VERSION ""

NS_ :

BS_:
BU_: Receiver ChassisBus VehicleBus PartyBus apb ui app aps bms gtwu odin cc cmp cp das dif dir di epas3p epas3s epbl epbr esp fc gtw hvp ibst ocs1p park pcs pmf pmr pm ptc radc rcm2 rcm sccm scm scs tas tpms umc vcfront vcleft vcright vcsec GTW

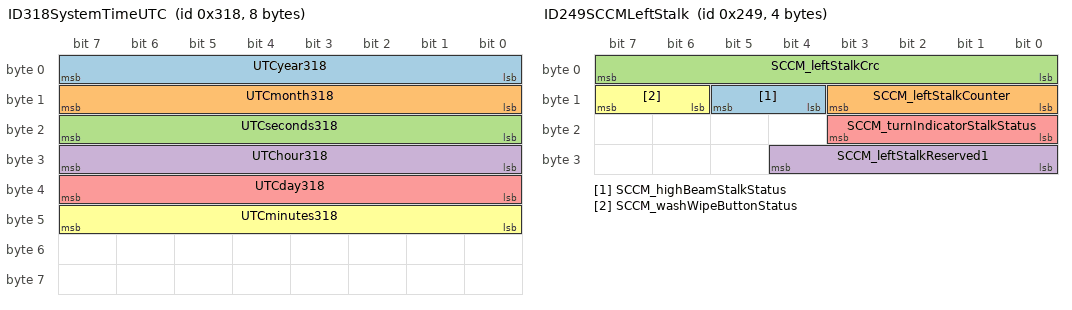
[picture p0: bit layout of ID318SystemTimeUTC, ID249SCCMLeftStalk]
BO_ 792 ID318SystemTimeUTC: 8 VehicleBus
   SG_ UTCyear318 : 0|8@1+ (1,0) [0|0] "yr" Receiver
   SG_ UTCmonth318 : 8|8@1+ (1,0) [0|0] "mo" Receiver
   SG_ UTCseconds318 : 16|8@1+ (1,0) [0|0] "sec" Receiver
   SG_ UTChour318 : 24|8@1+ (1,0) [0|0] "hr" Receiver
   SG_ UTCday318 : 32|8@1+ (1,0) [0|0] "dy" Receiver
   SG_ UTCminutes318 : 40|8@1+ (1,0) [0|0] "min" Receiver

BO_ 1320 ID528UnixTime: 4 VehicleBus
   SG_ UnixTimeSeconds528 : 7|32@0+ (1,0) [0|4.29497e+09] "sec" Receiver

BO_ 553 ID229GearLever: 3 VehicleBus
   SG_ GearLeverPosition229 : 12|3@1+ (1,0) [0|7] "" Receiver
   SG_ GearLeverButton229 : 16|2@1+ (1,0) [0|3] "" Receiver

BO_ 585 ID249SCCMLeftStalk: 4 VehicleBus
   SG_ SCCM_highBeamStalkStatus : 12|2@1+ (1,0) [0|3] "" Receiver
   SG_ SCCM_leftStalkCounter : 8|4@1+ (1,0) [0|15] "" Receiver
   SG_ SCCM_leftStalkCrc : 0|8@1+ (1,0) [0|255] "" Receiver
   SG_ SCCM_leftStalkReserved1 : 24|5@1+ (1,0) [0|31] "" Receiver
   SG_ SCCM_turnIndicatorStalkStatus : 16|4@1+ (1,0) [0|9] "" Receiver
   SG_ SCCM_washWipeButtonStatus : 14|2@1+ (1,0) [0|3] "" Receiver

BO_ 1577 ID629UDSPCStoMCU: 8 VehicleBus

BO_ 1576 ID628UDSMCUtoPCS: 8 VehicleBus

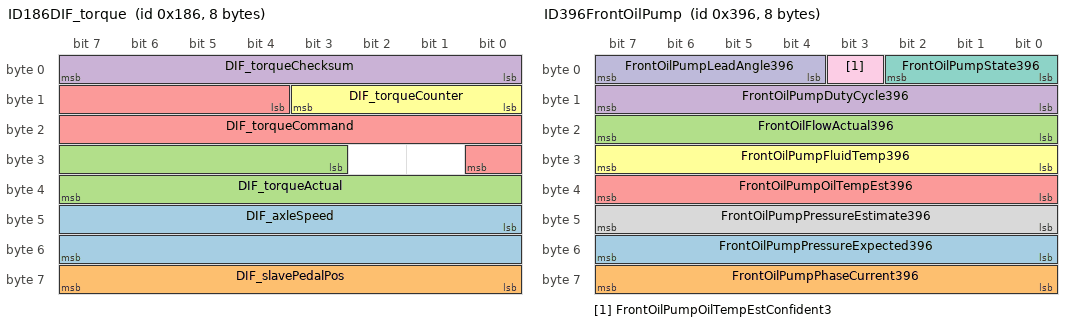
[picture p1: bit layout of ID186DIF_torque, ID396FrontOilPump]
BO_ 390 ID186DIF_torque: 8 VehicleBus
   SG_ DIF_axleSpeed : 40|16@1- (0.1,0) [-2750|2750] "RPM" Receiver
   SG_ DIF_slavePedalPos : 56|8@1+ (0.4,0) [0|100] "%" Receiver
   SG_ DIF_torqueActual : 27|13@1- (2,0) [-7500|7500] "Nm" Receiver
   SG_ DIF_torqueChecksum : 0|8@1+ (1,0) [0|255] "" Receiver
   SG_ DIF_torqueCommand : 12|13@1- (2,0) [-7500|7500] "Nm" Receiver
   SG_ DIF_torqueCounter : 8|4@1+ (1,0) [0|15] "" Receiver

BO_ 918 ID396FrontOilPump: 8 VehicleBus
   SG_ FrontOilPumpPressureExpected396 : 48|8@1+ (2,0) [0|500] "kPa" Receiver
   SG_ FrontOilPumpPhaseCurrent396 : 56|8@1+ (0.1,0) [0|25.4] "A" Receiver
   SG_ FrontOilFlowActual396 : 16|8@1+ (0.06,0) [0|15] "LPM" Receiver
   SG_ FrontOilPumpDutyCycle396 : 8|8@1+ (0.4,0) [0|100] "%" Receiver
   SG_ FrontOilPumpOilTempEst396 : 32|8@1+ (1,-40) [0|214] "C" Receiver
   SG_ FrontOilPumpFluidTemp396 : 24|8@1+ (1,-40) [0|214] "C" Receiver
   SG_ FrontOilPumpState396 : 0|3@1+ (1,0) [0|7] "" Receiver
   SG_ FrontOilPumpPressureEstimate396 : 40|8@1+ (2,0) [0|500] "kPa" Receiver
   SG_ FrontOilPumpOilTempEstConfident3 : 3|1@1+ (1,0) [0|0] "" Receiver
   SG_ FrontOilPumpLeadAngle396 : 4|4@1+ (1.875,0) [0|28.125] "deg" Receiver

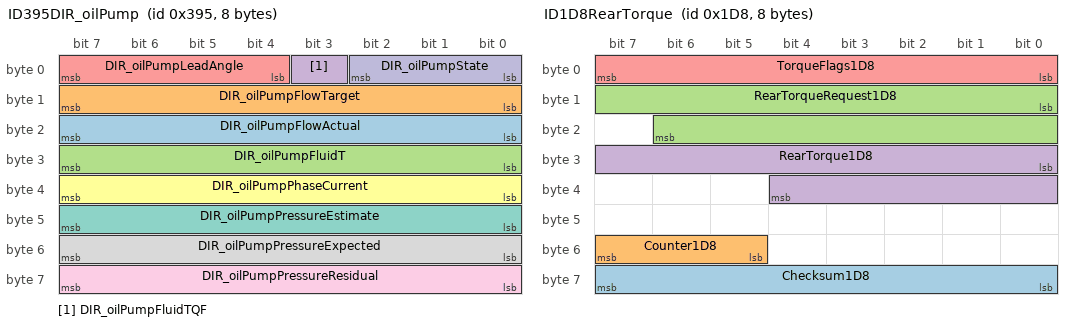
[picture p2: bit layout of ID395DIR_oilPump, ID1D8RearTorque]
BO_ 917 ID395DIR_oilPump: 8 VehicleBus
   SG_ DIR_oilPumpFlowActual : 16|8@1+ (0.06,0) [0|15] "LPM" Receiver
   SG_ DIR_oilPumpFlowTarget : 8|8@1+ (0.06,0) [0|15] "LPM" Receiver
   SG_ DIR_oilPumpFluidT : 24|8@1+ (1,-40) [-40|214] "C" Receiver
   SG_ DIR_oilPumpFluidTQF : 3|1@1+ (1,0) [0|1] "" Receiver
   SG_ DIR_oilPumpLeadAngle : 4|4@1+ (1.875,0) [0|28.125] "deg" Receiver
   SG_ DIR_oilPumpPhaseCurrent : 32|8@1+ (0.1,0) [0|25.4] "A" Receiver
   SG_ DIR_oilPumpPressureEstimate : 40|8@1+ (2,0) [0|500] "kPa" Receiver
   SG_ DIR_oilPumpPressureExpected : 48|8@1+ (2,0) [0|500] "kPa" Receiver
   SG_ DIR_oilPumpPressureResidual : 56|8@1+ (4,-500) [-500|500] "kPa" Receiver
   SG_ DIR_oilPumpState : 0|3@1+ (1,0) [0|7] "" Receiver

BO_ 472 ID1D8RearTorque: 8 VehicleBus
   SG_ Checksum1D8 : 56|8@1+ (1,0) [0|0] "" Receiver
   SG_ Counter1D8 : 53|3@1+ (1,0) [0|0] "" Receiver
   SG_ RearTorqueRequest1D8 : 8|15@1- (0.1,0) [-1638.4|1638.3] "NM" Receiver
   SG_ RearTorque1D8 : 24|13@1- (0.25,0) [-1024|1023.75] "NM" Receiver
   SG_ TorqueFlags1D8 : 0|8@1+ (1,0) [0|0] "" Receiver

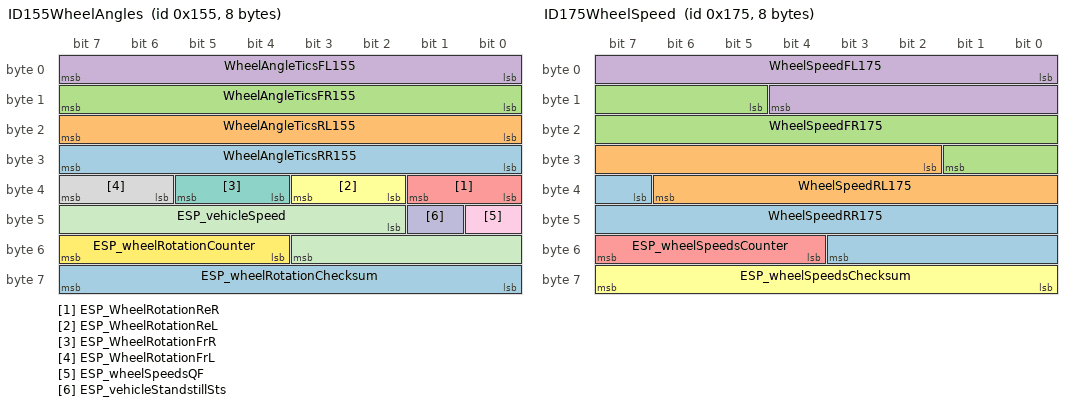
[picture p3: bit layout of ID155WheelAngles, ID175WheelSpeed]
BO_ 341 ID155WheelAngles: 8 ChassisBus
   SG_ WheelAngleTicsRR155 : 24|8@1+ (1.40625,0) [0|358.594] "deg" Receiver
   SG_ WheelAngleTicsRL155 : 16|8@1+ (1.40625,0) [0|358.594] "deg" Receiver
   SG_ WheelAngleTicsFR155 : 8|8@1+ (1.40625,0) [0|358.594] "deg" Receiver
   SG_ WheelAngleTicsFL155 : 0|8@1+ (1.40625,0) [0|358.594] "deg" Receiver
   SG_ ESP_WheelRotationReR : 32|2@1+ (1,0) [0|3] "" Receiver
   SG_ ESP_WheelRotationReL : 34|2@1+ (1,0) [0|3] "" Receiver
   SG_ ESP_WheelRotationFrR : 36|2@1+ (1,0) [0|3] "" Receiver
   SG_ ESP_WheelRotationFrL : 38|2@1+ (1,0) [0|3] "" Receiver
   SG_ ESP_wheelSpeedsQF : 40|1@1+ (1,0) [0|1] "" Receiver
   SG_ ESP_vehicleStandstillSts : 41|1@1+ (1,0) [0|1] "" Receiver
   SG_ ESP_vehicleSpeed : 42|10@1+ (0.5,0) [0|511] "kph" Receiver
   SG_ ESP_wheelRotationCounter : 52|4@1+ (1,0) [0|15] "" Receiver
   SG_ ESP_wheelRotationChecksum : 56|8@1+ (1,0) [0|255] "" Receiver

BO_ 373 ID175WheelSpeed: 8 ChassisBus
   SG_ WheelSpeedRR175 : 39|13@1+ (0.04,0) [0|327.64] "KPH" Receiver
   SG_ WheelSpeedRL175 : 26|13@1+ (0.04,0) [0|327.64] "KPH" Receiver
   SG_ WheelSpeedFR175 : 13|13@1+ (0.04,0) [0|327.64] "KPH" Receiver
   SG_ WheelSpeedFL175 : 0|13@1+ (0.04,0) [0|327.64] "KPH" Receiver
   SG_ ESP_wheelSpeedsCounter : 52|4@1+ (1,0) [0|15] "" Receiver
   SG_ ESP_wheelSpeedsChecksum : 56|8@1+ (1,0) [0|255] "" Receiver

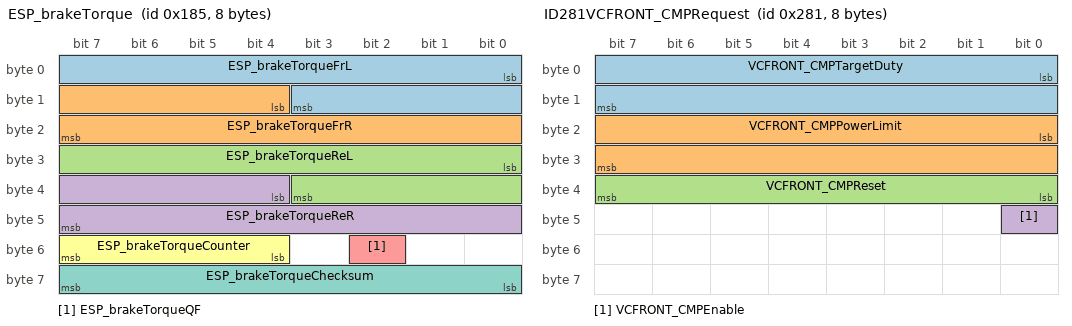
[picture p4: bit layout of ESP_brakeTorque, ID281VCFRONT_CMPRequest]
BO_ 389 ESP_brakeTorque: 8 ChassisBus
   SG_ ESP_brakeTorqueFrL : 0|12@1+ (2,0) [0|8190] "Nm" Receiver
   SG_ ESP_brakeTorqueFrR : 12|12@1+ (2,0) [0|8190] "Nm" Receiver
   SG_ ESP_brakeTorqueReL : 24|12@1+ (2,0) [0|8190] "Nm" Receiver
   SG_ ESP_brakeTorqueReR : 36|12@1+ (2,0) [0|8190] "Nm" Receiver
   SG_ ESP_brakeTorqueQF : 50|1@1+ (1,0) [0|1] "" Receiver
   SG_ ESP_brakeTorqueCounter : 52|4@1+ (1,0) [0|15] "" Receiver
   SG_ ESP_brakeTorqueChecksum : 56|8@1+ (1,0) [0|255] "" Receiver

BO_ 468 ID1D4FrontTorqueOld: 8 VehicleBus
   SG_ RAWTorqueFront1D4 : 40|12@1- (0.25,0) [-512|511.75] "NM" Receiver

BO_ 469 ID1D5FrontTorque: 8 VehicleBus
   SG_ FrontTorqueRequest1D5 : 8|15@1- (0.1,0) [-1638.4|1638.3] "NM" Receiver
   SG_ FrontTorque1D5 : 24|13@1- (0.25,0) [-1024|1023.75] "NM" Receiver

BO_ 641 ID281VCFRONT_CMPRequest: 8 VehicleBus
   SG_ VCFRONT_CMPTargetDuty : 0|16@1+ (0.1,0) [0|100] "%" Receiver
   SG_ VCFRONT_CMPPowerLimit : 16|16@1+ (1,0) [0|65534] "W" Receiver
   SG_ VCFRONT_CMPReset : 32|8@1+ (1,0) [0|255] "" Receiver
   SG_ VCFRONT_CMPEnable : 40|1@1+ (1,0) [0|1] "" Receiver

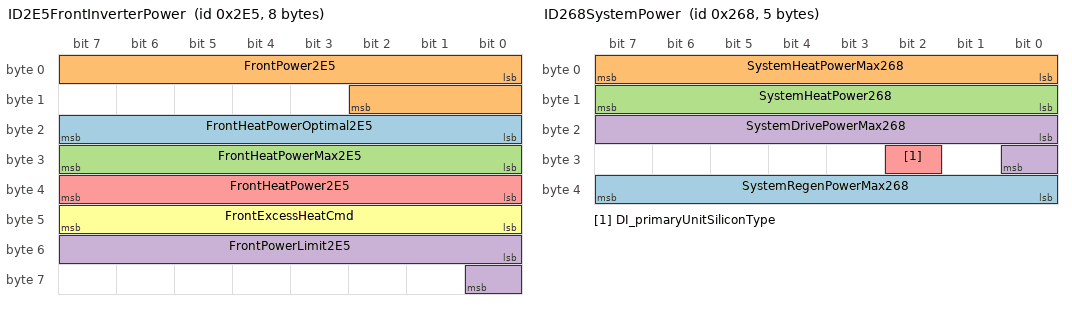
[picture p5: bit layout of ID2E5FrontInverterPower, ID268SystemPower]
BO_ 741 ID2E5FrontInverterPower: 8 VehicleBus
   SG_ FrontHeatPowerOptimal2E5 : 16|8@1+ (0.08,0) [0|20.4] "kW" Receiver
   SG_ FrontPower2E5 : 0|11@1- (0.5,0) [-512|511.5] "kW" Receiver
   SG_ FrontHeatPowerMax2E5 : 24|8@1+ (0.08,0) [0|20.4] "kW" Receiver
   SG_ FrontPowerLimit2E5 : 48|9@1+ (1,0) [0|400] "kW" Receiver
   SG_ FrontHeatPower2E5 : 32|8@1+ (0.08,0) [0|20.4] "kW" Receiver
   SG_ FrontExcessHeatCmd : 40|8@1+ (0.08,0) [0|20] "kW" Receiver

BO_ 962 ID3C2VCLEFT_switchStatus: 8 VehicleBus
   SG_ VCLEFT_switchStatusIndex M : 0|2@1+ (1,0) [0|2] "" Receiver
   SG_ VCLEFT_2RowSeatBothFoldFlatSwitc m1 : 40|1@1+ (1,0) [0|1] "" Receiver
   SG_ VCLEFT_2RowSeatCenterSwitch m1 : 37|1@1+ (1,0) [0|1] "" Receiver
   SG_ VCLEFT_2RowSeatLeftFoldFlatSwitc m1 : 38|1@1+ (1,0) [0|1] "" Receiver
   SG_ VCLEFT_2RowSeatReclineSwitch m1 : 36|1@1+ (1,0) [0|1] "" Receiver
   SG_ VCLEFT_2RowSeatRightFoldFlatSwit m1 : 39|1@1+ (1,0) [0|1] "" Receiver
   SG_ VCLEFT_brakePressed m0 : 60|1@1+ (1,0) [0|1] "" Receiver
   SG_ VCLEFT_brakeSwitchPressed m0 : 4|1@1+ (1,0) [0|1] "" Receiver
   SG_ VCLEFT_btnWindowAutoDownLR m1 : 35|1@1+ (1,0) [0|1] "" Receiver
   SG_ VCLEFT_btnWindowAutoUpLR m1 : 33|1@1+ (1,0) [0|1] "" Receiver
   SG_ VCLEFT_btnWindowDownLR m1 : 34|1@1+ (1,0) [0|1] "" Receiver
   SG_ VCLEFT_btnWindowSwPackAutoDownLF m0 : 35|1@1+ (1,0) [0|1] "" Receiver
   SG_ VCLEFT_btnWindowSwPackAutoDownLR m0 : 39|1@1+ (1,0) [0|1] "" Receiver
   SG_ VCLEFT_btnWindowSwPackAutoDownRF m0 : 43|1@1+ (1,0) [0|1] "" Receiver
   SG_ VCLEFT_btnWindowSwPackAutoDownRR m0 : 47|1@1+ (1,0) [0|1] "" Receiver
   SG_ VCLEFT_btnWindowSwPackAutoUpLF m0 : 33|1@1+ (1,0) [0|1] "" Receiver
   SG_ VCLEFT_btnWindowSwPackAutoUpLR m0 : 37|1@1+ (1,0) [0|1] "" Receiver
   SG_ VCLEFT_btnWindowSwPackAutoUpRF m0 : 41|1@1+ (1,0) [0|1] "" Receiver
   SG_ VCLEFT_btnWindowSwPackAutoUpRR m0 : 45|1@1+ (1,0) [0|1] "" Receiver
   SG_ VCLEFT_btnWindowSwPackDownLF m0 : 34|1@1+ (1,0) [0|1] "" Receiver
   SG_ VCLEFT_btnWindowSwPackDownLR m0 : 38|1@1+ (1,0) [0|1] "" Receiver
   SG_ VCLEFT_btnWindowSwPackDownRF m0 : 42|1@1+ (1,0) [0|1] "" Receiver
   SG_ VCLEFT_btnWindowSwPackDownRR m0 : 46|1@1+ (1,0) [0|1] "" Receiver
   SG_ VCLEFT_btnWindowSwPackUpLF m0 : 32|1@1+ (1,0) [0|1] "" Receiver
   SG_ VCLEFT_btnWindowSwPackUpLR m0 : 36|1@1+ (1,0) [0|1] "" Receiver
   SG_ VCLEFT_btnWindowSwPackUpRF m0 : 40|1@1+ (1,0) [0|1] "" Receiver
   SG_ VCLEFT_btnWindowSwPackUpRR m0 : 44|1@1+ (1,0) [0|1] "" Receiver
   SG_ VCLEFT_btnWindowUpLR m1 : 32|1@1+ (1,0) [0|1] "" Receiver
   SG_ VCLEFT_frontBuckleSwitch m0 : 48|2@1+ (1,0) [0|3] "" Receiver
   SG_ VCLEFT_frontOccupancySwitch m0 : 50|2@1+ (1,0) [0|3] "" Receiver
   SG_ VCLEFT_frontSeatBackrestBack m0 : 20|2@1+ (1,0) [0|3] "" Receiver
   SG_ VCLEFT_frontSeatBackrestForward m0 : 22|2@1+ (1,0) [0|3] "" Receiver
   SG_ VCLEFT_frontSeatLiftDown m0 : 16|2@1+ (1,0) [0|3] "" Receiver
   SG_ VCLEFT_frontSeatLiftUp m0 : 18|2@1+ (1,0) [0|3] "" Receiver
   SG_ VCLEFT_frontSeatLumbarDown m0 : 24|2@1+ (1,0) [0|3] "" Receiver
   SG_ VCLEFT_frontSeatLumbarIn m0 : 28|2@1+ (1,0) [0|3] "" Receiver
   SG_ VCLEFT_frontSeatLumbarOut m0 : 30|2@1+ (1,0) [0|3] "" Receiver
   SG_ VCLEFT_frontSeatLumbarUp m0 : 26|2@1+ (1,0) [0|3] "" Receiver
   SG_ VCLEFT_frontSeatTiltDown m0 : 12|2@1+ (1,0) [0|3] "" Receiver
   SG_ VCLEFT_frontSeatTiltUp m0 : 14|2@1+ (1,0) [0|3] "" Receiver
   SG_ VCLEFT_frontSeatTrackBack m0 : 8|2@1+ (1,0) [0|3] "" Receiver
   SG_ VCLEFT_frontSeatTrackForward m0 : 10|2@1+ (1,0) [0|3] "" Receiver
   SG_ VCLEFT_hazardButtonPressed m0 : 3|1@1+ (1,0) [0|1] "" Receiver
   SG_ VCLEFT_hornSwitchPressed m0 : 2|1@1+ (1,0) [0|1] "" Receiver
   SG_ VCLEFT_rearCenterBuckleSwitch m0 : 62|2@1+ (1,0) [0|3] "" Receiver
   SG_ VCLEFT_rearCenterOccupancySwitch m0 : 54|2@1+ (1,0) [0|3] "" Receiver
   SG_ VCLEFT_rearHVACButtonPressed m0 : 61|1@1+ (1,0) [0|1] "" Receiver
   SG_ VCLEFT_rearLeftBuckleSwitch m0 : 52|2@1+ (1,0) [0|3] "" Receiver
   SG_ VCLEFT_rearLeftOccupancySwitch m0 : 56|2@1+ (1,0) [0|3] "" Receiver
   SG_ VCLEFT_rearRightOccupancySwitch m0 : 58|2@1+ (1,0) [0|3] "" Receiver
   SG_ VCLEFT_rightMirrorTilt m0 : 5|3@1+ (1,0) [0|4] "" Receiver
   SG_ VCLEFT_swcLeftDoublePress m1 : 41|1@1+ (1,0) [0|1] "" Receiver
   SG_ VCLEFT_swcLeftPressed m1 : 5|2@1+ (1,0) [0|3] "" Receiver
   SG_ VCLEFT_swcLeftScrollTicks m1 : 16|6@1- (1,0) [-32|31] "" Receiver
   SG_ VCLEFT_swcLeftTiltLeft m1 : 14|2@1+ (1,0) [0|3] "" Receiver
   SG_ VCLEFT_swcLeftTiltRight m1 : 3|2@1+ (1,0) [0|3] "" Receiver
   SG_ VCLEFT_swcRightDoublePress m1 : 42|1@1+ (1,0) [0|1] "" Receiver
   SG_ VCLEFT_swcRightPressed m1 : 12|2@1+ (1,0) [0|3] "" Receiver
   SG_ VCLEFT_swcRightScrollTicks m1 : 24|6@1- (1,0) [-32|31] "" Receiver
   SG_ VCLEFT_swcRightTiltLeft m1 : 8|2@1+ (1,0) [0|3] "" Receiver
   SG_ VCLEFT_swcRightTiltRight m1 : 10|2@1+ (1,0) [0|3] "" Receiver

BO_ 822 ID336MaxPowerRating: 3 VehicleBus
   SG_ DriveRegenRating336 : 16|8@1+ (1,-100) [-100|155] "kW" Receiver
   SG_ DrivePowerRating336 : 0|10@1+ (1,0) [0|600] "kW" Receiver

BO_ 659 ID293UI_chassisControl: 8 VehicleBus
   SG_ UI_accOvertakeEnable : 16|2@1+ (1,0) [0|3] "" Receiver
   SG_ UI_aebEnable : 18|2@1+ (1,0) [0|3] "" Receiver
   SG_ UI_aesEnable : 20|2@1+ (1,0) [0|3] "" Receiver
   SG_ UI_ahlbEnable : 22|2@1+ (1,0) [0|3] "" Receiver
   SG_ UI_autoLaneChangeEnable : 24|2@1+ (1,0) [0|3] "" Receiver
   SG_ UI_autoParkRequest : 28|4@1+ (1,0) [0|15] "" Receiver
   SG_ UI_bsdEnable : 32|2@1+ (1,0) [0|3] "" Receiver
   SG_ UI_chassisControlChecksum : 56|8@1+ (1,0) [0|255] "" Receiver
   SG_ UI_chassisControlCounter : 52|4@1+ (1,0) [0|15] "" Receiver
   SG_ UI_dasDebugEnable : 14|1@1+ (1,0) [0|1] "" Receiver
   SG_ UI_distanceUnits : 13|1@1+ (1,0) [0|1] "" Receiver
   SG_ UI_fcwEnable : 34|2@1+ (1,0) [0|3] "" Receiver
   SG_ UI_fcwSensitivity : 36|2@1+ (1,0) [0|3] "" Receiver
   SG_ UI_latControlEnable : 38|2@1+ (1,0) [0|3] "" Receiver
   SG_ UI_ldwEnable : 40|2@1+ (1,0) [0|3] "" Receiver
   SG_ UI_narrowGarages : 7|1@1+ (1,0) [0|1] "" Receiver
   SG_ UI_parkBrakeRequest : 5|2@1+ (1,0) [0|3] "" Receiver
   SG_ UI_pedalSafetyEnable : 42|2@1+ (1,0) [0|3] "" Receiver
   SG_ UI_rebootAutopilot : 27|1@1+ (1,0) [0|1] "" Receiver
   SG_ UI_redLightStopSignEnable : 46|2@1+ (1,0) [0|3] "" Receiver
   SG_ UI_selfParkTune : 48|4@1+ (1,0) [0|15] "" Receiver
   SG_ UI_steeringTuneRequest : 0|2@1+ (1,0) [0|2] "" Receiver
   SG_ UI_tractionControlMode : 2|3@1+ (1,0) [0|6] "" Receiver
   SG_ UI_trailerMode : 12|1@1+ (1,0) [0|1] "" Receiver
   SG_ UI_winchModeRequest : 8|2@1+ (1,0) [0|2] "" Receiver
   SG_ UI_zeroSpeedConfirmed : 10|2@1+ (1,0) [0|3] "" Receiver

BO_ 616 ID268SystemPower: 5 VehicleBus
   SG_ SystemRegenPowerMax268 : 32|8@1+ (1,-100) [-100|155] "kW" Receiver
   SG_ SystemHeatPowerMax268 : 0|8@1+ (0.08,0) [0|31875] "kW" Receiver
   SG_ SystemHeatPower268 : 8|8@1+ (0.08,0) [0|31875] "kW" Receiver
   SG_ SystemDrivePowerMax268 : 16|9@1+ (1,0) [0|511] "kW" Receiver
   SG_ DI_primaryUnitSiliconType : 26|1@1+ (1,0) [0|1] "" Receiver

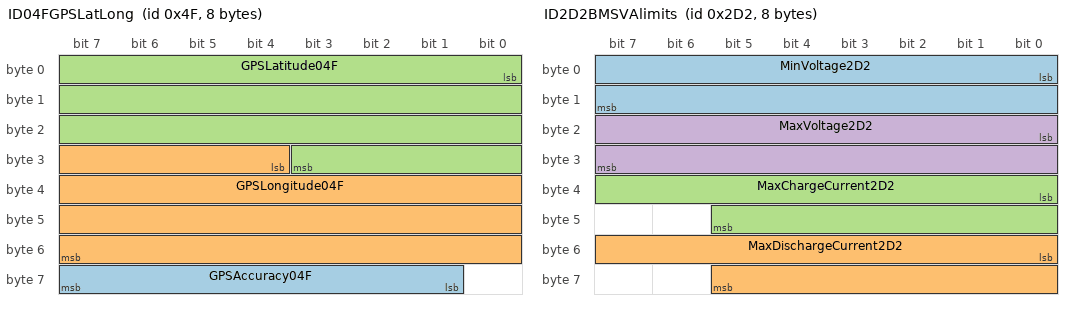
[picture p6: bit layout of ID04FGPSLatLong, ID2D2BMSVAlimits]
BO_ 79 ID04FGPSLatLong: 8 ChassisBus
   SG_ GPSAccuracy04F : 57|7@1+ (0.2,0) [0|25.2] "m" Receiver
   SG_ GPSLongitude04F : 28|28@1- (1e-06,0) [-134.218|134.218] "Deg" Receiver
   SG_ GPSLatitude04F : 0|28@1- (1e-06,0) [-134.218|134.218] "Deg" Receiver

BO_ 978 ID3D2TotalChargeDischarge: 8 VehicleBus
   SG_ TotalDischargeKWh3D2 : 0|32@1+ (0.001,0) [0|4.29497e+06] "kWh" Receiver
   SG_ TotalChargeKWh3D2 : 32|32@1+ (0.001,0) [0|4.29497e+06] "kWh" Receiver

BO_ 1010 ID3F2BMSCounters: 8 VehicleBus
   SG_ BMSCountersIndex3F2 M : 0|3@1+ (1,0) [0|0] "" Receiver
   SG_ BMStotalACcharge3F2 m0 : 8|32@1+ (0.001,0) [0|4.29497e+06] "KWh" Receiver
   SG_ BMStotalDCcharge3F2 m1 : 8|32@1+ (0.001,0) [0|4.29497e+06] "KWh" Receiver
   SG_ BMStotalRegenCharge3F2 m2 : 8|32@1+ (0.001,0) [0|4.29497e+06] "KWh" Receiver
   SG_ BMStotalDriveDischarge3F2 m3 : 8|32@1+ (0.001,0) [0|4.29497e+06] "KWh" Receiver

BO_ 722 ID2D2BMSVAlimits: 8 VehicleBus
   SG_ MinVoltage2D2 : 0|16@1+ (0.01,0) [0|430] "V" Receiver
   SG_ MaxDischargeCurrent2D2 : 48|14@1+ (0.128,0) [0|2096.9] "A" Receiver
   SG_ MaxChargeCurrent2D2 : 32|14@1+ (0.1,0) [0|1638.2] "A" Receiver
   SG_ MaxVoltage2D2 : 16|16@1+ (0.01,0) [0|430] "V" Receiver

BO_ 1345 ID541FastChargeMaxLimits: 8 VehicleBus
   SG_ FCMaxPowerLimit541 : 0|13@1+ (0.062256,0) [0|509.939] "kW" Receiver
   SG_ FCMaxCurrentLimit541 : 16|13@1+ (0.073242,0) [0|599.925] "A" Receiver

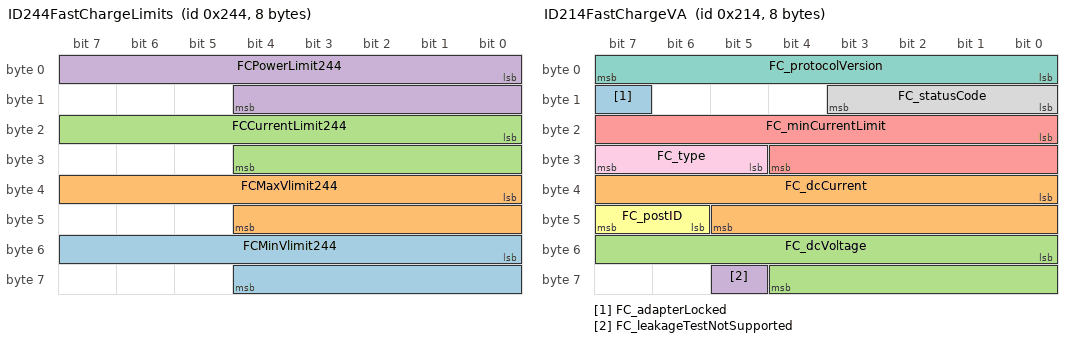
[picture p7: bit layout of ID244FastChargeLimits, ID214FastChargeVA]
BO_ 580 ID244FastChargeLimits: 8 VehicleBus
   SG_ FCMinVlimit244 : 48|13@1+ (0.073242,0) [0|599.925] "V" Receiver
   SG_ FCMaxVlimit244 : 32|13@1+ (0.073242,0) [0|599.925] "V" Receiver
   SG_ FCCurrentLimit244 : 16|13@1+ (0.073242,0) [0|599.925] "A" Receiver
   SG_ FCPowerLimit244 : 0|13@1+ (0.062256,0) [0|509.939] "kW" Receiver

BO_ 532 ID214FastChargeVA: 8 VehicleBus
   SG_ FC_adapterLocked : 15|1@1+ (1,0) [0|1] "" Receiver
   SG_ FC_dcCurrent : 32|14@1- (0.0732422,0) [-600|599.927] "A" Receiver
   SG_ FC_dcVoltage : 48|13@1+ (0.0732422,0) [0|599.927] "V" Receiver
   SG_ FC_leakageTestNotSupported : 61|1@1+ (1,0) [0|1] "" Receiver
   SG_ FC_minCurrentLimit : 16|13@1+ (0.1,0) [0|600] "A" Receiver
   SG_ FC_postID : 46|2@1+ (1,0) [0|3] "" Receiver
   SG_ FC_protocolVersion : 0|8@1+ (1,0) [0|255] "" Receiver
   SG_ FC_statusCode : 8|4@1+ (1,0) [0|15] "" Receiver
   SG_ FC_type : 29|3@1+ (1,0) [0|7] "" Receiver

BO_ 533 ID215FCisolation: 1 VehicleBus
   SG_ FCIsolation215 : 0|8@1+ (40,0) [0|10200] "kOhm" Receiver

BO_ 535 ID217FCinfo: 8 VehicleBus
   SG_ FCinfoMux217 M : 0|7@1+ (1,0) [0|127] "" Receiver
   SG_ FCclass217 m0 : 8|8@1+ (1,0) [0|255] "" Receiver
   SG_ FCbrand217 m0 : 16|4@1+ (1,0) [0|15] "" Receiver
   SG_ FCcoolingType217 m0 : 20|4@1+ (1,0) [0|15] "" Receiver
   SG_ FCuiStopType217 m0 : 24|4@1+ (1,0) [0|15] "" Receiver

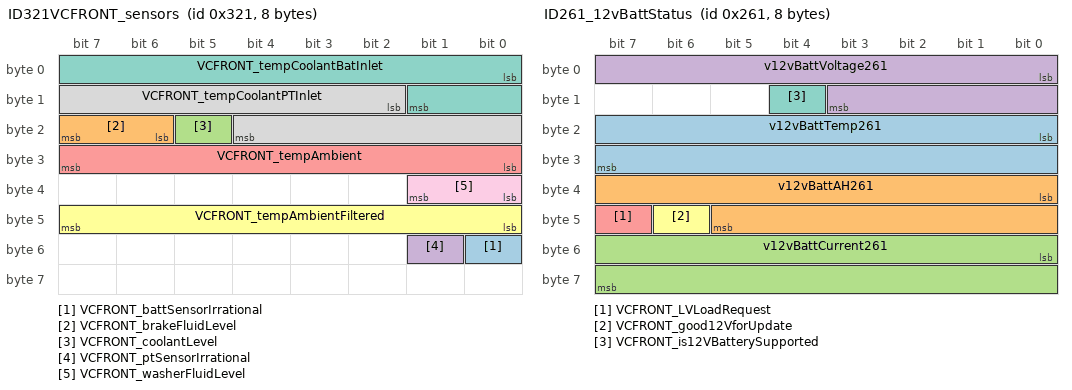
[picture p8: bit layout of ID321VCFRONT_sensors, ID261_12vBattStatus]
BO_ 801 ID321VCFRONT_sensors: 8 VehicleBus
   SG_ VCFRONT_battSensorIrrational : 48|1@1+ (1,0) [0|1] "" Receiver
   SG_ VCFRONT_brakeFluidLevel : 22|2@1+ (1,0) [0|2] "" Receiver
   SG_ VCFRONT_coolantLevel : 21|1@1+ (1,0) [0|1] "" Receiver
   SG_ VCFRONT_ptSensorIrrational : 49|1@1+ (1,0) [0|1] "" Receiver
   SG_ VCFRONT_tempAmbient : 24|8@1+ (0.5,-40) [-40|80] "C" Receiver
   SG_ VCFRONT_tempAmbientFiltered : 40|8@1+ (0.5,-40) [-40|80] "C" Receiver
   SG_ VCFRONT_tempCoolantBatInlet : 0|10@1+ (0.125,-40) [-40|85] "C" Receiver
   SG_ VCFRONT_tempCoolantPTInlet : 10|11@1+ (0.125,-40) [-40|200] "C" Receiver
   SG_ VCFRONT_washerFluidLevel : 32|2@1+ (1,0) [0|2] "" Receiver

BO_ 769 ID301VCFRONT_info: 8 VehicleBus
   SG_ VCFRONT_infoIndex M : 0|8@1+ (1,0) [0|255] "" Receiver
   SG_ VCFRONT_hcmlAppCRC m16 : 32|32@1+ (1,0) [0|4.29497e+09] "" Receiver
   SG_ VCFRONT_hcmrAppCRC m23 : 32|32@1+ (1,0) [0|4.29497e+09] "" Receiver
   SG_ VCFRONT_infoAppCrc m13 : 8|32@1+ (1,0) [0|4.29497e+09] "" Receiver
   SG_ VCFRONT_infoAppGitHash m17 : 8|56@1+ (1,0) [0|7.20576e+16] "" Receiver
   SG_ VCFRONT_infoAssemblyId m11 : 16|8@1+ (1,0) [0|255] "" Receiver
   SG_ VCFRONT_infoBootCrc m20 : 24|32@1+ (1,0) [0|4.29497e+09] "" Receiver
   SG_ VCFRONT_infoBootGitHash m18 : 8|56@1+ (1,0) [0|7.20576e+16] "" Receiver
   SG_ VCFRONT_infoBootUdsProtoVersion m20 : 8|16@1+ (1,0) [0|65535] "" Receiver
   SG_ VCFRONT_infoBuildConfigId m10 : 16|16@1+ (1,0) [0|65535] "" Receiver
   SG_ VCFRONT_infoBuildType m10 : 8|3@1+ (1,0) [0|4] "" Receiver
   SG_ VCFRONT_infoComponentId m10 : 48|16@1+ (1,0) [0|65535] "" Receiver
   SG_ VCFRONT_infoHardwareId m10 : 32|16@1+ (1,0) [0|65535] "" Receiver
   SG_ VCFRONT_infoPcbaId m11 : 8|8@1+ (1,0) [0|255] "" Receiver
   SG_ VCFRONT_infoPlatformType m19 : 8|8@1+ (1,0) [0|255] "" Receiver
   SG_ VCFRONT_infoSubUsageId m11 : 40|16@1+ (1,0) [0|65535] "" Receiver
   SG_ VCFRONT_infoSubcomponent3 m24 : 32|32@1+ (1,0) [0|4.29497e+09] "" Receiver
   SG_ VCFRONT_infoSubcomponent4 m31 : 32|32@1+ (1,0) [0|4.29497e+09] "" Receiver
   SG_ VCFRONT_infoSubcomponent5 m32 : 32|32@1+ (1,0) [0|4.29497e+09] "" Receiver
   SG_ VCFRONT_infoSubcomponent6 m33 : 32|32@1+ (1,0) [0|4.29497e+09] "" Receiver
   SG_ VCFRONT_infoUsageId m11 : 24|16@1+ (1,0) [0|65535] "" Receiver

BO_ 513 ID201VCFRONT_loggingAndVitals10H: 8 VehicleBus
   SG_ VCFRONT_loggingAndVitals10HzInde M : 0|3@1+ (1,0) [0|7] "" Receiver
   SG_ VCFRONT_activeLouverOpenPos m1 : 16|7@1+ (1,0) [0|100] "%" Receiver
   SG_ VCFRONT_activeLouverOpenPosTarg m1 : 8|7@1+ (1,0) [0|100] "%" Receiver
   SG_ VCFRONT_cclExvFlow m3 : 44|10@1+ (0.1,0) [0|100] "%" Receiver
   SG_ VCFRONT_cclExvFlowTarget m5 : 44|10@1+ (0.1,0) [0|100] "%" Receiver
   SG_ VCFRONT_cclExvState m6 : 20|4@1+ (1,0) [0|8] "" Receiver
   SG_ VCFRONT_ccrExvFlow m3 : 54|10@1+ (0.1,0) [0|100] "%" Receiver
   SG_ VCFRONT_ccrExvFlowTarget m5 : 54|10@1+ (0.1,0) [0|100] "%" Receiver
   SG_ VCFRONT_ccrExvState m6 : 24|4@1+ (1,0) [0|8] "" Receiver
   SG_ VCFRONT_chillerExvFlow m3 : 3|10@1+ (0.1,0) [0|100] "%" Receiver
   SG_ VCFRONT_chillerExvFlowTarget m5 : 3|10@1+ (0.1,0) [0|100] "%" Receiver
   SG_ VCFRONT_chillerExvState m6 : 3|4@1+ (1,0) [0|8] "" Receiver
   SG_ VCFRONT_compDemandChiller m2 : 39|7@1+ (1,0) [0|100] "%" Receiver
   SG_ VCFRONT_compDemandEvap m2 : 26|7@1+ (1,0) [0|100] "%" Receiver
   SG_ VCFRONT_compressorState m2 : 24|2@1+ (1,0) [0|3] "" Receiver
   SG_ VCFRONT_coolantValveMode m2 : 61|2@1+ (1,0) [0|3] "" Receiver
   SG_ VCFRONT_evapExvFlow m3 : 13|10@1+ (0.1,0) [0|100] "%" Receiver
   SG_ VCFRONT_evapExvFlowTarget m5 : 13|10@1+ (0.1,0) [0|100] "%" Receiver
   SG_ VCFRONT_evapExvState m6 : 8|4@1+ (1,0) [0|8] "" Receiver
   SG_ VCFRONT_exvFlowTarget m0 : 54|10@1+ (0.1,0) [0|100] "%" Receiver
   SG_ VCFRONT_exvState m2 : 33|4@1+ (1,0) [0|8] "" Receiver
   SG_ VCFRONT_fanDemand m2 : 16|7@1+ (1,0) [0|100] "%" Receiver
   SG_ VCFRONT_hpBatteryLoadType m4 : 16|2@1+ (1,0) [0|2] "" Receiver
   SG_ VCFRONT_hpBlendType m4 : 11|2@1+ (1,0) [0|2] "" Receiver
   SG_ VCFRONT_hpCabinLoadType m4 : 14|2@1+ (1,0) [0|3] "" Receiver
   SG_ VCFRONT_hpDominantLoad m4 : 8|3@1+ (1,0) [0|6] "" Receiver
   SG_ VCFRONT_hpHighSideHX m4 : 3|2@1+ (1,0) [0|3] "" Receiver
   SG_ VCFRONT_hpLowSideHX m4 : 5|2@1+ (1,0) [0|3] "" Receiver
   SG_ VCFRONT_hpQuietModeEnabled m4 : 13|1@1+ (1,0) [0|1] "" Receiver
   SG_ VCFRONT_hpReqCoolantMode m4 : 18|3@1+ (1,0) [0|4] "" Receiver
   SG_ VCFRONT_lccExvFlow m3 : 34|10@1+ (0.1,0) [0|100] "%" Receiver
   SG_ VCFRONT_lccExvFlowTarget m5 : 34|10@1+ (0.1,0) [0|100] "%" Receiver
   SG_ VCFRONT_lccExvState m6 : 16|4@1+ (1,0) [0|8] "" Receiver
   SG_ VCFRONT_pressureRefrigDischargeV m2 : 53|8@1+ (0.125,0) [0|31.75] "bar" Receiver
   SG_ VCFRONT_pressureRefrigLiquid m1 : 40|8@1+ (0.125,0) [0|31.75] "bar" Receiver
   SG_ VCFRONT_pressureRefrigSuctionVit m2 : 46|7@1+ (0.125,0) [0|11.5] "bar" Receiver
   SG_ VCFRONT_pumpBatteryRPMActual m0 : 3|10@1+ (10,0) [0|10000] "rpm" Receiver
   SG_ VCFRONT_pumpPowertrainRPMActual m0 : 13|10@1+ (10,0) [0|10000] "rpm" Receiver
   SG_ VCFRONT_radiatorFanRPMActual m0 : 24|10@1+ (10,0) [0|10000] "rpm" Receiver
   SG_ VCFRONT_recircExvFlow m3 : 24|10@1+ (0.1,0) [0|100] "%" Receiver
   SG_ VCFRONT_recircExvFlowTarget m5 : 24|10@1+ (0.1,0) [0|100] "%" Receiver
   SG_ VCFRONT_recircExvState m6 : 12|4@1+ (1,0) [0|8] "" Receiver
   SG_ VCFRONT_solenoidEvapState m2 : 37|2@1+ (1,0) [0|3] "" Receiver
   SG_ VCFRONT_tempRefrigDischarge m2 : 3|11@1+ (0.125,-40) [-40|150] "C" Receiver
   SG_ VCFRONT_tempRefrigLiquid m1 : 24|11@1+ (0.125,-40) [-40|150] "C" Receiver
   SG_ VCFRONT_tempSuperheatActFiltered m1 : 48|8@1- (0.25,26.5) [-5|58] "C" Receiver
   SG_ VCFRONT_tempSuperheatActual m0 : 34|10@1+ (0.1,-20) [-20|80] "C" Receiver
   SG_ VCFRONT_tempSuperheatTarget m0 : 44|10@1+ (0.1,0) [0|60] "C" Receiver

BO_ 984 ID3D8Elevation: 2 VehicleBus
   SG_ Elevation3D8 : 0|14@1- (1,0) [-8192|8191] "M" Receiver

BO_ 609 ID261_12vBattStatus: 8 VehicleBus
   SG_ v12vBattTemp261 : 16|16@1- (0.01,0) [-327.68|327.66] "C" Receiver
   SG_ v12vBattAH261 : 32|14@1- (0.005,0) [-40.96|40.955] "AH" Receiver
   SG_ v12vBattCurrent261 : 48|16@1- (0.005,0) [-163.84|163.835] "A" Receiver
   SG_ v12vBattVoltage261 : 0|12@1+ (0.00544368,0) [0|22.2919] "V" Receiver
   SG_ VCFRONT_LVLoadRequest : 47|1@1+ (1,0) [0|1] "" Receiver
   SG_ VCFRONT_good12VforUpdate : 46|1@1+ (1,0) [0|1] "" Receiver
   SG_ VCFRONT_is12VBatterySupported : 12|1@1+ (1,0) [0|1] "" Receiver

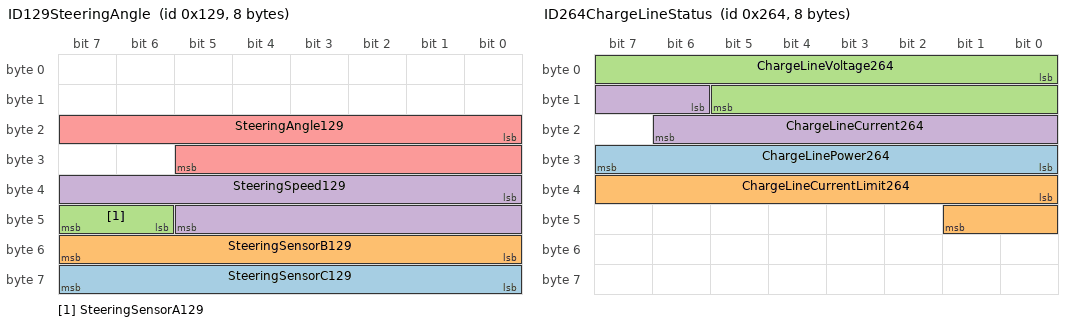
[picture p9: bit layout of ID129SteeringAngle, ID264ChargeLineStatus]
BO_ 297 ID129SteeringAngle: 8 VehicleBus
   SG_ SteeringSensorC129 : 56|8@1+ (1,0) [0|255] "" Receiver
   SG_ SteeringSensorB129 : 48|8@1+ (1,0) [0|255] "" Receiver
   SG_ SteeringSensorA129 : 46|2@1+ (1,0) [0|3] "" Receiver
   SG_ SteeringSpeed129 : 32|14@1+ (0.5,-4096) [-4096|4095.5] "D/S" Receiver
   SG_ SteeringAngle129 : 16|14@1+ (0.1,-819.2) [-819.2|819.1] "Deg" Receiver

BO_ 612 ID264ChargeLineStatus: 8 VehicleBus
   SG_ ChargeLinePower264 : 24|8@1+ (0.1,0) [0|25.5] "kW" Receiver
   SG_ ChargeLineCurrentLimit264 : 32|10@1+ (0.1,0) [0|102.3] "A" Receiver
   SG_ ChargeLineVoltage264 : 0|14@1+ (0.0333,0) [0|545.554] "V" Receiver
   SG_ ChargeLineCurrent264 : 14|9@1+ (0.1,0) [0|51.1] "A" Receiver

BO_ 548 ID224PCSDCDCstatus: 8 VehicleBus
   SG_ DCDC12VSupportRtyCnt224 : 44|4@1+ (1,0) [0|0] "" Receiver
   SG_ DCDC12VSupportStatus224 : 2|2@1+ (1,0) [0|0] "" Receiver
   SG_ DCDCDischargeRtyCnt224 : 48|4@1+ (1,0) [0|0] "" Receiver
   SG_ DCDCFaulted224 : 15|1@1+ (1,0) [0|0] "" Receiver
   SG_ DCDCHvBusDischargeStatus224 : 4|2@1+ (1,0) [0|0] "" Receiver
   SG_ DCDCInitialPrechargeSubState224 : 59|5@1+ (1,0) [0|0] "" Receiver
   SG_ DCDCoutputCurrent224 : 16|12@1+ (0.1,0) [0|409.5] "A" Receiver
   SG_ DCDCstate224 : 6|4@1+ (1,0) [0|0] "" Receiver
   SG_ DCDCoutputCurrentMax224 : 29|12@1+ (0.1,0) [0|409.5] "A" Receiver
   SG_ DCDCOutputIsLimited224 : 28|1@1+ (1,0) [0|0] "" Receiver
   SG_ DCDCPrechargeRestartCnt224 : 56|3@1+ (1,0) [0|0] "" Receiver
   SG_ DCDCPrechargeRtyCnt224 : 41|3@1+ (1,0) [0|0] "" Receiver
   SG_ DCDCPrechargeStatus224 : 0|2@1+ (1,0) [0|0] "" Receiver
   SG_ DCDCPwmEnableLine224 : 52|1@1+ (1,0) [0|0] "" Receiver
   SG_ DCDCSubState224 : 10|5@1+ (1,0) [0|0] "" Receiver
   SG_ DCDCSupportingFixedLvTarget224 : 53|1@1+ (1,0) [0|0] "" Receiver
   SG_ PCS_ecuLogUploadRequest224 : 54|2@1+ (1,0) [0|0] "" Receiver

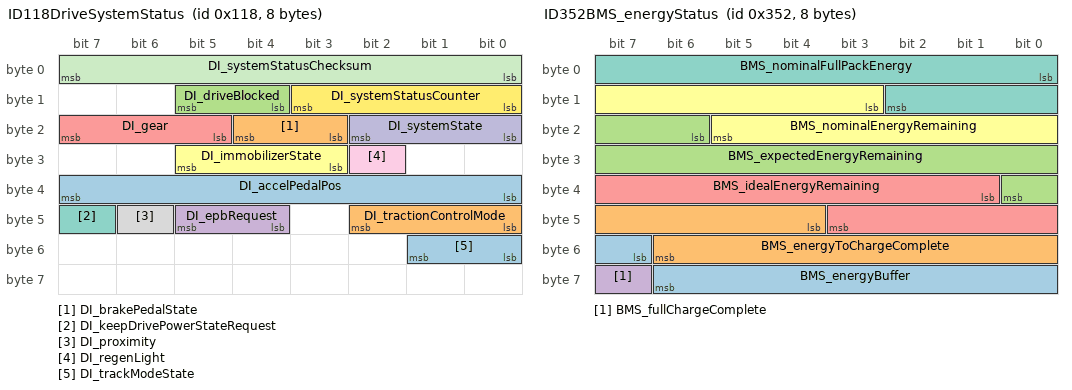
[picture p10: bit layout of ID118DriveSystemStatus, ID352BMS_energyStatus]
BO_ 280 ID118DriveSystemStatus: 8 VehicleBus
   SG_ DI_accelPedalPos : 32|8@1+ (0.4,0) [0|100] "%" Receiver
   SG_ DI_brakePedalState : 19|2@1+ (1,0) [0|2] "" Receiver
   SG_ DI_driveBlocked : 12|2@1+ (1,0) [0|2] "" Receiver
   SG_ DI_epbRequest : 44|2@1+ (1,0) [0|2] "" Receiver
   SG_ DI_gear : 21|3@1+ (1,0) [0|7] "" Receiver
   SG_ DI_immobilizerState : 27|3@1+ (1,0) [0|6] "" Receiver
   SG_ DI_keepDrivePowerStateRequest : 47|1@1+ (1,0) [0|1] "" Receiver
   SG_ DI_proximity : 46|1@1+ (1,0) [0|1] "" Receiver
   SG_ DI_regenLight : 26|1@1+ (1,0) [0|1] "" Receiver
   SG_ DI_systemState : 16|3@1+ (1,0) [0|5] "" Receiver
   SG_ DI_systemStatusChecksum : 0|8@1+ (1,0) [0|255] "" Receiver
   SG_ DI_systemStatusCounter : 8|4@1+ (1,0) [0|15] "" Receiver
   SG_ DI_trackModeState : 48|2@1+ (1,0) [0|2] "" Receiver
   SG_ DI_tractionControlMode : 40|3@1+ (1,0) [0|6] "" Receiver

BO_ 850 ID352BMS_energyStatus: 8 VehicleBus
   SG_ BMS_energyBuffer : 55|8@1+ (0.1,0) [0|25.4] "KWh" Receiver
   SG_ BMS_energyToChargeComplete : 44|11@1+ (0.1,0) [0|204.6] "KWh" Receiver
   SG_ BMS_expectedEnergyRemaining : 22|11@1+ (0.1,0) [0|204.6] "KWh" Receiver
   SG_ BMS_fullChargeComplete : 63|1@1+ (1,0) [0|1] "" Receiver
   SG_ BMS_idealEnergyRemaining : 33|11@1+ (0.1,0) [0|204.6] "KWh" Receiver
   SG_ BMS_nominalEnergyRemaining : 11|11@1+ (0.1,0) [0|204.6] "KWh" Receiver
   SG_ BMS_nominalFullPackEnergy : 0|11@1+ (0.1,0) [0|204.6] "KWh" Receiver

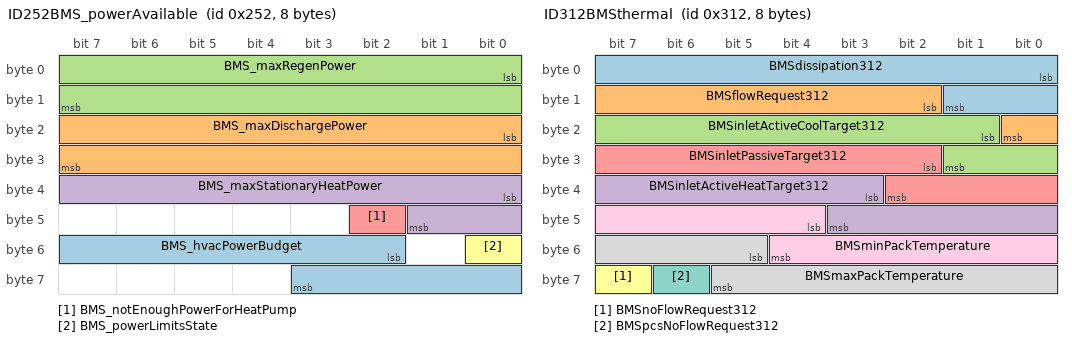
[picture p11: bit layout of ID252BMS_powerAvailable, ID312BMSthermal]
BO_ 594 ID252BMS_powerAvailable: 8 VehicleBus
   SG_ BMS_hvacPowerBudget : 50|10@1+ (0.02,0) [0|20.46] "kW" Receiver
   SG_ BMS_maxDischargePower : 16|16@1+ (0.01,0) [0|655.35] "kW" Receiver
   SG_ BMS_maxRegenPower : 0|16@1+ (0.01,0) [0|655.35] "kW" Receiver
   SG_ BMS_maxStationaryHeatPower : 32|10@1+ (0.01,0) [0|10.23] "kW" Receiver
   SG_ BMS_notEnoughPowerForHeatPump : 42|1@1+ (1,0) [0|1] "" Receiver
   SG_ BMS_powerLimitsState : 48|1@1+ (1,0) [0|1] "" Receiver

BO_ 786 ID312BMSthermal: 8 VehicleBus
   SG_ BMSdissipation312 : 0|10@1+ (0.02,0) [0|20] "kW" Receiver
   SG_ BMSflowRequest312 : 10|7@1+ (0.3,0) [0|30] "LPM" Receiver
   SG_ BMSinletActiveCoolTarget312 : 17|9@1+ (0.25,-25) [-25|100] "C" Receiver
   SG_ BMSinletActiveHeatTarget312 : 35|9@1+ (0.25,-25) [-25|100] "C" Receiver
   SG_ BMSinletPassiveTarget312 : 26|9@1+ (0.25,-25) [-25|100] "C" Receiver
   SG_ BMSnoFlowRequest312 : 63|1@1+ (1,0) [0|1] "" Receiver
   SG_ BMSpcsNoFlowRequest312 : 62|1@1+ (1,0) [0|1] "" Receiver
   SG_ BMSmaxPackTemperature : 53|9@1+ (0.25,-25) [-25|100] "C" Receiver
   SG_ BMSminPackTemperature : 44|9@1+ (0.25,-25) [-25|100] "C" Receiver

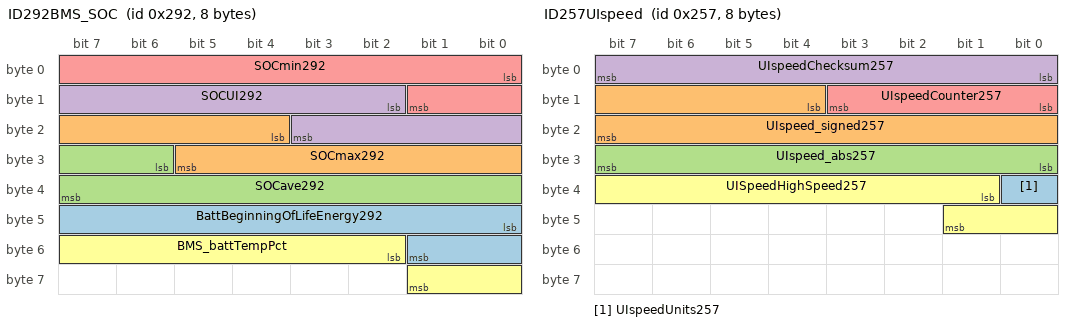
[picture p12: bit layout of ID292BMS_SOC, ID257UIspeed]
BO_ 658 ID292BMS_SOC: 8 VehicleBus
   SG_ BattBeginningOfLifeEnergy292 : 40|10@1+ (0.1,0) [0|102.3] "kWh" Receiver
   SG_ SOCmax292 : 20|10@1+ (0.1,0) [0|102.3] "%" Receiver
   SG_ SOCave292 : 30|10@1+ (0.1,0) [0|102.3] "%" Receiver
   SG_ SOCUI292 : 10|10@1+ (0.1,0) [0|102.3] "%" Receiver
   SG_ SOCmin292 : 0|10@1+ (0.1,0) [0|102.3] "%" Receiver
   SG_ BMS_battTempPct : 50|8@1+ (0.4,0) [0|100] "%" Receiver

BO_ 599 ID257UIspeed: 8 VehicleBus
   SG_ UIspeedUnits257 : 32|1@1+ (1,0) [0|0] "" Receiver
   SG_ UIspeed_signed257 : 12|12@1+ (0.08,-40) [-40|287.6] "KPH" Receiver
   SG_ UIspeed_abs257 : 24|8@1+ (1,0) [0|255] "MPHKPH" Receiver
   SG_ UIspeedChecksum257 : 0|8@1+ (1,0) [0|0] "" Receiver
   SG_ UIspeedCounter257 : 8|4@1+ (1,0) [0|0] "" Receiver
   SG_ UISpeedHighSpeed257 : 33|9@1+ (1,0) [0|510] "MPHKPH" Receiver

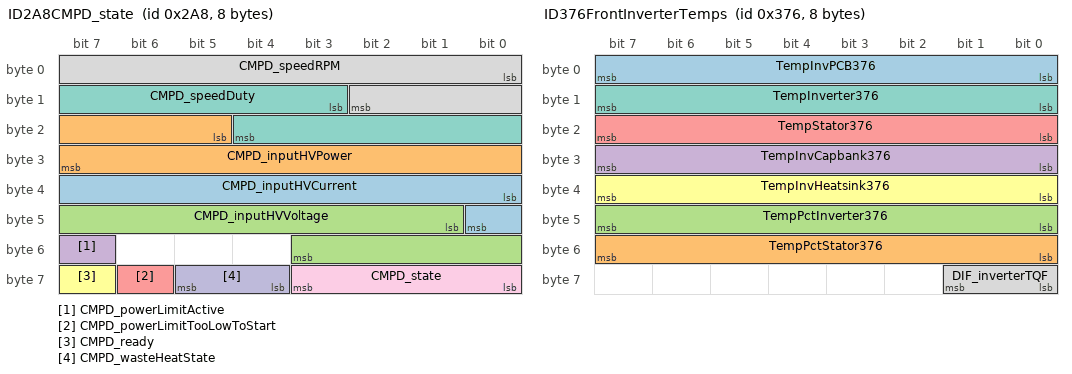
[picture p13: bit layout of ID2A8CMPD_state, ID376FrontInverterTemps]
BO_ 680 ID2A8CMPD_state: 8 VehicleBus
   SG_ CMPD_inputHVCurrent : 32|9@1+ (0.1,0) [0|50] "A" Receiver
   SG_ CMPD_inputHVPower : 21|11@1+ (10,0) [0|20000] "W" Receiver
   SG_ CMPD_inputHVVoltage : 41|11@1+ (0.5,0) [0|1000] "V" Receiver
   SG_ CMPD_powerLimitActive : 55|1@1+ (1,0) [0|1] "" Receiver
   SG_ CMPD_powerLimitTooLowToStart : 62|1@1+ (1,0) [0|1] "" Receiver
   SG_ CMPD_ready : 63|1@1+ (1,0) [0|1] "" Receiver
   SG_ CMPD_speedDuty : 11|10@1+ (0.1,0) [0|100] "%" Receiver
   SG_ CMPD_speedRPM : 0|11@1+ (10,0) [0|20000] "RPM" Receiver
   SG_ CMPD_state : 56|4@1+ (1,0) [0|15] "" Receiver
   SG_ CMPD_wasteHeatState : 60|2@1+ (1,0) [0|3] "" Receiver

BO_ 1029 ID405VIN: 8 VehicleBus
   SG_ VINB405 m17 : 8|56@1+ (1,0) [0|7.20576e+16] "" Receiver
   SG_ VINC405 m18 : 8|56@1+ (1,0) [0|7.20576e+16] "" Receiver
   SG_ VINA405 m16 : 8|56@1+ (1,0) [0|7.20576e+16] "" Receiver
   SG_ mux405 M : 0|8@1+ (1,0) [0|255] "" Receiver

BO_ 1310 ID51EFC_info: 8 VehicleBus
   SG_ FC_infoIndex M : 0|8@1+ (1,0) [0|255] "" Receiver
   SG_ FC_infoAppGitHashBytes m17 : 8|56@1+ (1,0) [0|7.20576e+16] "" Receiver
   SG_ FC_infoApplicationCRC m13 : 32|32@1+ (1,0) [0|4.29497e+09] "" Receiver
   SG_ FC_infoAssemblyID m11 : 24|8@1+ (1,0) [0|255] "" Receiver
   SG_ FC_infoBootCRC m15 : 32|32@1+ (1,0) [0|4.29497e+09] "" Receiver
   SG_ FC_infoBootGitHashBytes m18 : 8|56@1+ (1,0) [0|7.20576e+16] "" Receiver
   SG_ FC_infoBootSvnRev m14 : 8|24@1+ (1,0) [0|1.67772e+07] "" Receiver
   SG_ FC_infoBootUdsProtoVersion m20 : 8|8@1+ (1,0) [0|255] "" Receiver
   SG_ FC_infoBranchOrigin m19 : 24|8@1+ (1,0) [0|255] "" Receiver
   SG_ FC_infoBuildConfigID m10 : 16|8@1+ (1,0) [0|255] "" Receiver
   SG_ FC_infoBuildType m10 : 8|3@1+ (1,0) [0|4] "" Receiver
   SG_ FC_infoCPLDVersionMajor m16 : 16|8@1+ (1,0) [0|255] "" Receiver
   SG_ FC_infoCPLDVersionMinor m16 : 24|8@1+ (1,0) [0|255] "" Receiver
   SG_ FC_infoComponentID m10 : 48|16@1+ (1,0) [0|65535] "" Receiver
   SG_ FC_infoHardwareID m10 : 32|16@1+ (1,0) [0|65535] "" Receiver
   SG_ FC_infoHardwareRevision m19 : 40|8@1+ (1,0) [0|255] "" Receiver
   SG_ FC_infoMajorVersion m19 : 16|8@1+ (1,0) [0|255] "" Receiver
   SG_ FC_infoMaturity m19 : 32|8@1+ (1,0) [0|255] "" Receiver
   SG_ FC_infoPcbaID m11 : 16|8@1+ (1,0) [0|255] "" Receiver
   SG_ FC_infoPlatformType m19 : 8|8@1+ (1,0) [0|255] "" Receiver
   SG_ FC_infoSubUsageID m11 : 48|16@1+ (1,0) [0|65535] "" Receiver
   SG_ FC_infoUsageID m11 : 32|16@1+ (1,0) [0|65535] "" Receiver
   SG_ FC_infoVariantCRC m22 : 32|32@1+ (1,0) [0|4.29497e+09] "" Receiver
   SG_ FC_partNumChar01 m25 : 8|8@1+ (1,0) [0|1] "" Receiver
   SG_ FC_partNumChar02 m25 : 16|8@1+ (1,0) [0|1] "" Receiver
   SG_ FC_partNumChar03 m25 : 24|8@1+ (1,0) [0|1] "" Receiver
   SG_ FC_partNumChar04 m25 : 32|8@1+ (1,0) [0|1] "" Receiver
   SG_ FC_partNumChar05 m25 : 40|8@1+ (1,0) [0|1] "" Receiver
   SG_ FC_partNumChar06 m25 : 48|8@1+ (1,0) [0|1] "" Receiver
   SG_ FC_partNumChar07 m25 : 56|8@1+ (1,0) [0|1] "" Receiver
   SG_ FC_partNumChar08 m26 : 8|8@1+ (1,0) [0|1] "" Receiver
   SG_ FC_partNumChar09 m26 : 16|8@1+ (1,0) [0|1] "" Receiver
   SG_ FC_partNumChar10 m26 : 24|8@1+ (1,0) [0|1] "" Receiver
   SG_ FC_partNumChar11 m26 : 32|8@1+ (1,0) [0|1] "" Receiver
   SG_ FC_partNumChar12 m26 : 40|8@1+ (1,0) [0|1] "" Receiver
   SG_ FC_partNumChar13 m26 : 48|8@1+ (1,0) [0|1] "" Receiver
   SG_ FC_partNumChar14 m26 : 56|8@1+ (1,0) [0|1] "" Receiver
   SG_ FC_partNumChar15 m27 : 8|8@1+ (1,0) [0|1] "" Receiver
   SG_ FC_partNumChar16 m27 : 16|8@1+ (1,0) [0|1] "" Receiver
   SG_ FC_partNumChar17 m27 : 24|8@1+ (1,0) [0|1] "" Receiver
   SG_ FC_partNumChar18 m27 : 32|8@1+ (1,0) [0|1] "" Receiver
   SG_ FC_partNumChar19 m27 : 40|8@1+ (1,0) [0|1] "" Receiver
   SG_ FC_partNumChar20 m27 : 48|8@1+ (1,0) [0|1] "" Receiver

BO_ 886 ID376FrontInverterTemps: 8 VehicleBus
   SG_ TempInvPCB376 : 0|8@1+ (1,-40) [-40|215] "C" Receiver
   SG_ TempPctStator376 : 48|8@1+ (0.4,0) [0|102] "%" Receiver
   SG_ TempPctInverter376 : 40|8@1+ (0.4,0) [0|102] "%" Receiver
   SG_ TempInvCapbank376 : 24|8@1+ (1,-40) [-40|215] "C" Receiver
   SG_ TempStator376 : 16|8@1+ (1,-40) [-40|215] "C" Receiver
   SG_ TempInvHeatsink376 : 32|8@1+ (1,-40) [-40|215] "C" Receiver
   SG_ TempInverter376 : 8|8@1+ (1,-40) [-40|215] "C" Receiver
   SG_ DIF_inverterTQF : 56|2@1+ (1,0) [0|3] "" Receiver

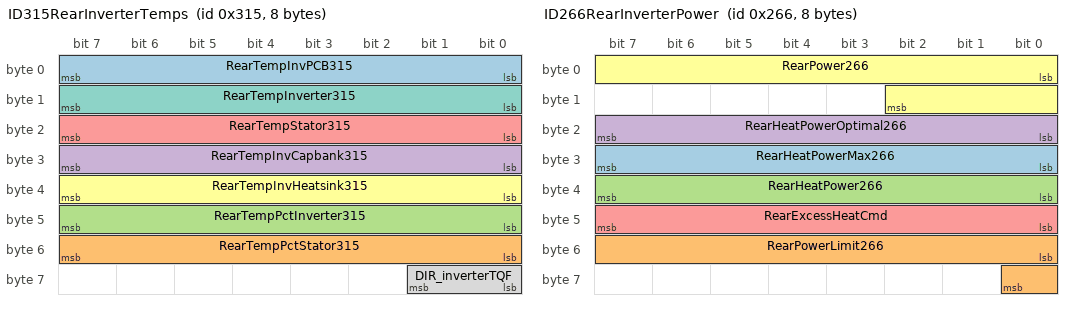
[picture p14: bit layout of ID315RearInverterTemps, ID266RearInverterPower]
BO_ 789 ID315RearInverterTemps: 8 VehicleBus
   SG_ RearTempInvPCB315 : 0|8@1+ (1,-40) [-40|215] "C" Receiver
   SG_ RearTempPctStator315 : 48|8@1+ (0.4,0) [0|102] "%" Receiver
   SG_ RearTempPctInverter315 : 40|8@1+ (0.4,0) [0|102] "%" Receiver
   SG_ RearTempInvCapbank315 : 24|8@1+ (1,-40) [-40|215] "C" Receiver
   SG_ RearTempStator315 : 16|8@1+ (1,-40) [-40|215] "C" Receiver
   SG_ RearTempInvHeatsink315 : 32|8@1+ (1,-40) [-40|215] "C" Receiver
   SG_ RearTempInverter315 : 8|8@1+ (1,-40) [-40|215] "C" Receiver
   SG_ DIR_inverterTQF : 56|2@1+ (1,0) [0|3] "" Receiver

BO_ 340 ID154RearTorqueOld: 8 VehicleBus
   SG_ RAWTorqueRear154 : 40|12@1- (0.25,0) [-512|511.75] "NM" Receiver

BO_ 950 ID3B6odometer: 4 VehicleBus
   SG_ Odometer3B6 : 0|32@1+ (0.001,0) [0|4.29497e+06] "KM" Receiver

BO_ 614 ID266RearInverterPower: 8 VehicleBus
   SG_ RearHeatPowerMax266 : 24|8@1+ (0.08,0) [0|20] "kW" Receiver
   SG_ RearPowerLimit266 : 48|9@1+ (1,0) [0|400] "kW" Receiver
   SG_ RearHeatPower266 : 32|8@1+ (0.08,0) [0|20] "kW" Receiver
   SG_ RearHeatPowerOptimal266 : 16|8@1+ (0.08,0) [0|20] "kW" Receiver
   SG_ RearExcessHeatCmd : 40|8@1+ (0.08,0) [0|20] "kW" Receiver
   SG_ RearPower266 : 0|11@1- (0.5,0) [-500|500] "kW" Receiver

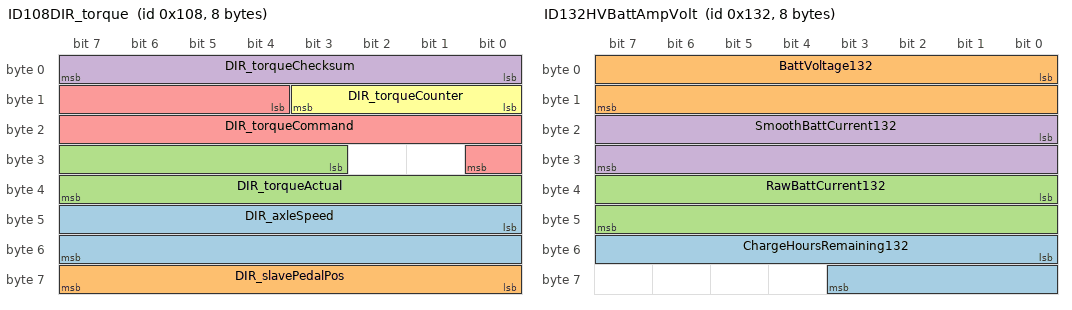
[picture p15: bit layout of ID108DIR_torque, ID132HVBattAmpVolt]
BO_ 264 ID108DIR_torque: 8 VehicleBus
   SG_ DIR_axleSpeed : 40|16@1- (0.1,0) [-2750|2750] "RPM" Receiver
   SG_ DIR_slavePedalPos : 56|8@1+ (0.4,0) [0|100] "%" Receiver
   SG_ DIR_torqueActual : 27|13@1- (2,0) [-7500|7500] "Nm" Receiver
   SG_ DIR_torqueChecksum : 0|8@1+ (1,0) [0|255] "" Receiver
   SG_ DIR_torqueCommand : 12|13@1- (2,0) [-7500|7500] "Nm" Receiver
   SG_ DIR_torqueCounter : 8|4@1+ (1,0) [0|15] "" Receiver

BO_ 306 ID132HVBattAmpVolt: 8 VehicleBus
   SG_ ChargeHoursRemaining132 : 48|12@1+ (1,0) [0|4095] "Min" Receiver
   SG_ BattVoltage132 : 0|16@1+ (0.01,0) [0|655.35] "V" Receiver
   SG_ RawBattCurrent132 : 32|16@1- (-0.05,500) [-1138.35|2138.4] "A" Receiver
   SG_ SmoothBattCurrent132 : 16|16@1- (-0.1,0) [-3276.7|3276.7] "A" Receiver

BO_ 294 ID126RearHVStatus: 3 VehicleBus
   SG_ RearHighVoltage126 : 0|10@1+ (0.5,0) [0|500] "V" Receiver
   SG_ RearMotorCurrent126 : 10|11@1+ (1,0) [0|2047] "A" Receiver

BO_ 421 ID1A5FrontHVStatus: 3 VehicleBus
   SG_ FrontHighVoltage1A5 : 0|10@1+ (0.5,0) [0|500] "V" Receiver
   SG_ FrontMotorCurrent1A5 : 10|11@1+ (1,0) [0|2047] "A" Receiver

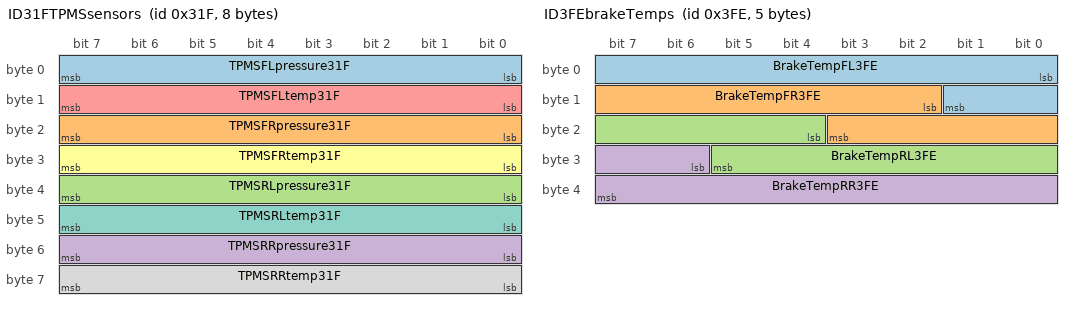
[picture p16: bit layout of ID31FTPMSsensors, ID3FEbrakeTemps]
BO_ 799 ID31FTPMSsensors: 8 ChassisBus
   SG_ TPMSFLpressure31F : 0|8@1+ (0.025,0) [0|6.375] "bar" Receiver
   SG_ TPMSFRpressure31F : 16|8@1+ (0.025,0) [0|6.375] "bar" Receiver
   SG_ TPMSRLpressure31F : 32|8@1+ (0.025,0) [0|6.375] "bar" Receiver
   SG_ TPMSRRpressure31F : 48|8@1+ (0.025,0) [0|6.375] "bar" Receiver
   SG_ TPMSFLtemp31F : 8|8@1+ (1,-40) [-40|215] "C" Receiver
   SG_ TPMSFRtemp31F : 24|8@1+ (1,-40) [-40|215] "C" Receiver
   SG_ TPMSRLtemp31F : 40|8@1+ (1,-40) [-40|215] "C" Receiver
   SG_ TPMSRRtemp31F : 56|8@1+ (1,-40) [-40|215] "C" Receiver

BO_ 1022 ID3FEbrakeTemps: 5 VehicleBus
   SG_ BrakeTempFL3FE : 0|10@1+ (1,-40) [0|0] "C" Receiver
   SG_ BrakeTempFR3FE : 10|10@1+ (1,-40) [0|0] "C" Receiver
   SG_ BrakeTempRL3FE : 20|10@1+ (1,-40) [0|0] "C" Receiver
   SG_ BrakeTempRR3FE : 30|10@1+ (1,-40) [0|0] "C" Receiver

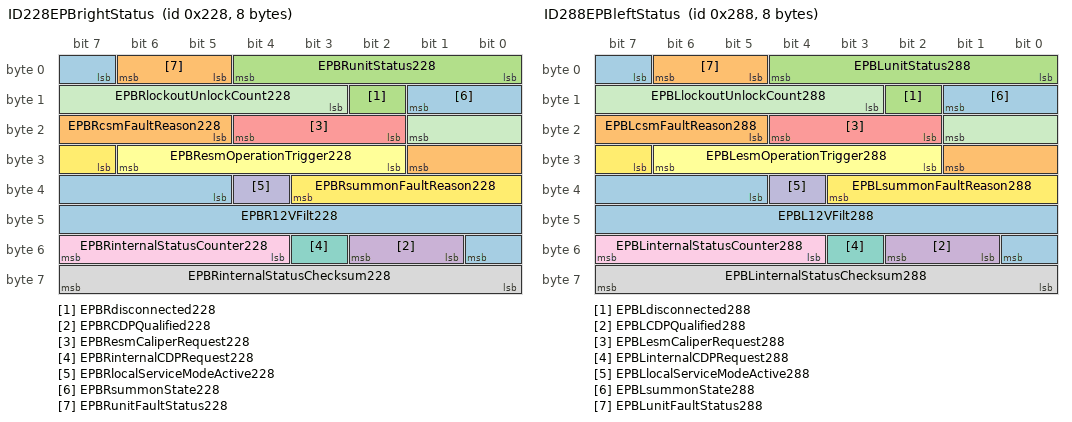
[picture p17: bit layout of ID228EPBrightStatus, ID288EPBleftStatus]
BO_ 552 ID228EPBrightStatus: 8 VehicleBus
   SG_ EPBR12VFilt228 : 37|12@1+ (0.00544368,0) [0|0] "V" Receiver
   SG_ EPBRcsmFaultReason228 : 21|5@1+ (1,0) [0|0] "" Receiver
   SG_ EPBRdisconnected228 : 10|1@1+ (1,0) [0|0] "" Receiver
   SG_ EPBRCDPQualified228 : 49|2@1+ (1,0) [0|0] "" Receiver
   SG_ EPBResmCaliperRequest228 : 18|3@1+ (1,0) [0|0] "" Receiver
   SG_ EPBResmOperationTrigger228 : 26|5@1+ (1,0) [0|0] "" Receiver
   SG_ EPBRinternalCDPRequest228 : 51|1@1+ (1,0) [0|0] "" Receiver
   SG_ EPBRinternalStatusChecksum228 : 56|8@1+ (1,0) [0|0] "" Receiver
   SG_ EPBRinternalStatusCounter228 : 52|4@1+ (1,0) [0|0] "" Receiver
   SG_ EPBRlocalServiceModeActive228 : 36|1@1+ (1,0) [0|0] "" Receiver
   SG_ EPBRlockoutUnlockCount228 : 11|7@1+ (1,0) [0|0] "" Receiver
   SG_ EPBRsummonFaultReason228 : 31|5@1+ (1,0) [0|0] "" Receiver
   SG_ EPBRsummonState228 : 7|3@1+ (1,0) [0|0] "" Receiver
   SG_ EPBRunitFaultStatus228 : 5|2@1+ (1,0) [0|0] "" Receiver
   SG_ EPBRunitStatus228 : 0|5@1+ (1,0) [0|0] "" Receiver

BO_ 648 ID288EPBleftStatus: 8 VehicleBus
   SG_ EPBL12VFilt288 : 37|12@1+ (0.00544368,0) [0|0] "V" Receiver
   SG_ EPBLcsmFaultReason288 : 21|5@1+ (1,0) [0|0] "" Receiver
   SG_ EPBLdisconnected288 : 10|1@1+ (1,0) [0|0] "" Receiver
   SG_ EPBLCDPQualified288 : 49|2@1+ (1,0) [0|0] "" Receiver
   SG_ EPBLesmCaliperRequest288 : 18|3@1+ (1,0) [0|0] "" Receiver
   SG_ EPBLesmOperationTrigger288 : 26|5@1+ (1,0) [0|0] "" Receiver
   SG_ EPBLinternalCDPRequest288 : 51|1@1+ (1,0) [0|0] "" Receiver
   SG_ EPBLinternalStatusChecksum288 : 56|8@1+ (1,0) [0|0] "" Receiver
   SG_ EPBLinternalStatusCounter288 : 52|4@1+ (1,0) [0|0] "" Receiver
   SG_ EPBLlocalServiceModeActive288 : 36|1@1+ (1,0) [0|0] "" Receiver
   SG_ EPBLlockoutUnlockCount288 : 11|7@1+ (1,0) [0|0] "" Receiver
   SG_ EPBLsummonFaultReason288 : 31|5@1+ (1,0) [0|0] "" Receiver
   SG_ EPBLsummonState288 : 7|3@1+ (1,0) [0|0] "" Receiver
   SG_ EPBLunitFaultStatus288 : 5|2@1+ (1,0) [0|0] "" Receiver
   SG_ EPBLunitStatus288 : 0|5@1+ (1,0) [0|0] "" Receiver

BO_ 2047 ID7FFcarConfig: 8 VehicleBus
   SG_ GTW_carConfigMultiplexer M : 0|8@1+ (1,0) [0|255] "" Receiver
   SG_ GTW_CabinBlowerCtrlType m2 : 30|1@1+ (1,0) [0|1] "" Receiver
   SG_ GTW_activeHighBeam m2 : 34|1@1+ (1,0) [0|1] "" Receiver
   SG_ GTW_airSuspension m3 : 22|2@1+ (1,0) [0|2] "" Receiver
   SG_ GTW_airbagCutoffSwitch m2 : 35|1@1+ (1,0) [0|1] "" Receiver
   SG_ GTW_audioType m3 : 30|2@1+ (1,0) [0|2] "" Receiver
   SG_ GTW_autopilot m2 : 42|3@1+ (1,0) [0|4] "" Receiver
   SG_ GTW_autopilotCameraType m3 : 26|1@1+ (1,0) [0|0] "" Receiver
   SG_ GTW_auxParkLamps m2 : 26|2@1+ (1,0) [0|3] "" Receiver
   SG_ GTW_bPillarNFCParam m2 : 56|1@1+ (1,0) [0|1] "" Receiver
   SG_ GTW_birthday m4 : 8|32@1+ (1,0) [0|4.29497e+09] "" Receiver
   SG_ GTW_brakeHWType m2 : 59|2@1+ (1,0) [0|3] "" Receiver
   SG_ GTW_brakeLineSwitchType m3 : 39|1@1+ (1,0) [0|1] "" Receiver
   SG_ GTW_cabinPTCHeaterType m2 : 31|1@1+ (1,0) [0|1] "" Receiver
   SG_ GTW_chassisType m3 : 18|3@1+ (1,0) [0|4] "" Receiver
   SG_ GTW_compressorType m2 : 47|1@1+ (1,0) [0|1] "" Receiver
   SG_ GTW_connectivityPackage m3 : 27|1@1+ (1,0) [0|1] "" Receiver
   SG_ GTW_coolantPumpType m3 : 17|1@1+ (1,0) [0|1] "" Receiver
   SG_ GTW_country m1 : 16|16@1+ (1,0) [0|65535] "" Receiver
   SG_ GTW_dasHw m1 : 40|3@1+ (1,0) [3|4] "" Receiver
   SG_ GTW_deliveryStatus m1 : 8|1@1+ (1,0) [0|1] "" Receiver
   SG_ GTW_drivetrainType m1 : 10|1@1+ (1,0) [0|1] "" odin
   SG_ GTW_eBuckConfig m2 : 32|1@1+ (1,0) [0|1] "" Receiver
   SG_ GTW_eCallEnabled m4 : 40|2@1+ (1,0) [0|2] "" Receiver
   SG_ GTW_efficiencyPackage m3 : 58|2@1+ (1,0) [0|3] "" Receiver
   SG_ GTW_epasType m1 : 9|1@1+ (1,0) [0|1] "" Receiver
   SG_ GTW_espValveType m3 : 40|2@1+ (1,0) [0|2] "" Receiver
   SG_ GTW_exteriorColor m2 : 48|3@1+ (1,0) [0|6] "" Receiver
   SG_ GTW_frontFogLamps m2 : 20|1@1+ (1,0) [0|1] "" Receiver
   SG_ GTW_frontSeatHeaters m2 : 9|1@1+ (1,0) [0|1] "" Receiver
   SG_ GTW_frontSeatReclinerHardware m3 : 37|2@1+ (1,0) [0|3] "" Receiver
   SG_ GTW_frontSeatType m3 : 60|3@1+ (1,0) [0|4] "" Receiver
   SG_ GTW_headlamps m1 : 14|2@1+ (1,0) [0|2] "" Receiver
   SG_ GTW_headlightLevelerType m3 : 47|1@1+ (1,0) [0|1] "" Receiver
   SG_ GTW_heatedWipers m2 : 8|1@1+ (1,0) [0|1] "" Receiver
   SG_ GTW_homelinkType m2 : 13|1@1+ (1,0) [0|1] "" Receiver
   SG_ GTW_hvacPanelVaneType m2 : 29|1@1+ (1,0) [0|1] "" Receiver
   SG_ GTW_hvacQuietSnorkelType m2 : 28|1@1+ (1,0) [0|1] "" Receiver
   SG_ GTW_ibstWakeType m2 : 24|1@1+ (1,0) [0|1] "" Receiver
   SG_ GTW_immersiveAudio m3 : 56|2@1+ (1,0) [0|2] "" Receiver
   SG_ GTW_interiorLighting m2 : 57|2@1+ (1,0) [0|2] "" Receiver
   SG_ GTW_intrusionSensorType m2 : 36|1@1+ (1,0) [0|1] "" Receiver
   SG_ GTW_loggingVersion m2 : 22|1@1+ (1,0) [0|1] "" Receiver
   SG_ GTW_lumbarECUType m2 : 23|1@1+ (1,0) [0|1] "" Receiver
   SG_ GTW_m3FrontOverheadConsoleType m2 : 25|1@1+ (1,0) [0|1] "" Receiver
   SG_ GTW_mapRegion m3 : 8|4@1+ (1,0) [0|10] "" Receiver
   SG_ GTW_memoryMirrors m2 : 17|1@1+ (1,0) [0|1] "" Receiver
   SG_ GTW_numberHVILNodes m2 : 51|3@1+ (1,0) [0|5] "" Receiver
   SG_ GTW_packEnergy m3 : 32|5@1+ (1,0) [0|4] "" Receiver
   SG_ GTW_packMassDeviation m4 : 42|1@1+ (1,0) [0|1] "" Receiver
   SG_ GTW_passengerAirbagType m4 : 43|2@1+ (1,0) [0|2] "" Receiver
   SG_ GTW_passengerOccupancySensorType m3 : 24|1@1+ (1,0) [0|1] "" Receiver
   SG_ GTW_pedestrianWarningSound m2 : 54|1@1+ (1,0) [0|1] "" Receiver
   SG_ GTW_performancePackage m3 : 12|3@1+ (1,0) [0|3] "" Receiver
   SG_ GTW_plcSupportType m3 : 28|2@1+ (1,0) [0|2] "" Receiver
   SG_ GTW_powerSteeringColumn m2 : 18|1@1+ (1,0) [0|1] "" Receiver
   SG_ GTW_radarHeaterType m3 : 55|1@1+ (1,0) [0|1] "" Receiver
   SG_ GTW_rearDriveUnitType m3 : 21|1@1+ (1,0) [0|1] "" Receiver
   SG_ GTW_rearFogLamps m2 : 39|1@1+ (1,0) [0|1] "" Receiver
   SG_ GTW_rearGlassType m2 : 38|1@1+ (1,0) [0|1] "" Receiver
   SG_ GTW_rearLightType m1 : 12|2@1+ (1,0) [0|2] "" Receiver
   SG_ GTW_rearSeatHeaters m2 : 10|1@1+ (1,0) [0|1] "" Receiver
   SG_ GTW_refrigerantType m3 : 45|2@1+ (1,0) [0|2] "" Receiver
   SG_ GTW_restraintsHardwareType m1 : 48|8@1+ (1,0) [21|163] "" Receiver
   SG_ GTW_rightHandDrive m1 : 11|1@1+ (1,0) [0|1] "" Receiver
   SG_ GTW_roofGlassType m2 : 61|1@1+ (1,0) [0|1] "" Receiver
   SG_ GTW_roofType m2 : 40|2@1+ (1,0) [0|2] "" Receiver
   SG_ GTW_softRange m3 : 42|3@1+ (1,0) [0|2] "" Receiver
   SG_ GTW_spoilerType m2 : 37|1@1+ (1,0) [0|1] "" Receiver
   SG_ GTW_steeringColumnUJointType m2 : 55|1@1+ (1,0) [0|1] "" Receiver
   SG_ GTW_superchargingAccess m2 : 45|2@1+ (1,0) [0|2] "" Receiver
   SG_ GTW_tireType m1 : 32|5@1+ (1,0) [0|21] "" Receiver
   SG_ GTW_towPackage m3 : 15|1@1+ (1,0) [0|1] "" Receiver
   SG_ GTW_tpmsType m2 : 11|1@1+ (1,0) [0|1] "" Receiver
   SG_ GTW_trackModePackage m2 : 62|1@1+ (1,0) [0|1] "" Receiver
   SG_ GTW_twelveVBatteryType m3 : 63|1@1+ (1,0) [0|1] "" Receiver
   SG_ GTW_vdcType m2 : 14|1@1+ (1,0) [0|1] "" Receiver
   SG_ GTW_wheelType m3 : 48|7@1+ (1,0) [0|20] "" Receiver
   SG_ GTW_windshieldType m2 : 33|1@1+ (1,0) [0|1] "" Receiver
   SG_ GTW_xcpESP m2 : 16|1@1+ (1,0) [0|1] "" Receiver
   SG_ GTW_xcpIbst m2 : 15|1@1+ (1,0) [0|1] "" Receiver

BO_ 818 ID332BattCellMinMax: 6 VehicleBus
   SG_ BattCellMultiplexer332 M : 0|2@1+ (1,0) [0|0] "" Receiver
   SG_ BattCellTempMaxNum332 m0 : 2|4@1+ (1,0) [0|0] "" Receiver
   SG_ BattCellTempMinNum332 m0 : 8|4@1+ (1,0) [0|0] "" Receiver
   SG_ BattCellTempMax332 m0 : 16|8@1+ (0.5,-40) [0|0] "C" Receiver
   SG_ BattCellTempMin332 m0 : 24|8@1+ (0.5,-40) [0|0] "C" Receiver
   SG_ BattCellModelTMax332 m0 : 32|8@1+ (0.5,-40) [0|0] "C" Receiver
   SG_ BattCellModelTMin332 m0 : 40|8@1+ (0.5,-40) [0|0] "C" Receiver
   SG_ BattCellBrickVoltageMax332 m1 : 2|12@1+ (0.002,0) [0|0] "V" Receiver
   SG_ BattCellBrickVoltageMin332 m1 : 16|12@1+ (0.002,0) [0|0] "V" Receiver
   SG_ BattCellBrickVoltageMaxNum332 m1 : 32|7@1+ (1,1) [0|0] "" Receiver
   SG_ BattCellBrickVoltageMinNum332 m1 : 40|7@1+ (1,1) [0|0] "" Receiver

BO_ 1025 ID401CellVoltages: 8 VehicleBus
   SG_ MultiplexSelector M : 0|8@1+ (1,0) [0|0] "" Receiver
   SG_ StatusFlags : 8|8@1+ (1,0) [0|0] "" Receiver
   SG_ Cell0 m0 : 16|16@1+ (0.0001,0) [0|0] "V" Receiver
   SG_ Cell1 m0 : 32|16@1+ (0.0001,0) [0|0] "V" Receiver
   SG_ Cell2 m0 : 48|16@1+ (0.0001,0) [0|0] "V" Receiver
   SG_ Cell3 m1 : 16|16@1+ (0.0001,0) [0|0] "V" Receiver
   SG_ Cell4 m1 : 32|16@1+ (0.0001,0) [0|0] "V" Receiver
   SG_ Cell5 m1 : 48|16@1+ (0.0001,0) [0|0] "V" Receiver
   SG_ Cell6 m2 : 16|16@1+ (0.0001,0) [0|0] "V" Receiver
   SG_ Cell7 m2 : 32|16@1+ (0.0001,0) [0|0] "V" Receiver
   SG_ Cell8 m2 : 48|16@1+ (0.0001,0) [0|0] "V" Receiver
   SG_ Cell9 m3 : 16|16@1+ (0.0001,0) [0|0] "V" Receiver
   SG_ Cell10 m3 : 32|16@1+ (0.0001,0) [0|0] "V" Receiver
   SG_ Cell11 m3 : 48|16@1+ (0.0001,0) [0|0] "V" Receiver
   SG_ Cell12 m4 : 16|16@1+ (0.0001,0) [0|0] "V" Receiver
   SG_ Cell13 m4 : 32|16@1+ (0.0001,0) [0|0] "V" Receiver
   SG_ Cell14 m4 : 48|16@1+ (0.0001,0) [0|0] "V" Receiver
   SG_ Cell15 m5 : 16|16@1+ (0.0001,0) [0|0] "V" Receiver
   SG_ Cell16 m5 : 32|16@1+ (0.0001,0) [0|0] "V" Receiver
   SG_ Cell17 m5 : 48|16@1+ (0.0001,0) [0|0] "V" Receiver
   SG_ Cell18 m6 : 16|16@1+ (0.0001,0) [0|0] "V" Receiver
   SG_ Cell19 m6 : 32|16@1+ (0.0001,0) [0|0] "V" Receiver
   SG_ Cell20 m6 : 48|16@1+ (0.0001,0) [0|0] "V" Receiver
   SG_ Cell21 m7 : 16|16@1+ (0.0001,0) [0|0] "V" Receiver
   SG_ Cell22 m7 : 32|16@1+ (0.0001,0) [0|0] "V" Receiver
   SG_ Cell23 m7 : 48|16@1+ (0.0001,0) [0|0] "V" Receiver
   SG_ Cell24 m8 : 16|16@1+ (0.0001,0) [0|0] "V" Receiver
   SG_ Cell25 m8 : 32|16@1+ (0.0001,0) [0|0] "V" Receiver
   SG_ Cell26 m8 : 48|16@1+ (0.0001,0) [0|0] "V" Receiver
   SG_ Cell27 m9 : 16|16@1+ (0.0001,0) [0|0] "V" Receiver
   SG_ Cell28 m9 : 32|16@1+ (0.0001,0) [0|0] "V" Receiver
   SG_ Cell29 m9 : 48|16@1+ (0.0001,0) [0|0] "V" Receiver
   SG_ Cell30 m10 : 16|16@1+ (0.0001,0) [0|0] "V" Receiver
   SG_ Cell31 m10 : 32|16@1+ (0.0001,0) [0|0] "V" Receiver
   SG_ Cell32 m10 : 48|16@1+ (0.0001,0) [0|0] "V" Receiver
   SG_ Cell34 m11 : 16|16@1+ (0.0001,0) [0|0] "V" Receiver
   SG_ Cell33 m11 : 32|16@1+ (0.0001,0) [0|0] "V" Receiver
   SG_ Cell35 m11 : 48|16@1+ (0.0001,0) [0|0] "V" Receiver
   SG_ Cell36 m12 : 16|16@1+ (0.0001,0) [0|0] "V" Receiver
   SG_ Cell37 m12 : 32|16@1+ (0.0001,0) [0|0] "V" Receiver
   SG_ Cell38 m12 : 48|16@1+ (0.0001,0) [0|0] "V" Receiver
   SG_ Cell39 m13 : 16|16@1+ (0.0001,0) [0|0] "V" Receiver
   SG_ Cell40 m13 : 32|16@1+ (0.0001,0) [0|0] "V" Receiver
   SG_ Cell41 m13 : 48|16@1+ (0.0001,0) [0|0] "V" Receiver
   SG_ Cell42 m14 : 16|16@1+ (0.0001,0) [0|0] "V" Receiver
   SG_ Cell43 m14 : 32|16@1+ (0.0001,0) [0|0] "V" Receiver
   SG_ Cell44 m14 : 48|16@1+ (0.0001,0) [0|0] "V" Receiver
   SG_ Cell45 m15 : 16|16@1+ (0.0001,0) [0|0] "V" Receiver
   SG_ Cell46 m15 : 32|16@1+ (0.0001,0) [0|0] "V" Receiver
   SG_ Cell47 m15 : 48|16@1+ (0.0001,0) [0|0] "V" Receiver
   SG_ Cell48 m16 : 16|16@1+ (0.0001,0) [0|0] "V" Receiver
   SG_ Cell49 m16 : 32|16@1+ (0.0001,0) [0|0] "V" Receiver
   SG_ Cell50 m16 : 48|16@1+ (0.0001,0) [0|0] "V" Receiver
   SG_ Cell51 m17 : 16|16@1+ (0.0001,0) [0|0] "V" Receiver
   SG_ Cell52 m17 : 32|16@1+ (0.0001,0) [0|0] "V" Receiver
   SG_ Cell53 m17 : 48|16@1+ (0.0001,0) [0|0] "V" Receiver
   SG_ Cell54 m18 : 16|16@1+ (0.0001,0) [0|0] "V" Receiver
   SG_ Cell55 m18 : 32|16@1+ (0.0001,0) [0|0] "V" Receiver
   SG_ Cell56 m18 : 48|16@1+ (0.0001,0) [0|0] "V" Receiver
   SG_ Cell57 m19 : 16|16@1+ (0.0001,0) [0|0] "V" Receiver
   SG_ Cell58 m19 : 32|16@1+ (0.0001,0) [0|0] "V" Receiver
   SG_ Cell59 m19 : 48|16@1+ (0.0001,0) [0|0] "V" Receiver
   SG_ Cell60 m20 : 16|16@1+ (0.0001,0) [0|0] "V" Receiver
   SG_ Cell61 m20 : 32|16@1+ (0.0001,0) [0|0] "V" Receiver
   SG_ Cell62 m20 : 48|16@1+ (0.0001,0) [0|0] "V" Receiver
   SG_ Cell63 m21 : 16|16@1+ (0.0001,0) [0|0] "V" Receiver
   SG_ Cell64 m21 : 32|16@1+ (0.0001,0) [0|0] "V" Receiver
   SG_ Cell65 m21 : 48|16@1+ (0.0001,0) [0|0] "V" Receiver
   SG_ Cell66 m22 : 16|16@1+ (0.0001,0) [0|0] "V" Receiver
   SG_ Cell67 m22 : 32|16@1+ (0.0001,0) [0|0] "V" Receiver
   SG_ Cell68 m22 : 48|16@1+ (0.0001,0) [0|0] "V" Receiver
   SG_ Cell69 m23 : 16|16@1+ (0.0001,0) [0|0] "V" Receiver
   SG_ Cell70 m23 : 32|16@1+ (0.0001,0) [0|0] "V" Receiver
   SG_ Cell71 m23 : 48|16@1+ (0.0001,0) [0|0] "V" Receiver
   SG_ Cell72 m24 : 16|16@1+ (0.0001,0) [0|0] "V" Receiver
   SG_ Cell73 m24 : 32|16@1+ (0.0001,0) [0|0] "V" Receiver
   SG_ Cell74 m24 : 48|16@1+ (0.0001,0) [0|0] "V" Receiver
   SG_ Cell75 m25 : 16|16@1+ (0.0001,0) [0|0] "V" Receiver
   SG_ Cell76 m25 : 32|16@1+ (0.0001,0) [0|0] "V" Receiver
   SG_ Cell77 m25 : 48|16@1+ (0.0001,0) [0|0] "V" Receiver
   SG_ Cell78 m26 : 16|16@1+ (0.0001,0) [0|0] "V" Receiver
   SG_ Cell79 m26 : 32|16@1+ (0.0001,0) [0|0] "V" Receiver
   SG_ Cell80 m26 : 48|16@1+ (0.0001,0) [0|0] "V" Receiver
   SG_ Cell81 m27 : 16|16@1+ (0.0001,0) [0|0] "V" Receiver
   SG_ Cell82 m27 : 32|16@1+ (0.0001,0) [0|0] "V" Receiver
   SG_ Cell83 m27 : 48|16@1+ (0.0001,0) [0|0] "V" Receiver
   SG_ Cell84 m28 : 16|16@1+ (0.0001,0) [0|0] "V" Receiver
   SG_ Cell85 m28 : 32|16@1+ (0.0001,0) [0|0] "V" Receiver
   SG_ Cell86 m28 : 48|16@1+ (0.0001,0) [0|0] "V" Receiver
   SG_ Cell87 m29 : 16|16@1+ (0.0001,0) [0|0] "V" Receiver
   SG_ Cell88 m29 : 32|16@1+ (0.0001,0) [0|0] "V" Receiver
   SG_ Cell89 m29 : 48|16@1+ (0.0001,0) [0|0] "V" Receiver
   SG_ Cell90 m30 : 16|16@1+ (0.0001,0) [0|0] "V" Receiver
   SG_ Cell91 m30 : 32|16@1+ (0.0001,0) [0|0] "V" Receiver
   SG_ Cell92 m30 : 48|16@1+ (0.0001,0) [0|0] "V" Receiver
   SG_ Cell93 m31 : 16|16@1+ (0.0001,0) [0|0] "V" Receiver
   SG_ Cell94 m31 : 32|16@1+ (0.0001,0) [0|0] "V" Receiver
   SG_ Cell95 m31 : 48|16@1+ (0.0001,0) [0|0] "V" Receiver
   SG_ Cell96 m32 : 16|16@1+ (0.0001,0) [0|0] "V" Receiver
   SG_ Cell97 m32 : 32|16@1+ (0.0001,0) [0|0] "V" Receiver
   SG_ Cell98 m32 : 48|16@1+ (0.0001,0) [0|0] "V" Receiver
   SG_ Cell99 m33 : 16|16@1+ (0.0001,0) [0|0] "V" Receiver
   SG_ Cell100 m33 : 32|16@1+ (0.0001,0) [0|0] "V" Receiver
   SG_ Cell101 m33 : 48|16@1+ (0.0001,0) [0|0] "V" Receiver
   SG_ Cell102 m34 : 16|16@1+ (0.0001,0) [0|0] "V" Receiver
   SG_ Cell103 m34 : 32|16@1+ (0.0001,0) [0|0] "V" Receiver
   SG_ Cell104 m34 : 48|16@1+ (0.0001,0) [0|0] "V" Receiver
   SG_ Cell105 m35 : 16|16@1+ (0.0001,0) [0|0] "V" Receiver
   SG_ Cell106 m35 : 32|16@1+ (0.0001,0) [0|0] "V" Receiver
   SG_ Cell107 m35 : 48|16@1+ (0.0001,0) [0|0] "V" Receiver

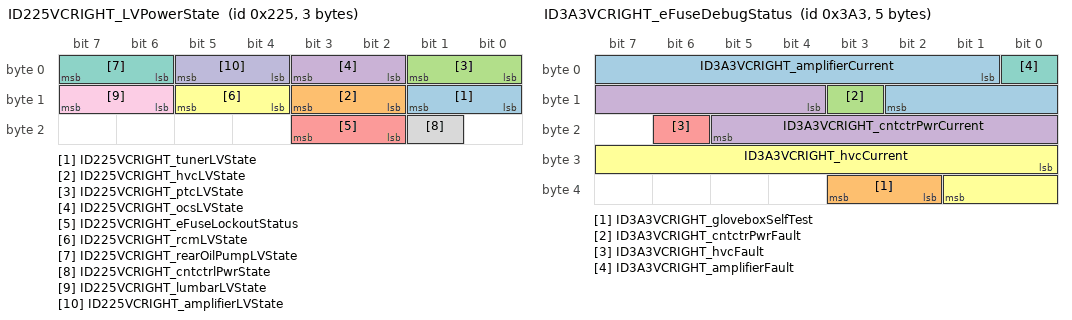
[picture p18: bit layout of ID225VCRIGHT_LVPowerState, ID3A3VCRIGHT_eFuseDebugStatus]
BO_ 549 ID225VCRIGHT_LVPowerState: 3 VehicleBus
   SG_ ID225VCRIGHT_tunerLVState : 8|2@1+ (1,0) [0|3] "" gtw
   SG_ ID225VCRIGHT_hvcLVState : 10|2@1+ (1,0) [0|3] "" gtw
   SG_ ID225VCRIGHT_ptcLVState : 0|2@1+ (1,0) [0|3] "" gtw
   SG_ ID225VCRIGHT_ocsLVState : 2|2@1+ (1,0) [0|3] "" gtw
   SG_ ID225VCRIGHT_eFuseLockoutStatus : 18|2@1+ (1,0) [0|2] "" gtw
   SG_ ID225VCRIGHT_rcmLVState : 12|2@1+ (1,0) [0|3] "" gtw
   SG_ ID225VCRIGHT_rearOilPumpLVState : 6|2@1+ (1,0) [0|3] "" gtw
   SG_ ID225VCRIGHT_cntctrlPwrState : 17|1@1+ (1,0) [0|1] "" gtw
   SG_ ID225VCRIGHT_lumbarLVState : 14|2@1+ (1,0) [0|3] "" gtw
   SG_ ID225VCRIGHT_amplifierLVState : 4|2@1+ (1,0) [0|3] "" gtw

BO_ 931 ID3A3VCRIGHT_eFuseDebugStatus: 5 VehicleBus
   SG_ ID3A3VCRIGHT_amplifierCurrent : 1|10@1+ (0.1,0) [0|102.3] "A" Vector__XXX
   SG_ ID3A3VCRIGHT_gloveboxSelfTest : 34|2@1+ (1,0) [0|3] "" gtw
   SG_ ID3A3VCRIGHT_cntctrPwrFault : 11|1@1+ (1,0) [0|1] "" Vector__XXX
   SG_ ID3A3VCRIGHT_cntctrPwrCurrent : 12|10@1+ (0.1,0) [0|102.3] "A" Vector__XXX
   SG_ ID3A3VCRIGHT_hvcFault : 22|1@1+ (1,0) [0|1] "" Vector__XXX
   SG_ ID3A3VCRIGHT_hvcCurrent : 24|10@1+ (0.1,0) [0|102.3] "A" Vector__XXX
   SG_ ID3A3VCRIGHT_amplifierFault : 0|1@1+ (1,0) [0|1] "" Vector__XXX

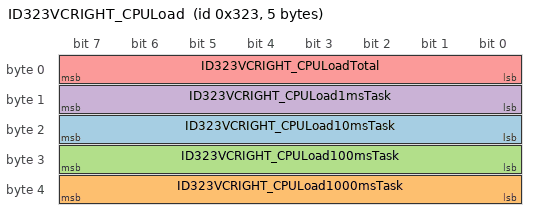
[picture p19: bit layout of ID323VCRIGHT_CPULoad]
BO_ 803 ID323VCRIGHT_CPULoad: 5 VehicleBus
   SG_ ID323VCRIGHT_CPULoad10msTask : 16|8@1+ (1,0) [0|255] "" Vector__XXX
   SG_ ID323VCRIGHT_CPULoad1000msTask : 32|8@1+ (1,0) [0|255] "" Vector__XXX
   SG_ ID323VCRIGHT_CPULoad100msTask : 24|8@1+ (1,0) [0|255] "" Vector__XXX
   SG_ ID323VCRIGHT_CPULoad1msTask : 8|8@1+ (1,0) [0|255] "" Vector__XXX
   SG_ ID323VCRIGHT_CPULoadTotal : 0|8@1+ (1,0) [0|255] "" Vector__XXX

BO_ 627 ID273UI_vehicleControl: 8 VehicleBus
   SG_ ID273UI_domeLightSwitch : 59|2@1+ (1,0) [0|2] "" Vector__XXX
   SG_ ID273UI_autoHighBeamEnabled : 41|1@1+ (1,0) [0|1] "" Vector__XXX
   SG_ ID273UI_rearRightSeatHeatReq : 50|2@1+ (1,0) [0|3] "" Vector__XXX
   SG_ ID273UI_unlockOnPark : 14|1@1+ (1,0) [0|1] "" Vector__XXX
   SG_ ID273UI_childDoorLockOn : 16|1@1+ (1,0) [0|1] "" Vector__XXX
   SG_ ID273UI_alarmEnabled : 20|1@1+ (1,0) [0|1] "" Vector__XXX
   SG_ ID273UI_summonActive : 4|1@1+ (1,0) [0|1] "" Vector__XXX
   SG_ ID273UI_seeYouHomeLightingOn : 30|1@1+ (1,0) [0|1] "" Vector__XXX
   SG_ ID273UI_steeringButtonMode : 9|3@1+ (1,0) [0|5] "" Vector__XXX
   SG_ ID273UI_mirrorHeatRequest : 26|1@1+ (1,0) [0|1] "" Vector__XXX
   SG_ ID273UI_autoFoldMirrorsOn : 52|1@1+ (1,0) [0|1] "" Vector__XXX
   SG_ ID273UI_remoteStartRequest : 27|3@1+ (1,0) [0|4] "" Vector__XXX
   SG_ ID273UI_frontFogSwitch : 3|1@1+ (1,0) [0|1] "" Vector__XXX
   SG_ ID273UI_rearWindowLockout : 63|1@1+ (1,0) [0|1] "" Vector__XXX
   SG_ ID273UI_wiperMode : 6|2@1+ (1,0) [0|3] "" Vector__XXX
   SG_ ID273UI_globalUnlockOn : 15|1@1+ (1,0) [0|1] "" Vector__XXX
   SG_ ID273UI_lockRequest : 17|3@1+ (1,0) [0|7] "" Vector__XXX
   SG_ ID273UI_frontLeftSeatHeatReq : 42|2@1+ (1,0) [0|3] "" Vector__XXX
   SG_ ID273UI_frontRightSeatHeatReq : 44|2@1+ (1,0) [0|3] "" Vector__XXX
   SG_ ID273UI_walkUpUnlock : 12|1@1+ (1,0) [0|1] "" Vector__XXX
   SG_ ID273UI_walkAwayLock : 13|1@1+ (1,0) [0|1] "" Vector__XXX
   SG_ ID273UI_remoteClosureRequest : 54|2@1+ (1,0) [0|3] "" Vector__XXX
   SG_ ID273UI_mirrorFoldRequest : 24|2@1+ (1,0) [0|3] "" Vector__XXX
   SG_ ID273UI_honkHorn : 61|1@1+ (1,0) [0|1] "" Vector__XXX
   SG_ ID273UI_accessoryPowerRequest : 0|1@1+ (1,0) [0|1] "" Vector__XXX
   SG_ ID273UI_ambientLightingEnabled : 40|1@1+ (1,0) [0|1] "" Vector__XXX
   SG_ ID273UI_wiperRequest : 56|3@1+ (1,0) [0|6] "" Vector__XXX
   SG_ ID273UI_rearFogSwitch : 23|1@1+ (1,0) [0|1] "" Vector__XXX
   SG_ ID273UI_intrusionSensorOn : 21|1@1+ (1,0) [0|1] "" Vector__XXX
   SG_ ID273UI_displayBrightnessLevel : 32|8@1+ (0.5,0) [0|127] "%" Vector__XXX
   SG_ ID273UI_mirrorDipOnReverse : 53|1@1+ (1,0) [0|1] "" Vector__XXX
   SG_ ID273UI_steeringBacklightEnabled : 8|1@1+ (1,0) [0|1] "" Vector__XXX
   SG_ ID273UI_frunkRequest : 5|1@1+ (1,0) [0|1] "" Vector__XXX
   SG_ ID273UI_rearCenterSeatHeatReq : 48|2@1+ (1,0) [0|3] "" Vector__XXX
   SG_ ID273UI_rearLeftSeatHeatReq : 46|2@1+ (1,0) [0|3] "" Vector__XXX
   SG_ ID273UI_stop12vSupport : 22|1@1+ (1,0) [0|1] "" Vector__XXX
   SG_ ID273UI_driveStateRequest : 62|1@1+ (1,0) [0|1] "" Vector__XXX

BO_ 930 ID3A2VCLEFT_status: 8 VehicleBus
   SG_ ID3A2VCLEFT_statusIndex M : 0|1@1+ (1,0) [0|1] "" Vector__XXX
   SG_ ID3A2VCLEFT_loadShedPriority m0 : 1|8@1+ (1,0) [0|255] "" Vector__XXX
   SG_ ID3A2VCLEFT_vehiclePowerStateDBG m0 : 9|2@1+ (1,0) [0|3] "" Vector__XXX
   SG_ ID3A2VCLEFT_consoleDoorAssist m0 : 11|1@1+ (1,0) [0|1] "" Vector__XXX
   SG_ ID3A2VCLEFT_OTAState m0 : 12|1@1+ (1,0) [0|1] "" Vector__XXX
   SG_ ID3A2VCLEFT_5AVoltage m0 : 13|10@1+ (0.00544368,0) [0|5.5688] "V" Vector__XXX
   SG_ ID3A2VCLEFT_vbatProt m0 : 23|12@1+ (0.00544368,0) [0|22.2919] "V" Vector__XXX
   SG_ ID3A2VCLEFT_footwellLightCurrent m0 : 35|12@1- (0.1,0) [-204.8|204.7] "mA" Vector__XXX
   SG_ ID3A2VCLEFT_swcInputVoltage m0 : 47|8@1- (0.1,0) [0|25.4] "V" Vector__XXX
   SG_ ID3A2VCLEFT_swcPCBATemperature m0 : 55|8@1- (1,0) [-40|150] "degC" Vector__XXX
   SG_ ID3A2VCLEFT_pcbaTemperature m1 : 1|8@1+ (0.125,0) [-40|150] "degC" Vector__XXX
   SG_ ID3A2VCLEFT_DIeFuseCurrent m1 : 12|12@1- (0.1,0) [-204.8|204.7] "A" Vector__XXX
   SG_ ID3A2VCLEFT_DIeFuseFault m1 : 24|1@1+ (1,0) [0|1] "" Vector__XXX
   SG_ ID3A2VCLEFT_tlcPCBATemperature m1 : 32|8@1- (1,0) [-40|150] "degC" Vector__XXX

BA_DEF_ BO_ "GenMsgCycleTime" INT 0 0;
BA_DEF_ SG_ "GenSigEnvVarType" ENUM "Cyclic","SendType1","SendType2","SendType3","SendType4","SendType5","SendType6","SendType7","SendType8","SendType9","Cyclic","SendType1","SendType2","SendType3","SendType4","SendType5","SendType6","SendType7","SendType8","SendType9","Cyclic","SendType1","SendType2","SendType3","SendType4","SendType5","SendType6","SendType7","SendType8","SendType9","Cyclic","SendType1","SendType2","SendType3","SendType4","SendType5","SendType6","SendType7","SendType8","SendType9","Cyclic","SendType1","SendType2","SendType3","SendType4","SendType5","SendType6","SendType7","SendType8","SendType9","Cyclic","SendType1","SendType2","SendType3","SendType4","SendType5","SendType6","SendType7","SendType8","SendType9","Cyclic","SendType1","SendType2","SendType3","SendType4","SendType5","SendType6","SendType7","SendType8","SendType9","No","Yes","Cyclic","SendType1","SendType2","SendType3","SendType4","SendType5","SendType6","SendType7","SendType8","SendType9","Cyclic","SendType1","SendType2","SendType3","SendType4","SendType5","SendType6","SendType7","SendType8","SendType9","Cyclic","SendType1","SendType2","SendType3","SendType4","SendType5","SendType6","SendType7","SendType8","SendType9","Cyclic","SendType1","SendType2","SendType3","SendType4","SendType5","SendType6","SendType7","SendType8","SendType9","Cyclic","SendType1","SendType2","SendType3","SendType4","SendType5","SendType6","SendType7","SendType8","SendType9","Cyclic","SendType1","SendType2","SendType3","SendType4","SendType5","SendType6","SendType7","SendType8","SendType9","No","Yes","Cyclic","SendType1","SendType2","SendType3","SendType4","SendType5","SendType6","SendType7","SendType8","SendType9","Cyclic","SendType1","SendType2","SendType3","SendType4","SendType5","SendType6","SendType7","SendType8","SendType9","Cyclic","SendType1","SendType2","SendType3","SendType4","SendType5","SendType6","SendType7","SendType8","SendType9","Cyclic","SendType1","SendType2","SendType3","SendType4","SendType5","SendType6","SendType7","SendType8","SendType9","Cyclic","SendType1","SendType2","SendType3","SendType4","SendType5","SendType6","SendType7","SendType8","SendType9","No","Yes","Cyclic","SendType1","SendType2","SendType3","SendType4","SendType5","SendType6","SendType7","SendType8","SendType9","Cyclic","SendType1","SendType2","SendType3","SendType4","SendType5","SendType6","SendType7","SendType8","SendType9","Cyclic","SendType1","SendType2","SendType3","SendType4","SendType5","SendType6","SendType7","SendType8","SendType9","Cyclic","SendType1","SendType2","SendType3","SendType4","SendType5","SendType6","SendType7","SendType8","SendType9","No","Yes","Cyclic","SendType1","SendType2","SendType3","SendType4","SendType5","SendType6","SendType7","SendType8","SendType9","Cyclic","SendType1","SendType2","SendType3","SendType4","SendType5","SendType6","SendType7","SendType8","SendType9","Cyclic","SendType1","SendType2","SendType3","SendType4","SendType5","SendType6","SendType7","SendType8","SendType9","No","Yes","Cyclic","SendType1","SendType2","SendType3","SendType4","SendType5","SendType6","SendType7","SendType8","SendType9","Cyclic","SendType1","SendType2","SendType3","SendType4","SendType5","SendType6","SendType7","SendType8","SendType9","No","Yes","Cyclic","SendType1","SendType2","SendType3","SendType4","SendType5","SendType6","SendType7","SendType8","SendType9","No","Yes","No","Yes","Cyclic","SendType1","SendType2","SendType3","SendType4","SendType5","SendType6","SendType7","SendType8","SendType9","Cyclic","SendType1","SendType2","SendType3","SendType4","SendType5","SendType6","SendType7","SendType8","SendType9","Cyclic","SendType1","SendType2","SendType3","SendType4","SendType5","SendType6","SendType7","SendType8","SendType9","Cyclic","SendType1","SendType2","SendType3","SendType4","SendType5","SendType6","SendType7","SendType8","SendType9","Cyclic","SendType1","SendType2","SendType3","SendType4","SendType5","SendType6","SendType7","SendType8","SendType9","Cyclic","SendType1","SendType2","SendType3","SendType4","SendType5","SendType6","SendType7","SendType8","SendType9","No","Yes","Cyclic","SendType1","SendType2","SendType3","SendType4","SendType5","SendType6","SendType7","SendType8","SendType9","Cyclic","SendType1","SendType2","SendType3","SendType4","SendType5","SendType6","SendType7","SendType8","SendType9","Cyclic","SendType1","SendType2","SendType3","SendType4","SendType5","SendType6","SendType7","SendType8","SendType9","Cyclic","SendType1","SendType2","SendType3","SendType4","SendType5","SendType6","SendType7","SendType8","SendType9","Cyclic","SendType1","SendType2","SendType3","SendType4","SendType5","SendType6","SendType7","SendType8","SendType9","No","Yes","Cyclic","SendType1","SendType2","SendType3","SendType4","SendType5","SendType6","SendType7","SendType8","SendType9","Cyclic","SendType1","SendType2","SendType3","SendType4","SendType5","SendType6","SendType7","SendType8","SendType9","Cyclic","SendType1","SendType2","SendType3","SendType4","SendType5","SendType6","SendType7","SendType8","SendType9","Cyclic","SendType1","SendType2","SendType3","SendType4","SendType5","SendType6","SendType7","SendType8","SendType9","No","Yes","Cyclic","SendType1","SendType2","SendType3","SendType4","SendType5","SendType6","SendType7","SendType8","SendType9","Cyclic","SendType1","SendType2","SendType3","SendType4","SendType5","SendType6","SendType7","SendType8","SendType9","Cyclic","SendType1","SendType2","SendType3","SendType4","SendType5","SendType6","SendType7","SendType8","SendType9","No","Yes","Cyclic","SendType1","SendType2","SendType3","SendType4","SendType5","SendType6","SendType7","SendType8","SendType9","Cyclic","SendType1","SendType2","SendType3","SendType4","SendType5","SendType6","SendType7","SendType8","SendType9","No","Yes","Cyclic","SendType1","SendType2","SendType3","SendType4","SendType5","SendType6","SendType7","SendType8","SendType9","No","Yes","No","Yes","Cyclic","SendType1","SendType2","SendType3","SendType4","SendType5","SendType6","SendType7","SendType8","SendType9","Cyclic","SendType1","SendType2","SendType3","SendType4","SendType5","SendType6","SendType7","SendType8","SendType9","Cyclic","SendType1","SendType2","SendType3","SendType4","SendType5","SendType6","SendType7","SendType8","SendType9","Cyclic","SendType1","SendType2","SendType3","SendType4","SendType5","SendType6","SendType7","SendType8","SendType9","Cyclic","SendType1","SendType2","SendType3","SendType4","SendType5","SendType6","SendType7","SendType8","SendType9","No","Yes","Cyclic","SendType1","SendType2","SendType3","SendType4","SendType5","SendType6","SendType7","SendType8","SendType9","Cyclic","SendType1","SendType2","SendType3","SendType4","SendType5","SendType6","SendType7","SendType8","SendType9","Cyclic","SendType1","SendType2","SendType3","SendType4","SendType5","SendType6","SendType7","SendType8","SendType9","Cyclic","SendType1","SendType2","SendType3","SendType4","SendType5","SendType6","SendType7","SendType8","SendType9","No","Yes","Cyclic","SendType1","SendType2","SendType3","SendType4","SendType5","SendType6","SendType7","SendType8","SendType9","Cyclic","SendType1","SendType2","SendType3","SendType4","SendType5","SendType6","SendType7","SendType8","SendType9","Cyclic","SendType1","SendType2","SendType3","SendType4","SendType5","SendType6","SendType7","SendType8","SendType9","No","Yes","Cyclic","SendType1","SendType2","SendType3","SendType4","SendType5","SendType6","SendType7","SendType8","SendType9","Cyclic","SendType1","SendType2","SendType3","SendType4","SendType5","SendType6","SendType7","SendType8","SendType9","No","Yes","Cyclic","SendType1","SendType2","SendType3","SendType4","SendType5","SendType6","SendType7","SendType8","SendType9","No","Yes","No","Yes","Cyclic","SendType1","SendType2","SendType3","SendType4","SendType5","SendType6","SendType7","SendType8","SendType9","Cyclic","SendType1","SendType2","SendType3","SendType4","SendType5","SendType6","SendType7","SendType8","SendType9","Cyclic","SendType1","SendType2","SendType3","SendType4","SendType5","SendType6","SendType7","SendType8","SendType9","Cyclic","SendType1","SendType2","SendType3","SendType4","SendType5","SendType6","SendType7","SendType8","SendType9","No","Yes","Cyclic","SendType1","SendType2","SendType3","SendType4","SendType5","SendType6","SendType7","SendType8","SendType9","Cyclic","SendType1","SendType2","SendType3","SendType4","SendType5","SendType6","SendType7","SendType8","SendType9","Cyclic","SendType1","SendType2","SendType3","SendType4","SendType5","SendType6","SendType7","SendType8","SendType9","No","Yes","Cyclic","SendType1","SendType2","SendType3","SendType4","SendType5","SendType6","SendType7","SendType8","SendType9","Cyclic","SendType1","SendType2","SendType3","SendType4","SendType5","SendType6","SendType7","SendType8","SendType9","No","Yes","Cyclic","SendType1","SendType2","SendType3","SendType4","SendType5","SendType6","SendType7","SendType8","SendType9","No","Yes","No","Yes","Cyclic","SendType1","SendType2","SendType3","SendType4","SendType5","SendType6","SendType7","SendType8","SendType9","Cyclic","SendType1","SendType2","SendType3","SendType4","SendType5","SendType6","SendType7","SendType8","SendType9","Cyclic","SendType1","SendType2","SendType3","SendType4","SendType5","SendType6","SendType7","SendType8","SendType9","No","Yes","Cyclic","SendType1","SendType2","SendType3","SendType4","SendType5","SendType6","SendType7","SendType8","SendType9","Cyclic","SendType1","SendType2","SendType3","SendType4","SendType5","SendType6","SendType7","SendType8","SendType9","No","Yes","Cyclic","SendType1","SendType2","SendType3","SendType4","SendType5","SendType6","SendType7","SendType8","SendType9","No","Yes","No","Yes","Cyclic","SendType1","SendType2","SendType3","SendType4","SendType5","SendType6","SendType7","SendType8","SendType9","Cyclic","SendType1","SendType2","SendType3","SendType4","SendType5","SendType6","SendType7","SendType8","SendType9","No","Yes","Cyclic","SendType1","SendType2","SendType3","SendType4","SendType5","SendType6","SendType7","SendType8","SendType9","No","Yes","No","Yes","Cyclic","SendType1","SendType2","SendType3","SendType4","SendType5","SendType6","SendType7","SendType8","SendType9","No","Yes","No","Yes","No","Yes","Cyclic","SendType1","SendType2","SendType3","SendType4","SendType5","SendType6","SendType7","SendType8","SendType9","Cyclic","SendType1","SendType2","SendType3","SendType4","SendType5","SendType6","SendType7","SendType8","SendType9","Cyclic","SendType1","SendType2","SendType3","SendType4","SendType5","SendType6","SendType7","SendType8","SendType9","Cyclic","SendType1","SendType2","SendType3","SendType4","SendType5","SendType6","SendType7","SendType8","SendType9","Cyclic","SendType1","SendType2","SendType3","SendType4","SendType5","SendType6","SendType7","SendType8","SendType9","Cyclic","SendType1","SendType2","SendType3","SendType4","SendType5","SendType6","SendType7","SendType8","SendType9","No","Yes","Cyclic","SendType1","SendType2","SendType3","SendType4","SendType5","SendType6","SendType7","SendType8","SendType9","Cyclic","SendType1","SendType2","SendType3","SendType4","SendType5","SendType6","SendType7","SendType8","SendType9","Cyclic","SendType1","SendType2","SendType3","SendType4","SendType5","SendType6","SendType7","SendType8","SendType9","Cyclic","SendType1","SendType2","SendType3","SendType4","SendType5","SendType6","SendType7","SendType8","SendType9","Cyclic","SendType1","SendType2","SendType3","SendType4","SendType5","SendType6","SendType7","SendType8","SendType9","No","Yes","Cyclic","SendType1","SendType2","SendType3","SendType4","SendType5","SendType6","SendType7","SendType8","SendType9","Cyclic","SendType1","SendType2","SendType3","SendType4","SendType5","SendType6","SendType7","SendType8","SendType9","Cyclic","SendType1","SendType2","SendType3","SendType4","SendType5","SendType6","SendType7","SendType8","SendType9","Cyclic","SendType1","SendType2","SendType3","SendType4","SendType5","SendType6","SendType7","SendType8","SendType9","No","Yes","Cyclic","SendType1","SendType2","SendType3","SendType4","SendType5","SendType6","SendType7","SendType8","SendType9","Cyclic","SendType1","SendType2","SendType3","SendType4","SendType5","SendType6","SendType7","SendType8","SendType9","Cyclic","SendType1","SendType2","SendType3","SendType4","SendType5","SendType6","SendType7","SendType8","SendType9","No","Yes","Cyclic","SendType1","SendType2","SendType3","SendType4","SendType5","SendType6","SendType7","SendType8","SendType9","Cyclic","SendType1","SendType2","SendType3","SendType4","SendType5","SendType6","SendType7","SendType8","SendType9","No","Yes","Cyclic","SendType1","SendType2","SendType3","SendType4","SendType5","SendType6","SendType7","SendType8","SendType9","No","Yes","No","Yes","Cyclic","SendType1","SendType2","SendType3","SendType4","SendType5","SendType6","SendType7","SendType8","SendType9","Cyclic","SendType1","SendType2","SendType3","SendType4","SendType5","SendType6","SendType7","SendType8","SendType9","Cyclic","SendType1","SendType2","SendType3","SendType4","SendType5","SendType6","SendType7","SendType8","SendType9","Cyclic","SendType1","SendType2","SendType3","SendType4","SendType5","SendType6","SendType7","SendType8","SendType9","Cyclic","SendType1","SendType2","SendType3","SendType4","SendType5","SendType6","SendType7","SendType8","SendType9","No","Yes","Cyclic","SendType1","SendType2","SendType3","SendType4","SendType5","SendType6","SendType7","SendType8","SendType9","Cyclic","SendType1","SendType2","SendType3","SendType4","SendType5","SendType6","SendType7","SendType8","SendType9","Cyclic","SendType1","SendType2","SendType3","SendType4","SendType5","SendType6","SendType7","SendType8","SendType9","Cyclic","SendType1","SendType2","SendType3","SendType4","SendType5","SendType6","SendType7","SendType8","SendType9","No","Yes","Cyclic","SendType1","SendType2","SendType3","SendType4","SendType5","SendType6","SendType7","SendType8","SendType9","Cyclic","SendType1","SendType2","SendType3","SendType4","SendType5","SendType6","SendType7","SendType8","SendType9","Cyclic","SendType1","SendType2","SendType3","SendType4","SendType5","SendType6","SendType7","SendType8","SendType9","No","Yes","Cyclic","SendType1","SendType2","SendType3","SendType4","SendType5","SendType6","SendType7","SendType8","SendType9","Cyclic","SendType1","SendType2","SendType3","SendType4","SendType5","SendType6","SendType7","SendType8","SendType9","No","Yes","Cyclic","SendType1","SendType2","SendType3","SendType4","SendType5","SendType6","SendType7","SendType8","SendType9","No","Yes","No","Yes","Cyclic","SendType1","SendType2","SendType3","SendType4","SendType5","SendType6","SendType7","SendType8","SendType9","Cyclic","SendType1","SendType2","SendType3","SendType4","SendType5","SendType6","SendType7","SendType8","SendType9","Cyclic","SendType1","SendType2","SendType3","SendType4","SendType5","SendType6","SendType7","SendType8","SendType9","Cyclic","SendType1","SendType2","SendType3","SendType4","SendType5","SendType6","SendType7","SendType8","SendType9","No","Yes","Cyclic","SendType1","SendType2","SendType3","SendType4","SendType5","SendType6","SendType7","SendType8","SendType9","Cyclic","SendType1","SendType2","SendType3","SendType4","SendType5","SendType6","SendType7","SendType8","SendType9","Cyclic","SendType1","SendType2","SendType3","SendType4","SendType5","SendType6","SendType7","SendType8","SendType9","No","Yes","Cyclic","SendType1","SendType2","SendType3","SendType4","SendType5","SendType6","SendType7","SendType8","SendType9","Cyclic","SendType1","SendType2","SendType3","SendType4","SendType5","SendType6","SendType7","SendType8","SendType9","No","Yes","Cyclic","SendType1","SendType2","SendType3","SendType4","SendType5","SendType6","SendType7","SendType8","SendType9","No","Yes","No","Yes","Cyclic","SendType1","SendType2","SendType3","SendType4","SendType5","SendType6","SendType7","SendType8","SendType9","Cyclic","SendType1","SendType2","SendType3","SendType4","SendType5","SendType6","SendType7","SendType8","SendType9","Cyclic","SendType1","SendType2","SendType3","SendType4","SendType5","SendType6","SendType7","SendType8","SendType9","No","Yes","Cyclic","SendType1","SendType2","SendType3","SendType4","SendType5","SendType6","SendType7","SendType8","SendType9","Cyclic","SendType1","SendType2","SendType3","SendType4","SendType5","SendType6","SendType7","SendType8","SendType9","No","Yes","Cyclic","SendType1","SendType2","SendType3","SendType4","SendType5","SendType6","SendType7","SendType8","SendType9","No","Yes","No","Yes","Cyclic","SendType1","SendType2","SendType3","SendType4","SendType5","SendType6","SendType7","SendType8","SendType9","Cyclic","SendType1","SendType2","SendType3","SendType4","SendType5","SendType6","SendType7","SendType8","SendType9","No","Yes","Cyclic","SendType1","SendType2","SendType3","SendType4","SendType5","SendType6","SendType7","SendType8","SendType9","No","Yes","No","Yes","Cyclic","SendType1","SendType2","SendType3","SendType4","SendType5","SendType6","SendType7","SendType8","SendType9","No","Yes","No","Yes","No","Yes","Cyclic","SendType1","SendType2","SendType3","SendType4","SendType5","SendType6","SendType7","SendType8","SendType9","Cyclic","SendType1","SendType2","SendType3","SendType4","SendType5","SendType6","SendType7","SendType8","SendType9","Cyclic","SendType1","SendType2","SendType3","SendType4","SendType5","SendType6","SendType7","SendType8","SendType9","Cyclic","SendType1","SendType2","SendType3","SendType4","SendType5","SendType6","SendType7","SendType8","SendType9","Cyclic","SendType1","SendType2","SendType3","SendType4","SendType5","SendType6","SendType7","SendType8","SendType9","No","Yes","Cyclic","SendType1","SendType2","SendType3","SendType4","SendType5","SendType6","SendType7","SendType8","SendType9","Cyclic","SendType1","SendType2","SendType3","SendType4","SendType5","SendType6","SendType7","SendType8","SendType9","Cyclic","SendType1","SendType2","SendType3","SendType4","SendType5","SendType6","SendType7","SendType8","SendType9","Cyclic","SendType1","SendType2","SendType3","SendType4","SendType5","SendType6","SendType7","SendType8","SendType9","No","Yes","Cyclic","SendType1","SendType2","SendType3","SendType4","SendType5","SendType6","SendType7","SendType8","SendType9","Cyclic","SendType1","SendType2","SendType3","SendType4","SendType5","SendType6","SendType7","SendType8","SendType9","Cyclic","SendType1","SendType2","SendType3","SendType4","SendType5","SendType6","SendType7","SendType8","SendType9","No","Yes","Cyclic","SendType1","SendType2","SendType3","SendType4","SendType5","SendType6","SendType7","SendType8","SendType9","Cyclic","SendType1","SendType2","SendType3","SendType4","SendType5","SendType6","SendType7","SendType8","SendType9","No","Yes","Cyclic","SendType1","SendType2","SendType3","SendType4","SendType5","SendType6","SendType7","SendType8","SendType9","No","Yes","No","Yes","Cyclic","SendType1","SendType2","SendType3","SendType4","SendType5","SendType6","SendType7","SendType8","SendType9","Cyclic","SendType1","SendType2","SendType3","SendType4","SendType5","SendType6","SendType7","SendType8","SendType9","Cyclic","SendType1","SendType2","SendType3","SendType4","SendType5","SendType6","SendType7","SendType8","SendType9","Cyclic","SendType1","SendType2","SendType3","SendType4","SendType5","SendType6","SendType7","SendType8","SendType9","No","Yes","Cyclic","SendType1","SendType2","SendType3","SendType4","SendType5","SendType6","SendType7","SendType8","SendType9","Cyclic","SendType1","SendType2","SendType3","SendType4","SendType5","SendType6","SendType7","SendType8","SendType9","Cyclic","SendType1","SendType2","SendType3","SendType4","SendType5","SendType6","SendType7","SendType8","SendType9","No","Yes","Cyclic","SendType1","SendType2","SendType3","SendType4","SendType5","SendType6","SendType7","SendType8","SendType9","Cyclic","SendType1","SendType2","SendType3","SendType4","SendType5","SendType6","SendType7","SendType8","SendType9","No","Yes","Cyclic","SendType1","SendType2","SendType3","SendType4","SendType5","SendType6","SendType7","SendType8","SendType9","No","Yes","No","Yes","Cyclic","SendType1","SendType2","SendType3","SendType4","SendType5","SendType6","SendType7","SendType8","SendType9","Cyclic","SendType1","SendType2","SendType3","SendType4","SendType5","SendType6","SendType7","SendType8","SendType9","Cyclic","SendType1","SendType2","SendType3","SendType4","SendType5","SendType6","SendType7","SendType8","SendType9","No","Yes","Cyclic","SendType1","SendType2","SendType3","SendType4","SendType5","SendType6","SendType7","SendType8","SendType9","Cyclic","SendType1","SendType2","SendType3","SendType4","SendType5","SendType6","SendType7","SendType8","SendType9","No","Yes","Cyclic","SendType1","SendType2","SendType3","SendType4","SendType5","SendType6","SendType7","SendType8","SendType9","No","Yes","No","Yes","Cyclic","SendType1","SendType2","SendType3","SendType4","SendType5","SendType6","SendType7","SendType8","SendType9","Cyclic","SendType1","SendType2","SendType3","SendType4","SendType5","SendType6","SendType7","SendType8","SendType9","No","Yes","Cyclic","SendType1","SendType2","SendType3","SendType4","SendType5","SendType6","SendType7","SendType8","SendType9","No","Yes","No","Yes","Cyclic","SendType1","SendType2","SendType3","SendType4","SendType5","SendType6","SendType7","SendType8","SendType9","No","Yes","No","Yes","No","Yes","Cyclic","SendType1","SendType2","SendType3","SendType4","SendType5","SendType6","SendType7","SendType8","SendType9","Cyclic","SendType1","SendType2","SendType3","SendType4","SendType5","SendType6","SendType7","SendType8","SendType9","Cyclic","SendType1","SendType2","SendType3","SendType4","SendType5","SendType6","SendType7","SendType8","SendType9","Cyclic","SendType1","SendType2","SendType3","SendType4","SendType5","SendType6","SendType7","SendType8","SendType9","No","Yes","Cyclic","SendType1","SendType2","SendType3","SendType4","SendType5","SendType6","SendType7","SendType8","SendType9","Cyclic","SendType1","SendType2","SendType3","SendType4","SendType5","SendType6","SendType7","SendType8","SendType9","Cyclic","SendType1","SendType2","SendType3","SendType4","SendType5","SendType6","SendType7","SendType8","SendType9","No","Yes","Cyclic","SendType1","SendType2","SendType3","SendType4","SendType5","SendType6","SendType7","SendType8","SendType9","Cyclic","SendType1","SendType2","SendType3","SendType4","SendType5","SendType6","SendType7","SendType8","SendType9","No","Yes","Cyclic","SendType1","SendType2","SendType3","SendType4","SendType5","SendType6","SendType7","SendType8","SendType9","No","Yes","No","Yes","Cyclic","SendType1","SendType2","SendType3","SendType4","SendType5","SendType6","SendType7","SendType8","SendType9","Cyclic","SendType1","SendType2","SendType3","SendType4","SendType5","SendType6","SendType7","SendType8","SendType9","Cyclic","SendType1","SendType2","SendType3","SendType4","SendType5","SendType6","SendType7","SendType8","SendType9","No","Yes","Cyclic","SendType1","SendType2","SendType3","SendType4","SendType5","SendType6","SendType7","SendType8","SendType9","Cyclic","SendType1","SendType2","SendType3","SendType4","SendType5","SendType6","SendType7","SendType8","SendType9","No","Yes","Cyclic","SendType1","SendType2","SendType3","SendType4","SendType5","SendType6","SendType7","SendType8","SendType9","No","Yes","No","Yes","Cyclic","SendType1","SendType2","SendType3","SendType4","SendType5","SendType6","SendType7","SendType8","SendType9","Cyclic","SendType1","SendType2","SendType3","SendType4","SendType5","SendType6","SendType7","SendType8","SendType9","No","Yes","Cyclic","SendType1","SendType2","SendType3","SendType4","SendType5","SendType6","SendType7","SendType8","SendType9","No","Yes","No","Yes","Cyclic","SendType1","SendType2","SendType3","SendType4","SendType5","SendType6","SendType7","SendType8","SendType9","No","Yes","No","Yes","No","Yes","Cyclic","SendType1","SendType2","SendType3","SendType4","SendType5","SendType6","SendType7","SendType8","SendType9","Cyclic","SendType1","SendType2","SendType3","SendType4","SendType5","SendType6","SendType7","SendType8","SendType9","Cyclic","SendType1","SendType2","SendType3","SendType4","SendType5","SendType6","SendType7","SendType8","SendType9","No","Yes","Cyclic","SendType1","SendType2","SendType3","SendType4","SendType5","SendType6","SendType7","SendType8","SendType9","Cyclic","SendType1","SendType2","SendType3","SendType4","SendType5","SendType6","SendType7","SendType8","SendType9","No","Yes","Cyclic","SendType1","SendType2","SendType3","SendType4","SendType5","SendType6","SendType7","SendType8","SendType9","No","Yes","No","Yes","Cyclic","SendType1","SendType2","SendType3","SendType4","SendType5","SendType6","SendType7","SendType8","SendType9","Cyclic","SendType1","SendType2","SendType3","SendType4","SendType5","SendType6","SendType7","SendType8","SendType9","No","Yes","Cyclic","SendType1","SendType2","SendType3","SendType4","SendType5","SendType6","SendType7","SendType8","SendType9","No","Yes","No","Yes","Cyclic","SendType1","SendType2","SendType3","SendType4","SendType5","SendType6","SendType7","SendType8","SendType9","No","Yes","No","Yes","No","Yes","Cyclic","SendType1","SendType2","SendType3","SendType4","SendType5","SendType6","SendType7","SendType8","SendType9","Cyclic","SendType1","SendType2","SendType3","SendType4","SendType5","SendType6","SendType7","SendType8","SendType9","No","Yes","Cyclic","SendType1","SendType2","SendType3","SendType4","SendType5","SendType6","SendType7","SendType8","SendType9","No","Yes","No","Yes","Cyclic","SendType1","SendType2","SendType3","SendType4","SendType5","SendType6","SendType7","SendType8","SendType9","No","Yes","No","Yes","No","Yes","Cyclic","SendType1","SendType2","SendType3","SendType4","SendType5","SendType6","SendType7","SendType8","SendType9","No","Yes","No","Yes","No","Yes","No","Yes","Cyclic","SendType1","SendType2","SendType3","SendType4","SendType5","SendType6","SendType7","SendType8","SendType9","Cyclic","SendType1","SendType2","SendType3","SendType4","SendType5","SendType6","SendType7","SendType8","SendType9","Cyclic","SendType1","SendType2","SendType3","SendType4","SendType5","SendType6","SendType7","SendType8","SendType9","Cyclic","SendType1","SendType2","SendType3","SendType4","SendType5","SendType6","SendType7","SendType8","SendType9","Cyclic","SendType1","SendType2","SendType3","SendType4","SendType5","SendType6","SendType7","SendType8","SendType9","Cyclic","SendType1","SendType2","SendType3","SendType4","SendType5","SendType6","SendType7","SendType8","SendType9","No","Yes","Cyclic","SendType1","SendType2","SendType3","SendType4","SendType5","SendType6","SendType7","SendType8","SendType9","Cyclic","SendType1","SendType2","SendType3","SendType4","SendType5","SendType6","SendType7","SendType8","SendType9","Cyclic","SendType1","SendType2","SendType3","SendType4","SendType5","SendType6","SendType7","SendType8","SendType9","Cyclic","SendType1","SendType2","SendType3","SendType4","SendType5","SendType6","SendType7","SendType8","SendType9","Cyclic","SendType1","SendType2","SendType3","SendType4","SendType5","SendType6","SendType7","SendType8","SendType9","No","Yes","Cyclic","SendType1","SendType2","SendType3","SendType4","SendType5","SendType6","SendType7","SendType8","SendType9","Cyclic","SendType1","SendType2","SendType3","SendType4","SendType5","SendType6","SendType7","SendType8","SendType9","Cyclic","SendType1","SendType2","SendType3","SendType4","SendType5","SendType6","SendType7","SendType8","SendType9","Cyclic","SendType1","SendType2","SendType3","SendType4","SendType5","SendType6","SendType7","SendType8","SendType9","No","Yes","Cyclic","SendType1","SendType2","SendType3","SendType4","SendType5","SendType6","SendType7","SendType8","SendType9","Cyclic","SendType1","SendType2","SendType3","SendType4","SendType5","SendType6","SendType7","SendType8","SendType9","Cyclic","SendType1","SendType2","SendType3","SendType4","SendType5","SendType6","SendType7","SendType8","SendType9","No","Yes","Cyclic","SendType1","SendType2","SendType3","SendType4","SendType5","SendType6","SendType7","SendType8","SendType9","Cyclic","SendType1","SendType2","SendType3","SendType4","SendType5","SendType6","SendType7","SendType8","SendType9","No","Yes","Cyclic","SendType1","SendType2","SendType3","SendType4","SendType5","SendType6","SendType7","SendType8","SendType9","No","Yes","No","Yes","Cyclic","SendType1","SendType2","SendType3","SendType4","SendType5","SendType6","SendType7","SendType8","SendType9","Cyclic","SendType1","SendType2","SendType3","SendType4","SendType5","SendType6","SendType7","SendType8","SendType9","Cyclic","SendType1","SendType2","SendType3","SendType4","SendType5","SendType6","SendType7","SendType8","SendType9","Cyclic","SendType1","SendType2","SendType3","SendType4","SendType5","SendType6","SendType7","SendType8","SendType9","Cyclic","SendType1","SendType2","SendType3","SendType4","SendType5","SendType6","SendType7","SendType8","SendType9","No","Yes","Cyclic","SendType1","SendType2","SendType3","SendType4","SendType5","SendType6","SendType7","SendType8","SendType9","Cyclic","SendType1","SendType2","SendType3","SendType4","SendType5","SendType6","SendType7","SendType8","SendType9","Cyclic","SendType1","SendType2","SendType3","SendType4","SendType5","SendType6","SendType7","SendType8","SendType9","Cyclic","SendType1","SendType2","SendType3","SendType4","SendType5","SendType6","SendType7","SendType8","SendType9","No","Yes","Cyclic","SendType1","SendType2","SendType3","SendType4","SendType5","SendType6","SendType7","SendType8","SendType9","Cyclic","SendType1","SendType2","SendType3","SendType4","SendType5","SendType6","SendType7","SendType8","SendType9","Cyclic","SendType1","SendType2","SendType3","SendType4","SendType5","SendType6","SendType7","SendType8","SendType9","No","Yes","Cyclic","SendType1","SendType2","SendType3","SendType4","SendType5","SendType6","SendType7","SendType8","SendType9","Cyclic","SendType1","SendType2","SendType3","SendType4","SendType5","SendType6","SendType7","SendType8","SendType9","No","Yes","Cyclic","SendType1","SendType2","SendType3","SendType4","SendType5","SendType6","SendType7","SendType8","SendType9","No","Yes","No","Yes","Cyclic","SendType1","SendType2","SendType3","SendType4","SendType5","SendType6","SendType7","SendType8","SendType9","Cyclic","SendType1","SendType2","SendType3","SendType4","SendType5","SendType6","SendType7","SendType8","SendType9","Cyclic","SendType1","SendType2","SendType3","SendType4","SendType5","SendType6","SendType7","SendType8","SendType9","Cyclic","SendType1","SendType2","SendType3","SendType4","SendType5","SendType6","SendType7","SendType8","SendType9","No","Yes","Cyclic","SendType1","SendType2","SendType3","SendType4","SendType5","SendType6","SendType7","SendType8","SendType9","Cyclic","SendType1","SendType2","SendType3","SendType4","SendType5","SendType6","SendType7","SendType8","SendType9","Cyclic","SendType1","SendType2","SendType3","SendType4","SendType5","SendType6","SendType7","SendType8","SendType9","No","Yes","Cyclic","SendType1","SendType2","SendType3","SendType4","SendType5","SendType6","SendType7","SendType8","SendType9","Cyclic","SendType1","SendType2","SendType3","SendType4","SendType5","SendType6","SendType7","SendType8","SendType9","No","Yes","Cyclic","SendType1","SendType2","SendType3","SendType4","SendType5","SendType6","SendType7","SendType8","SendType9","No","Yes","No","Yes","Cyclic","SendType1","SendType2","SendType3","SendType4","SendType5","SendType6","SendType7","SendType8","SendType9","Cyclic","SendType1","SendType2","SendType3","SendType4","SendType5","SendType6","SendType7","SendType8","SendType9","Cyclic","SendType1","SendType2","SendType3","SendType4","SendType5","SendType6","SendType7","SendType8","SendType9","No","Yes","Cyclic","SendType1","SendType2","SendType3","SendType4","SendType5","SendType6","SendType7","SendType8","SendType9","Cyclic","SendType1","SendType2","SendType3","SendType4","SendType5","SendType6","SendType7","SendType8","SendType9","No","Yes","Cyclic","SendType1","SendType2","SendType3","SendType4","SendType5","SendType6","SendType7","SendType8","SendType9","No","Yes","No","Yes","Cyclic","SendType1","SendType2","SendType3","SendType4","SendType5","SendType6","SendType7","SendType8","SendType9","Cyclic","SendType1","SendType2","SendType3","SendType4","SendType5","SendType6","SendType7","SendType8","SendType9","No","Yes","Cyclic","SendType1","SendType2","SendType3","SendType4","SendType5","SendType6","SendType7","SendType8","SendType9","No","Yes","No","Yes","Cyclic","SendType1","SendType2","SendType3","SendType4","SendType5","SendType6","SendType7","SendType8","SendType9","No","Yes","No","Yes","No","Yes","Cyclic","SendType1","SendType2","SendType3","SendType4","SendType5","SendType6","SendType7","SendType8","SendType9","Cyclic","SendType1","SendType2","SendType3","SendType4","SendType5","SendType6","SendType7","SendType8","SendType9","Cyclic","SendType1","SendType2","SendType3","SendType4","SendType5","SendType6","SendType7","SendType8","SendType9","Cyclic","SendType1","SendType2","SendType3","SendType4","SendType5","SendType6","SendType7","SendType8","SendType9","Cyclic","SendType1","SendType2","SendType3","SendType4","SendType5","SendType6","SendType7","SendType8","SendType9","No","Yes","Cyclic","SendType1","SendType2","SendType3","SendType4","SendType5","SendType6","SendType7","SendType8","SendType9","Cyclic","SendType1","SendType2","SendType3","SendType4","SendType5","SendType6","SendType7","SendType8","SendType9","Cyclic","SendType1","SendType2","SendType3","SendType4","SendType5","SendType6","SendType7","SendType8","SendType9","Cyclic","SendType1","SendType2","SendType3","SendType4","SendType5","SendType6","SendType7","SendType8","SendType9","No","Yes","Cyclic","SendType1","SendType2","SendType3","SendType4","SendType5","SendType6","SendType7","SendType8","SendType9","Cyclic","SendType1","SendType2","SendType3","SendType4","SendType5","SendType6","SendType7","SendType8","SendType9","Cyclic","SendType1","SendType2","SendType3","SendType4","SendType5","SendType6","SendType7","SendType8","SendType9","No","Yes","Cyclic","SendType1","SendType2","SendType3","SendType4","SendType5","SendType6","SendType7","SendType8","SendType9","Cyclic","SendType1","SendType2","SendType3","SendType4","SendType5","SendType6","SendType7","SendType8","SendType9","No","Yes","Cyclic","SendType1","SendType2","SendType3","SendType4","SendType5","SendType6","SendType7","SendType8","SendType9","No","Yes","No","Yes","Cyclic","SendType1","SendType2","SendType3","SendType4","SendType5","SendType6","SendType7","SendType8","SendType9","Cyclic","SendType1","SendType2","SendType3","SendType4","SendType5","SendType6","SendType7","SendType8","SendType9","Cyclic","SendType1","SendType2","SendType3","SendType4","SendType5","SendType6","SendType7","SendType8","SendType9","Cyclic","SendType1","SendType2","SendType3","SendType4","SendType5","SendType6","SendType7","SendType8","SendType9","No","Yes","Cyclic","SendType1","SendType2","SendType3","SendType4","SendType5","SendType6","SendType7","SendType8","SendType9","Cyclic","SendType1","SendType2","SendType3","SendType4","SendType5","SendType6","SendType7","SendType8","SendType9","Cyclic","SendType1","SendType2","SendType3","SendType4","SendType5","SendType6","SendType7","SendType8","SendType9","No","Yes","Cyclic","SendType1","SendType2","SendType3","SendType4","SendType5","SendType6","SendType7","SendType8","SendType9","Cyclic","SendType1","SendType2","SendType3","SendType4","SendType5","SendType6","SendType7","SendType8","SendType9","No","Yes","Cyclic","SendType1","SendType2","SendType3","SendType4","SendType5","SendType6","SendType7","SendType8","SendType9","No","Yes","No","Yes","Cyclic","SendType1","SendType2","SendType3","SendType4","SendType5","SendType6","SendType7","SendType8","SendType9","Cyclic","SendType1","SendType2","SendType3","SendType4","SendType5","SendType6","SendType7","SendType8","SendType9","Cyclic","SendType1","SendType2","SendType3","SendType4","SendType5","SendType6","SendType7","SendType8","SendType9","No","Yes","Cyclic","SendType1","SendType2","SendType3","SendType4","SendType5","SendType6","SendType7","SendType8","SendType9","Cyclic","SendType1","SendType2","SendType3","SendType4","SendType5","SendType6","SendType7","SendType8","SendType9","No","Yes","Cyclic","SendType1","SendType2","SendType3","SendType4","SendType5","SendType6","SendType7","SendType8","SendType9","No","Yes","No","Yes","Cyclic","SendType1","SendType2","SendType3","SendType4","SendType5","SendType6","SendType7","SendType8","SendType9","Cyclic","SendType1","SendType2","SendType3","SendType4","SendType5","SendType6","SendType7","SendType8","SendType9","No","Yes","Cyclic","SendType1","SendType2","SendType3","SendType4","SendType5","SendType6","SendType7","SendType8","SendType9","No","Yes","No","Yes","Cyclic","SendType1","SendType2","SendType3","SendType4","SendType5","SendType6","SendType7","SendType8","SendType9","No","Yes","No","Yes","No","Yes","Cyclic","SendType1","SendType2","SendType3","SendType4","SendType5","SendType6","SendType7","SendType8","SendType9","Cyclic","SendType1","SendType2","SendType3","SendType4","SendType5","SendType6","SendType7","SendType8","SendType9","Cyclic","SendType1","SendType2","SendType3","SendType4","SendType5","SendType6","SendType7","SendType8","SendType9","Cyclic","SendType1","SendType2","SendType3","SendType4","SendType5","SendType6","SendType7","SendType8","SendType9","No","Yes","Cyclic","SendType1","SendType2","SendType3","SendType4","SendType5","SendType6","SendType7","SendType8","SendType9","Cyclic","SendType1","SendType2","SendType3","SendType4","SendType5","SendType6","SendType7","SendType8","SendType9","Cyclic","SendType1","SendType2","SendType3","SendType4","SendType5","SendType6","SendType7","SendType8","SendType9","No","Yes","Cyclic","SendType1","SendType2","SendType3","SendType4","SendType5","SendType6","SendType7","SendType8","SendType9","Cyclic","SendType1","SendType2","SendType3","SendType4","SendType5","SendType6","SendType7","SendType8","SendType9","No","Yes","Cyclic","SendType1","SendType2","SendType3","SendType4","SendType5","SendType6","SendType7","SendType8","SendType9","No","Yes","No","Yes","Cyclic","SendType1","SendType2","SendType3","SendType4","SendType5","SendType6","SendType7","SendType8","SendType9","Cyclic","SendType1","SendType2","SendType3","SendType4","SendType5","SendType6","SendType7","SendType8","SendType9","Cyclic","SendType1","SendType2","SendType3","SendType4","SendType5","SendType6","SendType7","SendType8","SendType9","No","Yes","Cyclic","SendType1","SendType2","SendType3","SendType4","SendType5","SendType6","SendType7","SendType8","SendType9","Cyclic","SendType1","SendType2","SendType3","SendType4","SendType5","SendType6","SendType7","SendType8","SendType9","No","Yes","Cyclic","SendType1","SendType2","SendType3","SendType4","SendType5","SendType6","SendType7","SendType8","SendType9","No","Yes","No","Yes","Cyclic","SendType1","SendType2","SendType3","SendType4","SendType5","SendType6","SendType7","SendType8","SendType9","Cyclic","SendType1","SendType2","SendType3","SendType4","SendType5","SendType6","SendType7","SendType8","SendType9","No","Yes","Cyclic","SendType1","SendType2","SendType3","SendType4","SendType5","SendType6","SendType7","SendType8","SendType9","No","Yes","No","Yes","Cyclic","SendType1","SendType2","SendType3","SendType4","SendType5","SendType6","SendType7","SendType8","SendType9","No","Yes","No","Yes","No","Yes","Cyclic","SendType1","SendType2","SendType3","SendType4","SendType5","SendType6","SendType7","SendType8","SendType9","Cyclic","SendType1","SendType2","SendType3","SendType4","SendType5","SendType6","SendType7","SendType8","SendType9","Cyclic","SendType1","SendType2","SendType3","SendType4","SendType5","SendType6","SendType7","SendType8","SendType9","No","Yes","Cyclic","SendType1","SendType2","SendType3","SendType4","SendType5","SendType6","SendType7","SendType8","SendType9","Cyclic","SendType1","SendType2","SendType3","SendType4","SendType5","SendType6","SendType7","SendType8","SendType9","No","Yes","Cyclic","SendType1","SendType2","SendType3","SendType4","SendType5","SendType6","SendType7","SendType8","SendType9","No","Yes","No","Yes","Cyclic","SendType1","SendType2","SendType3","SendType4","SendType5","SendType6","SendType7","SendType8","SendType9","Cyclic","SendType1","SendType2","SendType3","SendType4","SendType5","SendType6","SendType7","SendType8","SendType9","No","Yes","Cyclic","SendType1","SendType2","SendType3","SendType4","SendType5","SendType6","SendType7","SendType8","SendType9","No","Yes","No","Yes","Cyclic","SendType1","SendType2","SendType3","SendType4","SendType5","SendType6","SendType7","SendType8","SendType9","No","Yes","No","Yes","No","Yes","Cyclic","SendType1","SendType2","SendType3","SendType4","SendType5","SendType6","SendType7","SendType8","SendType9","Cyclic","SendType1","SendType2","SendType3","SendType4","SendType5","SendType6","SendType7","SendType8","SendType9","No","Yes","Cyclic","SendType1","SendType2","SendType3","SendType4","SendType5","SendType6","SendType7","SendType8","SendType9","No","Yes","No","Yes","Cyclic","SendType1","SendType2","SendType3","SendType4","SendType5","SendType6","SendType7","SendType8","SendType9","No","Yes","No","Yes","No","Yes","Cyclic","SendType1","SendType2","SendType3","SendType4","SendType5","SendType6","SendType7","SendType8","SendType9","No","Yes","No","Yes","No","Yes","No","Yes","Cyclic","SendType1","SendType2","SendType3","SendType4","SendType5","SendType6","SendType7","SendType8","SendType9","Cyclic","SendType1","SendType2","SendType3","SendType4","SendType5","SendType6","SendType7","SendType8","SendType9","Cyclic","SendType1","SendType2","SendType3","SendType4","SendType5","SendType6","SendType7","SendType8","SendType9","Cyclic","SendType1","SendType2","SendType3","SendType4","SendType5","SendType6","SendType7","SendType8","SendType9","Cyclic","SendType1","SendType2","SendType3","SendType4","SendType5","SendType6","SendType7","SendType8","SendType9","No","Yes","Cyclic","SendType1","SendType2","SendType3","SendType4","SendType5","SendType6","SendType7","SendType8","SendType9","Cyclic","SendType1","SendType2","SendType3","SendType4","SendType5","SendType6","SendType7","SendType8","SendType9","Cyclic","SendType1","SendType2","SendType3","SendType4","SendType5","SendType6","SendType7","SendType8","SendType9","Cyclic","SendType1","SendType2","SendType3","SendType4","SendType5","SendType6","SendType7","SendType8","SendType9","No","Yes","Cyclic","SendType1","SendType2","SendType3","SendType4","SendType5","SendType6","SendType7","SendType8","SendType9","Cyclic","SendType1","SendType2","SendType3","SendType4","SendType5","SendType6","SendType7","SendType8","SendType9","Cyclic","SendType1","SendType2","SendType3","SendType4","SendType5","SendType6","SendType7","SendType8","SendType9","No","Yes","Cyclic","SendType1","SendType2","SendType3","SendType4","SendType5","SendType6","SendType7","SendType8","SendType9","Cyclic","SendType1","SendType2","SendType3","SendType4","SendType5","SendType6","SendType7","SendType8","SendType9","No","Yes","Cyclic","SendType1","SendType2","SendType3","SendType4","SendType5","SendType6","SendType7","SendType8","SendType9","No","Yes","No","Yes","Cyclic","SendType1","SendType2","SendType3","SendType4","SendType5","SendType6","SendType7","SendType8","SendType9","Cyclic","SendType1","SendType2","SendType3","SendType4","SendType5","SendType6","SendType7","SendType8","SendType9","Cyclic","SendType1","SendType2","SendType3","SendType4","SendType5","SendType6","SendType7","SendType8","SendType9","Cyclic","SendType1","SendType2","SendType3","SendType4","SendType5","SendType6","SendType7","SendType8","SendType9","No","Yes","Cyclic","SendType1","SendType2","SendType3","SendType4","SendType5","SendType6","SendType7","SendType8","SendType9","Cyclic","SendType1","SendType2","SendType3","SendType4","SendType5","SendType6","SendType7","SendType8","SendType9","Cyclic","SendType1","SendType2","SendType3","SendType4","SendType5","SendType6","SendType7","SendType8","SendType9","No","Yes","Cyclic","SendType1","SendType2","SendType3","SendType4","SendType5","SendType6","SendType7","SendType8","SendType9","Cyclic","SendType1","SendType2","SendType3","SendType4","SendType5","SendType6","SendType7","SendType8","SendType9","No","Yes","Cyclic","SendType1","SendType2","SendType3","SendType4","SendType5","SendType6","SendType7","SendType8","SendType9","No","Yes","No","Yes","Cyclic","SendType1","SendType2","SendType3","SendType4","SendType5","SendType6","SendType7","SendType8","SendType9","Cyclic","SendType1","SendType2","SendType3","SendType4","SendType5","SendType6","SendType7","SendType8","SendType9","Cyclic","SendType1","SendType2","SendType3","SendType4","SendType5","SendType6","SendType7","SendType8","SendType9","No","Yes","Cyclic","SendType1","SendType2","SendType3","SendType4","SendType5","SendType6","SendType7","SendType8","SendType9","Cyclic","SendType1","SendType2","SendType3","SendType4","SendType5","SendType6","SendType7","SendType8","SendType9","No","Yes","Cyclic","SendType1","SendType2","SendType3","SendType4","SendType5","SendType6","SendType7","SendType8","SendType9","No","Yes","No","Yes","Cyclic","SendType1","SendType2","SendType3","SendType4","SendType5","SendType6","SendType7","SendType8","SendType9","Cyclic","SendType1","SendType2","SendType3","SendType4","SendType5","SendType6","SendType7","SendType8","SendType9","No","Yes","Cyclic","SendType1","SendType2","SendType3","SendType4","SendType5","SendType6","SendType7","SendType8","SendType9","No","Yes","No","Yes","Cyclic","SendType1","SendType2","SendType3","SendType4","SendType5","SendType6","SendType7","SendType8","SendType9","No","Yes","No","Yes","No","Yes","Cyclic","SendType1","SendType2","SendType3","SendType4","SendType5","SendType6","SendType7","SendType8","SendType9","Cyclic","SendType1","SendType2","SendType3","SendType4","SendType5","SendType6","SendType7","SendType8","SendType9","Cyclic","SendType1","SendType2","SendType3","SendType4","SendType5","SendType6","SendType7","SendType8","SendType9","Cyclic","SendType1","SendType2","SendType3","SendType4","SendType5","SendType6","SendType7","SendType8","SendType9","No","Yes","Cyclic","SendType1","SendType2","SendType3","SendType4","SendType5","SendType6","SendType7","SendType8","SendType9","Cyclic","SendType1","SendType2","SendType3","SendType4","SendType5","SendType6","SendType7","SendType8","SendType9","Cyclic","SendType1","SendType2","SendType3","SendType4","SendType5","SendType6","SendType7","SendType8","SendType9","No","Yes","Cyclic","SendType1","SendType2","SendType3","SendType4","SendType5","SendType6","SendType7","SendType8","SendType9","Cyclic","SendType1","SendType2","SendType3","SendType4","SendType5","SendType6","SendType7","SendType8","SendType9","No","Yes","Cyclic","SendType1","SendType2","SendType3","SendType4","SendType5","SendType6","SendType7","SendType8","SendType9","No","Yes","No","Yes","Cyclic","SendType1","SendType2","SendType3","SendType4","SendType5","SendType6","SendType7","SendType8","SendType9","Cyclic","SendType1","SendType2","SendType3","SendType4","SendType5","SendType6","SendType7","SendType8","SendType9","Cyclic","SendType1","SendType2","SendType3","SendType4","SendType5","SendType6","SendType7","SendType8","SendType9","No","Yes","Cyclic","SendType1","SendType2","SendType3","SendType4","SendType5","SendType6","SendType7","SendType8","SendType9","Cyclic","SendType1","SendType2","SendType3","SendType4","SendType5","SendType6","SendType7","SendType8","SendType9","No","Yes","Cyclic","SendType1","SendType2","SendType3","SendType4","SendType5","SendType6","SendType7","SendType8","SendType9","No","Yes","No","Yes","Cyclic","SendType1","SendType2","SendType3","SendType4","SendType5","SendType6","SendType7","SendType8","SendType9","Cyclic","SendType1","SendType2","SendType3","SendType4","SendType5","SendType6","SendType7","SendType8","SendType9","No","Yes","Cyclic","SendType1","SendType2","SendType3","SendType4","SendType5","SendType6","SendType7","SendType8","SendType9","No","Yes","No","Yes","Cyclic","SendType1","SendType2","SendType3","SendType4","SendType5","SendType6","SendType7","SendType8","SendType9","No","Yes","No","Yes","No","Yes","Cyclic","SendType1","SendType2","SendType3","SendType4","SendType5","SendType6","SendType7","SendType8","SendType9","Cyclic","SendType1","SendType2","SendType3","SendType4","SendType5","SendType6","SendType7","SendType8","SendType9","Cyclic","SendType1","SendType2","SendType3","SendType4","SendType5","SendType6","SendType7","SendType8","SendType9","No","Yes","Cyclic","SendType1","SendType2","SendType3","SendType4","SendType5","SendType6","SendType7","SendType8","SendType9","Cyclic","SendType1","SendType2","SendType3","SendType4","SendType5","SendType6","SendType7","SendType8","SendType9","No","Yes","Cyclic","SendType1","SendType2","SendType3","SendType4","SendType5","SendType6","SendType7","SendType8","SendType9","No","Yes","No","Yes","Cyclic","SendType1","SendType2","SendType3","SendType4","SendType5","SendType6","SendType7","SendType8","SendType9","Cyclic","SendType1","SendType2","SendType3","SendType4","SendType5","SendType6","SendType7","SendType8","SendType9","No","Yes","Cyclic","SendType1","SendType2","SendType3","SendType4","SendType5","SendType6","SendType7","SendType8","SendType9","No","Yes","No","Yes","Cyclic","SendType1","SendType2","SendType3","SendType4","SendType5","SendType6","SendType7","SendType8","SendType9","No","Yes","No","Yes","No","Yes","Cyclic","SendType1","SendType2","SendType3","SendType4","SendType5","SendType6","SendType7","SendType8","SendType9","Cyclic","SendType1","SendType2","SendType3","SendType4","SendType5","SendType6","SendType7","SendType8","SendType9","No","Yes","Cyclic","SendType1","SendType2","SendType3","SendType4","SendType5","SendType6","SendType7","SendType8","SendType9","No","Yes","No","Yes","Cyclic","SendType1","SendType2","SendType3","SendType4","SendType5","SendType6","SendType7","SendType8","SendType9","No","Yes","No","Yes","No","Yes","Cyclic","SendType1","SendType2","SendType3","SendType4","SendType5","SendType6","SendType7","SendType8","SendType9","No","Yes","No","Yes","No","Yes","No","Yes","Cyclic","SendType1","SendType2","SendType3","SendType4","SendType5","SendType6","SendType7","SendType8","SendType9","Cyclic","SendType1","SendType2","SendType3","SendType4","SendType5","SendType6","SendType7","SendType8","SendType9","Cyclic","SendType1","SendType2","SendType3","SendType4","SendType5","SendType6","SendType7","SendType8","SendType9","Cyclic","SendType1","SendType2","SendType3","SendType4","SendType5","SendType6","SendType7","SendType8","SendType9","No","Yes","Cyclic","SendType1","SendType2","SendType3","SendType4","SendType5","SendType6","SendType7","SendType8","SendType9","Cyclic","SendType1","SendType2","SendType3","SendType4","SendType5","SendType6","SendType7","SendType8","SendType9","Cyclic","SendType1","SendType2","SendType3","SendType4","SendType5","SendType6","SendType7","SendType8","SendType9","No","Yes","Cyclic","SendType1","SendType2","SendType3","SendType4","SendType5","SendType6","SendType7","SendType8","SendType9","Cyclic","SendType1","SendType2","SendType3","SendType4","SendType5","SendType6","SendType7","SendType8","SendType9","No","Yes","Cyclic","SendType1","SendType2","SendType3","SendType4","SendType5","SendType6","SendType7","SendType8","SendType9","No","Yes","No","Yes","Cyclic","SendType1","SendType2","SendType3","SendType4","SendType5","SendType6","SendType7","SendType8","SendType9","Cyclic","SendType1","SendType2","SendType3","SendType4","SendType5","SendType6","SendType7","SendType8","SendType9","Cyclic","SendType1","SendType2","SendType3","SendType4","SendType5","SendType6","SendType7","SendType8","SendType9","No","Yes","Cyclic","SendType1","SendType2","SendType3","SendType4","SendType5","SendType6","SendType7","SendType8","SendType9","Cyclic","SendType1","SendType2","SendType3","SendType4","SendType5","SendType6","SendType7","SendType8","SendType9","No","Yes","Cyclic","SendType1","SendType2","SendType3","SendType4","SendType5","SendType6","SendType7","SendType8","SendType9","No","Yes","No","Yes","Cyclic","SendType1","SendType2","SendType3","SendType4","SendType5","SendType6","SendType7","SendType8","SendType9","Cyclic","SendType1","SendType2","SendType3","SendType4","SendType5","SendType6","SendType7","SendType8","SendType9","No","Yes","Cyclic","SendType1","SendType2","SendType3","SendType4","SendType5","SendType6","SendType7","SendType8","SendType9","No","Yes","No","Yes","Cyclic","SendType1","SendType2","SendType3","SendType4","SendType5","SendType6","SendType7","SendType8","SendType9","No","Yes","No","Yes","No","Yes","Cyclic","SendType1","SendType2","SendType3","SendType4","SendType5","SendType6","SendType7","SendType8","SendType9","Cyclic","SendType1","SendType2","SendType3","SendType4","SendType5","SendType6","SendType7","SendType8","SendType9","Cyclic","SendType1","SendType2","SendType3","SendType4","SendType5","SendType6","SendType7","SendType8","SendType9","No","Yes","Cyclic","SendType1","SendType2","SendType3","SendType4","SendType5","SendType6","SendType7","SendType8","SendType9","Cyclic","SendType1","SendType2","SendType3","SendType4","SendType5","SendType6","SendType7","SendType8","SendType9","No","Yes","Cyclic","SendType1","SendType2","SendType3","SendType4","SendType5","SendType6","SendType7","SendType8","SendType9","No","Yes","No","Yes","Cyclic","SendType1","SendType2","SendType3","SendType4","SendType5","SendType6","SendType7","SendType8","SendType9","Cyclic","SendType1","SendType2","SendType3","SendType4","SendType5","SendType6","SendType7","SendType8","SendType9","No","Yes","Cyclic","SendType1","SendType2","SendType3","SendType4","SendType5","SendType6","SendType7","SendType8","SendType9","No","Yes","No","Yes","Cyclic","SendType1","SendType2","SendType3","SendType4","SendType5","SendType6","SendType7","SendType8","SendType9","No","Yes","No","Yes","No","Yes","Cyclic","SendType1","SendType2","SendType3","SendType4","SendType5","SendType6","SendType7","SendType8","SendType9","Cyclic","SendType1","SendType2","SendType3","SendType4","SendType5","SendType6","SendType7","SendType8","SendType9","No","Yes","Cyclic","SendType1","SendType2","SendType3","SendType4","SendType5","SendType6","SendType7","SendType8","SendType9","No","Yes","No","Yes","Cyclic","SendType1","SendType2","SendType3","SendType4","SendType5","SendType6","SendType7","SendType8","SendType9","No","Yes","No","Yes","No","Yes","Cyclic","SendType1","SendType2","SendType3","SendType4","SendType5","SendType6","SendType7","SendType8","SendType9","No","Yes","No","Yes","No","Yes","No","Yes","Cyclic","SendType1","SendType2","SendType3","SendType4","SendType5","SendType6","SendType7","SendType8","SendType9","Cyclic","SendType1","SendType2","SendType3","SendType4","SendType5","SendType6","SendType7","SendType8","SendType9","Cyclic","SendType1","SendType2","SendType3","SendType4","SendType5","SendType6","SendType7","SendType8","SendType9","No","Yes","Cyclic","SendType1","SendType2","SendType3","SendType4","SendType5","SendType6","SendType7","SendType8","SendType9","Cyclic","SendType1","SendType2","SendType3","SendType4","SendType5","SendType6","SendType7","SendType8","SendType9","No","Yes","Cyclic","SendType1","SendType2","SendType3","SendType4","SendType5","SendType6","SendType7","SendType8","SendType9","No","Yes","No","Yes","Cyclic","SendType1","SendType2","SendType3","SendType4","SendType5","SendType6","SendType7","SendType8","SendType9","Cyclic","SendType1","SendType2","SendType3","SendType4","SendType5","SendType6","SendType7","SendType8","SendType9","No","Yes","Cyclic","SendType1","SendType2","SendType3","SendType4","SendType5","SendType6","SendType7","SendType8","SendType9","No","Yes","No","Yes","Cyclic","SendType1","SendType2","SendType3","SendType4","SendType5","SendType6","SendType7","SendType8","SendType9","No","Yes","No","Yes","No","Yes","Cyclic","SendType1","SendType2","SendType3","SendType4","SendType5","SendType6","SendType7","SendType8","SendType9","Cyclic","SendType1","SendType2","SendType3","SendType4","SendType5","SendType6","SendType7","SendType8","SendType9","No","Yes","Cyclic","SendType1","SendType2","SendType3","SendType4","SendType5","SendType6","SendType7","SendType8","SendType9","No","Yes","No","Yes","Cyclic","SendType1","SendType2","SendType3","SendType4","SendType5","SendType6","SendType7","SendType8","SendType9","No","Yes","No","Yes","No","Yes","Cyclic","SendType1","SendType2","SendType3","SendType4","SendType5","SendType6","SendType7","SendType8","SendType9","No","Yes","No","Yes","No","Yes","No","Yes","Cyclic","SendType1","SendType2","SendType3","SendType4","SendType5","SendType6","SendType7","SendType8","SendType9","Cyclic","SendType1","SendType2","SendType3","SendType4","SendType5","SendType6","SendType7","SendType8","SendType9","No","Yes","Cyclic","SendType1","SendType2","SendType3","SendType4","SendType5","SendType6","SendType7","SendType8","SendType9","No","Yes","No","Yes","Cyclic","SendType1","SendType2","SendType3","SendType4","SendType5","SendType6","SendType7","SendType8","SendType9","No","Yes","No","Yes","No","Yes","Cyclic","SendType1","SendType2","SendType3","SendType4","SendType5","SendType6","SendType7","SendType8","SendType9","No","Yes","No","Yes","No","Yes","No","Yes","Cyclic","SendType1","SendType2","SendType3","SendType4","SendType5","SendType6","SendType7","SendType8","SendType9","No","Yes","No","Yes","No","Yes","No","Yes","int","float","undef";
BA_DEF_ SG_ "SystemSignalLongSymbol" STRING ;
BA_DEF_ BO_ "SystemMessageLongSymbol" STRING ;
BA_ "SystemSignalLongSymbol" SG_ 918 FrontOilPumpOilTempEstConfident3 "FrontOilPumpOilTempEstConfident3";
BA_ "GenSigEnvVarType" SG_ 472 TorqueFlags1D8 0;
BA_ "GenMsgCycleTime" BO_ 468 10;
BA_ "GenMsgCycleTime" BO_ 741 1000;
BA_ "GenMsgCycleTime" BO_ 962 50;
BA_ "GenMsgCycleTime" BO_ 822 1000;
BA_ "GenMsgCycleTime" BO_ 659 500;
BA_ "GenMsgCycleTime" BO_ 616 100;
BA_ "GenMsgCycleTime" BO_ 79 1000;
BA_ "GenMsgCycleTime" BO_ 978 1000;
BA_ "GenMsgCycleTime" BO_ 722 100;
BA_ "GenMsgCycleTime" BO_ 1345 100;
BA_ "GenMsgCycleTime" BO_ 580 100;
BA_ "GenMsgCycleTime" BO_ 532 100;
BA_ "GenMsgCycleTime" BO_ 533 1000;
BA_ "GenMsgCycleTime" BO_ 535 1000;
BA_ "GenMsgCycleTime" BO_ 801 1000;
BA_ "SystemMessageLongSymbol" BO_ 513 "ID201VCFRONT_loggingAndVitals10Hz";
BA_ "SystemSignalLongSymbol" SG_ 513 VCFRONT_loggingAndVitals10HzInde "VCFRONT_loggingAndVitals10HzInde";
BA_ "SystemSignalLongSymbol" SG_ 513 VCFRONT_pressureRefrigDischargeV "VCFRONT_pressureRefrigDischargeV";
BA_ "SystemSignalLongSymbol" SG_ 513 VCFRONT_pressureRefrigSuctionVit "VCFRONT_pressureRefrigSuctionVit";
BA_ "GenMsgCycleTime" BO_ 984 1000;
BA_ "GenMsgCycleTime" BO_ 609 100;
BA_ "GenMsgCycleTime" BO_ 297 10;
BA_ "GenMsgCycleTime" BO_ 612 100;
BA_ "GenMsgCycleTime" BO_ 548 100;
BA_ "GenMsgCycleTime" BO_ 280 10;
BA_ "GenMsgCycleTime" BO_ 850 1000;
BA_ "GenMsgCycleTime" BO_ 594 100;
BA_ "GenMsgCycleTime" BO_ 786 1000;
BA_ "GenMsgCycleTime" BO_ 658 100;
BA_ "GenMsgCycleTime" BO_ 599 20;
BA_ "GenMsgCycleTime" BO_ 1029 205;
BA_ "GenMsgCycleTime" BO_ 886 1000;
BA_ "GenMsgCycleTime" BO_ 340 10;
BA_ "GenMsgCycleTime" BO_ 950 1000;
BA_ "GenMsgCycleTime" BO_ 614 10;
BA_ "GenMsgCycleTime" BO_ 264 10;
BA_ "GenMsgCycleTime" BO_ 306 10;
BA_ "GenMsgCycleTime" BO_ 294 100;
BA_ "GenMsgCycleTime" BO_ 799 1000;
BA_ "GenMsgCycleTime" BO_ 1022 1000;
BA_ "GenMsgCycleTime" BO_ 2047 100;
BA_DEF_DEF_ "GenMsgCycleTime" 0;
BA_DEF_DEF_ "GenSigEnvVarType" "undef";
BA_DEF_DEF_ "SystemSignalLongSymbol" "";
BA_DEF_DEF_ "SystemMessageLongSymbol" "";
CM_ SG_ 792 UTCyear318 "Year";
CM_ SG_ 792 UTCmonth318 "Month";
CM_ SG_ 792 UTCseconds318 "Seconds";
CM_ SG_ 792 UTChour318 "Hour";
CM_ SG_ 792 UTCday318 "Day";
CM_ SG_ 792 UTCminutes318 "Minute";
CM_ SG_ 1320 UnixTimeSeconds528 "Unix Time";
CM_ SG_ 390 DIF_axleSpeed "Front Axle Speed";
CM_ SG_ 390 DIF_torqueActual "Front Axle Torque";
CM_ SG_ 390 DIF_torqueCommand "Front Axle Torque Request";
CM_ BO_ 918 "swapped with 395 in old firmware";
CM_ BO_ 917 "swapped with 396 in old firmware";
CM_ SG_ 472 RearTorqueRequest1D8 "Rear Motor Torque Request";
CM_ SG_ 472 RearTorque1D8 "Rear Motor Torque";
CM_ SG_ 468 RAWTorqueFront1D4 "Front Torque Old, Axle torque 2 with 9/1 gearing";
CM_ SG_ 469 FrontTorqueRequest1D5 "Front Motor Torque Request";
CM_ SG_ 469 FrontTorque1D5 "Front Motor Torque";
CM_ SG_ 741 FrontPower2E5 "Front Motor Power";
CM_ SG_ 741 FrontPowerLimit2E5 "Front Power Limit, approx offset Orig scale 1";
CM_ SG_ 741 FrontHeatPower2E5 "Front Waste Heat Power";
CM_ SG_ 822 DriveRegenRating336 "Regen Rating";
CM_ SG_ 822 DrivePowerRating336 "Power Rating";
CM_ SG_ 616 SystemRegenPowerMax268 "Max Regen Power";
CM_ SG_ 616 SystemHeatPowerMax268 "System Max Waste Heat Power";
CM_ SG_ 616 SystemHeatPower268 "System Waste Heat Power";
CM_ SG_ 616 SystemDrivePowerMax268 "Max Drive Power";
CM_ SG_ 79 GPSLongitude04F "Longitude";
CM_ SG_ 79 GPSLatitude04F "Latitude";
CM_ SG_ 978 TotalDischargeKWh3D2 "Lifetime Discharge";
CM_ SG_ 978 TotalChargeKWh3D2 "Lifetime Charge";
CM_ SG_ 722 MinVoltage2D2 "BMS Min Voltage";
CM_ SG_ 722 MaxDischargeCurrent2D2 "BMS Max Discharge Current";
CM_ SG_ 722 MaxChargeCurrent2D2 "BMS Max Charge Current";
CM_ SG_ 722 MaxVoltage2D2 "BMS Max Voltage";
CM_ SG_ 1345 FCMaxPowerLimit541 "Supercharger Power Limit";
CM_ SG_ 1345 FCMaxCurrentLimit541 "Supercharger Current Limit";
CM_ SG_ 580 FCMinVlimit244 "Supercharger Min Voltage";
CM_ SG_ 580 FCMaxVlimit244 "Supercharger Max Voltage";
CM_ SG_ 580 FCCurrentLimit244 "Supercharger Max Current";
CM_ SG_ 580 FCPowerLimit244 "Supercharger Max Power";
CM_ SG_ 801 VCFRONT_tempAmbientFiltered "Outside Temperature";
CM_ SG_ 801 VCFRONT_tempCoolantBatInlet "Battery Coolant Temp";
CM_ SG_ 801 VCFRONT_tempCoolantPTInlet "Powertrain Coolant Temp";
CM_ SG_ 984 Elevation3D8 "Elevation";
CM_ SG_ 609 v12vBattTemp261 "12V Battery Temp";
CM_ SG_ 609 v12vBattAH261 "12V Battery Capacity";
CM_ SG_ 609 v12vBattCurrent261 "12V Battery Current";
CM_ SG_ 609 v12vBattVoltage261 "12V Battery Voltage";
CM_ SG_ 297 SteeringSpeed129 "Steering Speed";
CM_ SG_ 297 SteeringAngle129 "Steering Angle";
CM_ SG_ 612 ChargeLinePower264 "Charger Line Power";
CM_ SG_ 612 ChargeLineCurrentLimit264 "Charge Connector Current Limit";
CM_ SG_ 612 ChargeLineVoltage264 "Charger Line Voltage";
CM_ SG_ 612 ChargeLineCurrent264 "Charger Line Current";
CM_ SG_ 548 DCDCoutputCurrent224 "DCDC Output Current";
CM_ SG_ 280 DI_accelPedalPos "Pedal Position";
CM_ SG_ 280 DI_brakePedalState "Brake Pedal";
CM_ SG_ 280 DI_gear "Gear";
CM_ SG_ 280 DI_regenLight "Regen Brake";
CM_ SG_ 280 DI_tractionControlMode "Traction Control Mode";
CM_ SG_ 850 BMS_energyBuffer "Battery Buffer kWh";
CM_ SG_ 850 BMS_energyToChargeComplete "Charge Remaining kWh";
CM_ SG_ 850 BMS_fullChargeComplete "Charge Complete";
CM_ SG_ 850 BMS_nominalEnergyRemaining "Batt Remaining kWh";
CM_ SG_ 850 BMS_nominalFullPackEnergy "Batt Full kWh";
CM_ SG_ 594 BMS_hvacPowerBudget "BMS Max HVAC Power";
CM_ SG_ 594 BMS_maxDischargePower "BMS Max Discharge Power";
CM_ SG_ 594 BMS_maxRegenPower "BMS Max Regen Power";
CM_ SG_ 594 BMS_maxStationaryHeatPower "BMS Max Waste Heat Power";
CM_ SG_ 786 BMSdissipation312 "Battery Dissipation";
CM_ SG_ 786 BMSinletActiveCoolTarget312 "Battery Cool Target";
CM_ SG_ 786 BMSinletActiveHeatTarget312 "Battery Heat Target";
CM_ SG_ 786 BMSmaxPackTemperature "Max Battery Temp";
CM_ SG_ 786 BMSminPackTemperature "Min Battery Temp";
CM_ SG_ 658 BattBeginningOfLifeEnergy292 "HV Battery Original Energy";
CM_ SG_ 658 SOCmax292 "BMS Max SOC";
CM_ SG_ 658 SOCave292 "BMS Ave SOC";
CM_ SG_ 658 SOCmin292 "BMS Min SOC";
CM_ SG_ 599 UIspeedUnits257 "Speed Units, 0-mph 1-kph";
CM_ SG_ 599 UIspeed_signed257 "Vehicle Speed, .05 -25 for mph";
CM_ SG_ 599 UIspeed_abs257 "UI Speed";
CM_ SG_ 599 UISpeedHighSpeed257 "UIHi Speed";
CM_ SG_ 1029 VINB405 "VIN3, last 7 of VIN (ASCII)";
CM_ SG_ 1029 VINC405 "VIN2, part two of VIN (ASCII)";
CM_ SG_ 1029 VINA405 "VIN1, four zeros then first 3 characters of VIN";
CM_ SG_ 886 TempStator376 "Front Stator Temp";
CM_ SG_ 789 RearTempStator315 "Rear Stator Temp";
CM_ SG_ 340 RAWTorqueRear154 "Rear Torque Old, Axle torque 2 with 9/1 gearing";
CM_ SG_ 950 Odometer3B6 "Odometer";
CM_ SG_ 614 RearPowerLimit266 "Rear Power Limit, approx offset Orig scale 1";
CM_ SG_ 614 RearHeatPower266 "Rear Waste Heat Power";
CM_ SG_ 614 RearPower266 "Rear Motor Power";
CM_ SG_ 264 DIR_axleSpeed "Rear Axle Speed";
CM_ SG_ 264 DIR_torqueActual "Rear Axle Torque";
CM_ SG_ 264 DIR_torqueCommand "Rear Axle Torque Request";
CM_ SG_ 306 ChargeHoursRemaining132 "Charge Time Remaining";
CM_ SG_ 306 BattVoltage132 "HV Battery Voltage";
CM_ SG_ 306 RawBattCurrent132 "HV Raw Current, old offset 1000";
CM_ SG_ 306 SmoothBattCurrent132 "HV Battery Current";
CM_ SG_ 294 RearHighVoltage126 "Rear Motor Voltage";
CM_ SG_ 294 RearMotorCurrent126 "Rear Motor Current";
CM_ SG_ 421 FrontHighVoltage1A5 "Front Motor Voltage";
CM_ SG_ 421 FrontMotorCurrent1A5 "Front Motor Current";
CM_ BO_ 1022 "Brake Temps Estimated";
CM_ SG_ 2047 GTW_chassisType "Model";
CM_ SG_ 2047 GTW_packEnergy "Battery Pack Size";
CM_ SG_ 818 BattCellTempMax332 "Max Batt Brick Temp";
CM_ SG_ 818 BattCellTempMin332 "Min Batt Brick Temp";
CM_ SG_ 818 BattCellBrickVoltageMax332 "Max Batt Brick V";
CM_ SG_ 818 BattCellBrickVoltageMin332 "Min Batt Brick V";
VAL_ 553 GearLeverPosition229 4 "Full Up" 3 "Half Up" 2 "Full Down" 1 "Half Down" 0 "Center";
VAL_ 585 SCCM_highBeamStalkStatus 0 "IDLE" 1 "PULL" 2 "PUSH" 3 "SNA";
VAL_ 585 SCCM_turnIndicatorStalkStatus 5 "DOWN_0_5" 6 "DOWN_1" 7 "DOWN_1_5" 8 "DOWN_2" 0 "IDLE" 9 "SNA" 1 "UP_0_5" 2 "UP_1" 3 "UP_1_5" 4 "UP_2";
VAL_ 585 SCCM_washWipeButtonStatus 1 "1ST_DETENT" 2 "2ND_DETENT" 0 "NOT_PRESSED" 3 "SNA";
VAL_ 390 DIF_axleSpeed 32768 "SNA";
VAL_ 390 DIF_slavePedalPos 255 "SNA";
VAL_ 390 DIF_torqueActual 4096 "SNA";
VAL_ 390 DIF_torqueCommand 4096 "SNA";
VAL_ 918 FrontOilPumpState396 7 "OIL_PUMP_SNA" 6 "OIL_PUMP_FAULTED" 2 "OIL_PUMP_COLD_STARTUP" 1 "OIL_PUMP_ENABLE" 0 "OIL_PUMP_STANDBY";
VAL_ 917 DIR_oilPumpFluidTQF 1 "OIL_PUMP_FLUIDT_HIGH_CONFIDENCE" 0 "OIL_PUMP_FLUIDT_LOW_CONFIDENCE";
VAL_ 917 DIR_oilPumpState 2 "OIL_PUMP_COLD_STARTUP" 1 "OIL_PUMP_ENABLE" 6 "OIL_PUMP_FAULTED" 7 "OIL_PUMP_SNA" 0 "OIL_PUMP_STANDBY";
VAL_ 341 ESP_WheelRotationReR 3 "WR_NOT_DEFINABLE" 2 "WR_STANDSTILL" 1 "WR_BACKWARD" 0 "WR_FORWARD";
VAL_ 341 ESP_WheelRotationReL 3 "WR_NOT_DEFINABLE" 2 "WR_STANDSTILL" 1 "WR_BACKWARD" 0 "WR_FORWARD";
VAL_ 341 ESP_WheelRotationFrR 3 "WR_NOT_DEFINABLE" 2 "WR_STANDSTILL" 1 "WR_BACKWARD" 0 "WR_FORWARD";
VAL_ 341 ESP_WheelRotationFrL 3 "WR_NOT_DEFINABLE" 2 "WR_STANDSTILL" 1 "WR_BACKWARD" 0 "WR_FORWARD";
VAL_ 341 ESP_wheelSpeedsQF 1 "ALL_WSS_VALID" 0 "ONE_OR_MORE_WSS_INVALID";
VAL_ 341 ESP_vehicleStandstillSts 1 "STANDSTILL" 0 "NOT_STANDSTILL";
VAL_ 341 ESP_vehicleSpeed 1023 "ESP_VEHICLE_SPEED_SNA";
VAL_ 373 WheelSpeedRR175 8191 "SNA";
VAL_ 373 WheelSpeedRL175 8191 "SNA";
VAL_ 373 WheelSpeedFR175 8191 "SNA";
VAL_ 373 WheelSpeedFL175 8191 "SNA";
VAL_ 389 ESP_brakeTorqueFrL 4095 "SNA";
VAL_ 389 ESP_brakeTorqueFrR 4095 "SNA";
VAL_ 389 ESP_brakeTorqueReL 4095 "SNA";
VAL_ 389 ESP_brakeTorqueReR 4095 "SNA";
VAL_ 389 ESP_brakeTorqueQF 1 "IN_SPEC" 0 "UNDEFINABLE_ACCURACY";
VAL_ 962 VCLEFT_switchStatusIndex 0 "VCLEFT_SWITCH_STATUS_INDEX_0" 1 "VCLEFT_SWITCH_STATUS_INDEX_1" 2 "VCLEFT_SWITCH_STATUS_INDEX_INVALID";
VAL_ 962 VCLEFT_frontBuckleSwitch 3 "SWITCH_FAULT" 1 "SWITCH_OFF" 2 "SWITCH_ON" 0 "SWITCH_SNA";
VAL_ 962 VCLEFT_frontOccupancySwitch 3 "SWITCH_FAULT" 1 "SWITCH_OFF" 2 "SWITCH_ON" 0 "SWITCH_SNA";
VAL_ 962 VCLEFT_frontSeatBackrestBack 3 "SWITCH_FAULT" 1 "SWITCH_OFF" 2 "SWITCH_ON" 0 "SWITCH_SNA";
VAL_ 962 VCLEFT_frontSeatBackrestForward 3 "SWITCH_FAULT" 1 "SWITCH_OFF" 2 "SWITCH_ON" 0 "SWITCH_SNA";
VAL_ 962 VCLEFT_frontSeatLiftDown 3 "SWITCH_FAULT" 1 "SWITCH_OFF" 2 "SWITCH_ON" 0 "SWITCH_SNA";
VAL_ 962 VCLEFT_frontSeatLiftUp 3 "SWITCH_FAULT" 1 "SWITCH_OFF" 2 "SWITCH_ON" 0 "SWITCH_SNA";
VAL_ 962 VCLEFT_frontSeatLumbarDown 3 "SWITCH_FAULT" 1 "SWITCH_OFF" 2 "SWITCH_ON" 0 "SWITCH_SNA";
VAL_ 962 VCLEFT_frontSeatLumbarIn 3 "SWITCH_FAULT" 1 "SWITCH_OFF" 2 "SWITCH_ON" 0 "SWITCH_SNA";
VAL_ 962 VCLEFT_frontSeatLumbarOut 3 "SWITCH_FAULT" 1 "SWITCH_OFF" 2 "SWITCH_ON" 0 "SWITCH_SNA";
VAL_ 962 VCLEFT_frontSeatLumbarUp 3 "SWITCH_FAULT" 1 "SWITCH_OFF" 2 "SWITCH_ON" 0 "SWITCH_SNA";
VAL_ 962 VCLEFT_frontSeatTiltDown 3 "SWITCH_FAULT" 1 "SWITCH_OFF" 2 "SWITCH_ON" 0 "SWITCH_SNA";
VAL_ 962 VCLEFT_frontSeatTiltUp 3 "SWITCH_FAULT" 1 "SWITCH_OFF" 2 "SWITCH_ON" 0 "SWITCH_SNA";
VAL_ 962 VCLEFT_frontSeatTrackBack 3 "SWITCH_FAULT" 1 "SWITCH_OFF" 2 "SWITCH_ON" 0 "SWITCH_SNA";
VAL_ 962 VCLEFT_frontSeatTrackForward 3 "SWITCH_FAULT" 1 "SWITCH_OFF" 2 "SWITCH_ON" 0 "SWITCH_SNA";
VAL_ 962 VCLEFT_rearCenterBuckleSwitch 3 "SWITCH_FAULT" 1 "SWITCH_OFF" 2 "SWITCH_ON" 0 "SWITCH_SNA";
VAL_ 962 VCLEFT_rearCenterOccupancySwitch 3 "SWITCH_FAULT" 1 "SWITCH_OFF" 2 "SWITCH_ON" 0 "SWITCH_SNA";
VAL_ 962 VCLEFT_rearLeftBuckleSwitch 3 "SWITCH_FAULT" 1 "SWITCH_OFF" 2 "SWITCH_ON" 0 "SWITCH_SNA";
VAL_ 962 VCLEFT_rearLeftOccupancySwitch 3 "SWITCH_FAULT" 1 "SWITCH_OFF" 2 "SWITCH_ON" 0 "SWITCH_SNA";
VAL_ 962 VCLEFT_rearRightOccupancySwitch 3 "SWITCH_FAULT" 1 "SWITCH_OFF" 2 "SWITCH_ON" 0 "SWITCH_SNA";
VAL_ 962 VCLEFT_rightMirrorTilt 1 "MIRROR_TILT_DOWN" 4 "MIRROR_TILT_LEFT" 3 "MIRROR_TILT_RIGHT" 0 "MIRROR_TILT_STOP" 2 "MIRROR_TILT_UP";
VAL_ 962 VCLEFT_swcLeftPressed 3 "SWITCH_FAULT" 1 "SWITCH_OFF" 2 "SWITCH_ON" 0 "SWITCH_SNA";
VAL_ 962 VCLEFT_swcLeftTiltLeft 3 "SWITCH_FAULT" 1 "SWITCH_OFF" 2 "SWITCH_ON" 0 "SWITCH_SNA";
VAL_ 962 VCLEFT_swcLeftTiltRight 3 "SWITCH_FAULT" 1 "SWITCH_OFF" 2 "SWITCH_ON" 0 "SWITCH_SNA";
VAL_ 962 VCLEFT_swcRightPressed 3 "SWITCH_FAULT" 1 "SWITCH_OFF" 2 "SWITCH_ON" 0 "SWITCH_SNA";
VAL_ 962 VCLEFT_swcRightTiltLeft 3 "SWITCH_FAULT" 1 "SWITCH_OFF" 2 "SWITCH_ON" 0 "SWITCH_SNA";
VAL_ 962 VCLEFT_swcRightTiltRight 3 "SWITCH_FAULT" 1 "SWITCH_OFF" 2 "SWITCH_ON" 0 "SWITCH_SNA";
VAL_ 659 UI_accOvertakeEnable 0 "ACC_OVERTAKE_OFF" 1 "ACC_OVERTAKE_ON" 3 "SNA";
VAL_ 659 UI_aebEnable 0 "AEB_OFF" 1 "AEB_ON" 3 "SNA";
VAL_ 659 UI_aesEnable 0 "AES_OFF" 1 "AES_ON" 3 "SNA";
VAL_ 659 UI_ahlbEnable 0 "AHLB_OFF" 1 "AHLB_ON" 3 "SNA";
VAL_ 659 UI_autoLaneChangeEnable 0 "OFF" 1 "ON" 3 "SNA";
VAL_ 659 UI_autoParkRequest 7 "ABORT" 8 "COMPLETE" 0 "NONE" 5 "PARALLEL_PULL_OUT_TO_LEFT" 6 "PARALLEL_PULL_OUT_TO_RIGHT" 2 "PARK_LEFT_CROSS" 1 "PARK_LEFT_PARALLEL" 4 "PARK_RIGHT_CROSS" 3 "PARK_RIGHT_PARALLEL" 10 "PAUSE" 11 "RESUME" 9 "SEARCH" 15 "SNA";
VAL_ 659 UI_bsdEnable 0 "BSD_OFF" 1 "BSD_ON" 3 "SNA";
VAL_ 659 UI_distanceUnits 0 "DISTANCEUNITS_KM" 1 "DISTANCEUNITS_MILES";
VAL_ 659 UI_fcwEnable 0 "FCW_OFF" 1 "FCW_ON" 3 "SNA";
VAL_ 659 UI_fcwSensitivity 1 "AEB_SENSITIVITY_AVERAGE" 0 "AEB_SENSITIVITY_EARLY" 2 "AEB_SENSITIVITY_LATE" 3 "SNA";
VAL_ 659 UI_latControlEnable 0 "LATERAL_CONTROL_OFF" 1 "LATERAL_CONTROL_ON" 3 "LATERAL_CONTROL_SNA" 2 "LATERAL_CONTROL_UNAVAILABLE";
VAL_ 659 UI_ldwEnable 1 "LDW_TRIGGERS_HAPTIC" 0 "NO_HAPTIC" 3 "SNA";
VAL_ 659 UI_parkBrakeRequest 0 "PARK_BRAKE_REQUEST_IDLE" 1 "PARK_BRAKE_REQUEST_PRESSED" 3 "PARK_BRAKE_REQUEST_SNA";
VAL_ 659 UI_pedalSafetyEnable 0 "PEDAL_SAFETY_OFF" 1 "PEDAL_SAFETY_ON" 3 "SNA";
VAL_ 659 UI_redLightStopSignEnable 0 "RLSSW_OFF" 1 "RLSSW_ON" 3 "SNA";
VAL_ 659 UI_selfParkTune 15 "SNA";
VAL_ 659 UI_steeringTuneRequest 0 "STEERING_TUNE_COMFORT" 2 "STEERING_TUNE_SPORT" 1 "STEERING_TUNE_STANDARD";
VAL_ 659 UI_tractionControlMode 2 "TC_DEV_MODE_1_SELECTED" 3 "TC_DEV_MODE_2_SELECTED" 5 "TC_DYNO_MODE_SELECTED" 0 "TC_NORMAL_SELECTED" 6 "TC_OFFROAD_ASSIST_SELECTED" 4 "TC_ROLLS_MODE_SELECTED" 1 "TC_SLIP_START_SELECTED";
VAL_ 659 UI_trailerMode 0 "TRAILER_MODE_OFF" 1 "TRAILER_MODE_ON";
VAL_ 659 UI_winchModeRequest 1 "WINCH_MODE_ENTER" 2 "WINCH_MODE_EXIT" 0 "WINCH_MODE_IDLE";
VAL_ 659 UI_zeroSpeedConfirmed 0 "ZERO_SPEED_CANCELED" 1 "ZERO_SPEED_CONFIRMED" 3 "ZERO_SPEED_SNA" 2 "ZERO_SPEED_UNUSED";
VAL_ 616 DI_primaryUnitSiliconType 1 "IGBT" 0 "MOSFET";
VAL_ 532 FC_postID 2 "FC_POST_ID_2" 3 "FC_POST_ID_SNA" 0 "FC_POST_MASTER" 1 "FC_POST_SLAVE";
VAL_ 532 FC_statusCode 3 "FC_STATUS_DEPRECATED_3" 4 "FC_STATUS_DEPRECATED_4" 6 "FC_STATUS_EXT_ISOACTIVE" 5 "FC_STATUS_INT_ISOACTIVE" 14 "FC_STATUS_MALFUNCTION" 15 "FC_STATUS_NODATA" 13 "FC_STATUS_NOTCOMPATIBLE" 0 "FC_STATUS_NOTREADY_SNA" 7 "FC_STATUS_POST_OUT_OF_SERVICE" 1 "FC_STATUS_READY" 2 "FC_STATUS_UPDATE_IN_PROGRESS";
VAL_ 532 FC_type 3 "FC_TYPE_CC_EVSE" 1 "FC_TYPE_CHADEMO" 4 "FC_TYPE_COMBO" 2 "FC_TYPE_GB" 5 "FC_TYPE_MC_EVSE" 6 "FC_TYPE_OTHER" 7 "FC_TYPE_SNA" 0 "FC_TYPE_SUPERCHARGER";
VAL_ 535 FCclass217 2 "UrbanSC" 1 "Supercharger" 0 "err";
VAL_ 535 FCbrand217 1 "Tesla" 0 "err";
VAL_ 535 FCcoolingType217 2 "Liquid" 1 "Convection" 0 "err";
VAL_ 801 VCFRONT_brakeFluidLevel 1 "LOW" 2 "NORMAL" 0 "SNA";
VAL_ 801 VCFRONT_coolantLevel 1 "FILLED" 0 "NOT_OK";
VAL_ 801 VCFRONT_tempAmbient 0 "SNA";
VAL_ 801 VCFRONT_tempAmbientFiltered 0 "SNA";
VAL_ 801 VCFRONT_tempCoolantBatInlet 1023 "SNA";
VAL_ 801 VCFRONT_tempCoolantPTInlet 2047 "SNA";
VAL_ 801 VCFRONT_washerFluidLevel 1 "LOW" 2 "NORMAL" 0 "SNA";
VAL_ 769 VCFRONT_infoIndex 13 "BC_INFO_APP_CRC" 17 "BC_INFO_APP_GITHASH" 15 "BC_INFO_BOOTLOADER_CRC" 18 "BC_INFO_BOOTLOADER_GITHASH" 14 "BC_INFO_BOOTLOADER_SVN" 10 "BC_INFO_BUILD_HWID_COMPONENTID" 0 "BC_INFO_DEPRECATED_0" 1 "BC_INFO_DEPRECATED_1" 2 "BC_INFO_DEPRECATED_2" 3 "BC_INFO_DEPRECATED_3" 4 "BC_INFO_DEPRECATED_4" 5 "BC_INFO_DEPRECATED_5" 6 "BC_INFO_DEPRECATED_6" 7 "BC_INFO_DEPRECATED_7" 8 "BC_INFO_DEPRECATED_8" 9 "BC_INFO_DEPRECATED_9" 255 "BC_INFO_END" 11 "BC_INFO_PCBAID_ASSYID_USAGEID" 16 "BC_INFO_SUBCOMPONENT1" 23 "BC_INFO_SUBCOMPONENT2" 24 "BC_INFO_SUBCOMPONENT3" 31 "BC_INFO_SUBCOMPONENT4" 32 "BC_INFO_SUBCOMPONENT5" 33 "BC_INFO_SUBCOMPONENT6" 20 "BC_INFO_UDS_PROTOCOL_BOOTCRC" 19 "BC_INFO_VERSION_DEPRECATED";
VAL_ 769 VCFRONT_infoAssemblyId 1 "ASSEMBLY1" 255 "ASSEMBLY_SNA";
VAL_ 769 VCFRONT_infoBuildType 2 "INFO_LOCAL_BUILD" 4 "INFO_MFG_BUILD" 1 "INFO_PLATFORM_BUILD" 3 "INFO_TRACEABLE_CI_BUILD" 0 "INFO_UNKNOWN_BUILD";
VAL_ 513 VCFRONT_loggingAndVitals10HzInde 7 "END" 3 "EXV_FLOW" 5 "EXV_FLOW_TARGET" 6 "EXV_STATE" 4 "HP_STATE" 2 "STATES_AND_SENSORS" 0 "TARGETS_AND_ACTUALS_0" 1 "TARGETS_SENSORS_AND_ACTUALS_1";
VAL_ 513 VCFRONT_cclExvState 4 "FAULTED" 2 "INIT_CLOSE" 8 "INIT_CLOSE_OVERDRIVE" 1 "INIT_OPEN" 6 "OVERDRIVING_SHUT" 3 "READY" 7 "READY_SHUT" 0 "UNINIT" 5 "WAIT";
VAL_ 513 VCFRONT_ccrExvState 4 "FAULTED" 2 "INIT_CLOSE" 8 "INIT_CLOSE_OVERDRIVE" 1 "INIT_OPEN" 6 "OVERDRIVING_SHUT" 3 "READY" 7 "READY_SHUT" 0 "UNINIT" 5 "WAIT";
VAL_ 513 VCFRONT_chillerExvState 4 "FAULTED" 2 "INIT_CLOSE" 8 "INIT_CLOSE_OVERDRIVE" 1 "INIT_OPEN" 6 "OVERDRIVING_SHUT" 3 "READY" 7 "READY_SHUT" 0 "UNINIT" 5 "WAIT";
VAL_ 513 VCFRONT_compressorState 3 "FAULT" 1 "READY" 2 "RUNNING" 0 "STANDBY";
VAL_ 513 VCFRONT_coolantValveMode 3 "AMBIENT_SOURCE" 2 "BLEND" 1 "PARALLEL" 0 "SERIES";
VAL_ 513 VCFRONT_evapExvState 4 "FAULTED" 2 "INIT_CLOSE" 8 "INIT_CLOSE_OVERDRIVE" 1 "INIT_OPEN" 6 "OVERDRIVING_SHUT" 3 "READY" 7 "READY_SHUT" 0 "UNINIT" 5 "WAIT";
VAL_ 513 VCFRONT_exvState 4 "FAULTED" 2 "INIT_CLOSE" 8 "INIT_CLOSE_OVERDRIVE" 1 "INIT_OPEN" 6 "OVERDRIVING_SHUT" 3 "READY" 7 "READY_SHUT" 0 "UNINIT" 5 "WAIT";
VAL_ 513 VCFRONT_hpBatteryLoadType 2 "BATT_COOL" 1 "BATT_HEAT" 0 "NONE";
VAL_ 513 VCFRONT_hpBlendType 2 "HP_FULL" 0 "HP_NONE" 1 "HP_PARTIAL";
VAL_ 513 VCFRONT_hpCabinLoadType 1 "CC" 3 "EVAP" 0 "NONE" 2 "REHEAT";
VAL_ 513 VCFRONT_hpDominantLoad 5 "CC" 2 "CHILLER" 1 "EVAP" 6 "HIGH_BOTH" 4 "LCC" 3 "LOW_BOTH" 0 "NONE";
VAL_ 513 VCFRONT_hpHighSideHX 3 "BOTH" 2 "CC" 1 "LCC" 0 "NONE";
VAL_ 513 VCFRONT_hpLowSideHX 3 "BOTH" 1 "CHILLER" 2 "EVAP" 0 "NONE";
VAL_ 513 VCFRONT_hpReqCoolantMode 4 "AMBIENT_SOURCE" 0 "ANY" 3 "PARALLEL" 2 "SERIES_BYPASS" 1 "SERIES_NO_BYPASS";
VAL_ 513 VCFRONT_lccExvState 4 "FAULTED" 2 "INIT_CLOSE" 8 "INIT_CLOSE_OVERDRIVE" 1 "INIT_OPEN" 6 "OVERDRIVING_SHUT" 3 "READY" 7 "READY_SHUT" 0 "UNINIT" 5 "WAIT";
VAL_ 513 VCFRONT_pressureRefrigDischargeV 255 "SNA";
VAL_ 513 VCFRONT_pressureRefrigLiquid 255 "SNA";
VAL_ 513 VCFRONT_pressureRefrigSuctionVit 127 "SNA";
VAL_ 513 VCFRONT_pumpBatteryRPMActual 1023 "SNA";
VAL_ 513 VCFRONT_pumpPowertrainRPMActual 1023 "SNA";
VAL_ 513 VCFRONT_radiatorFanRPMActual 1023 "SNA";
VAL_ 513 VCFRONT_recircExvState 4 "FAULTED" 2 "INIT_CLOSE" 8 "INIT_CLOSE_OVERDRIVE" 1 "INIT_OPEN" 6 "OVERDRIVING_SHUT" 3 "READY" 7 "READY_SHUT" 0 "UNINIT" 5 "WAIT";
VAL_ 513 VCFRONT_solenoidEvapState 2 "CLOSED" 3 "FAULTED" 1 "OPENED" 0 "UNDEFINED";
VAL_ 513 VCFRONT_tempRefrigDischarge 2047 "SNA";
VAL_ 513 VCFRONT_tempRefrigLiquid 2047 "SNA";
VAL_ 513 VCFRONT_tempSuperheatActual 1023 "SNA";
VAL_ 548 DCDCstate224 6 "Error" 5 "Shutdown" 4 "HVactive" 3 "Precharge" 2 "PrechargeStart" 1 "12vChg" 0 "Idle";
VAL_ 548 DCDCSubState224 0 "PWR_UP_INIT" 1 "STANDBY" 2 "12V_SUPPORT_ACTIVE" 3 "DIS_HVBUS" 4 "PCHG_FAST_DIS_HVBUS" 5 "PCHG_SLOW_DIS_HVBUS" 6 "PCHG_DWELL_CHARGE" 7 "PCHG_DWELL_WAIT" 8 "PCHG_DI_RECOVERY_WAIT" 9 "PCHG_ACTIVE" 10 "PCHG_FLT_FAST_DIS_HVBUS" 11 "SHUTDOWN" 12 "12V_SUPPORT_FAULTED" 13 "DIS_HVBUS_FAULTED" 14 "PCHG_FAULTED" 15 "CLEAR_FAULTS" 16 "FAULTED" 17 "NUM";
VAL_ 280 DI_accelPedalPos 255 "SNA";
VAL_ 280 DI_brakePedalState 2 "INVALID" 0 "OFF" 1 "ON";
VAL_ 280 DI_driveBlocked 1 "DRIVE_BLOCKED_FRUNK" 0 "DRIVE_BLOCKED_NONE" 2 "DRIVE_BLOCKED_PROX";
VAL_ 280 DI_epbRequest 0 "DI_EPBREQUEST_NO_REQUEST" 1 "DI_EPBREQUEST_PARK" 2 "DI_EPBREQUEST_UNPARK";
VAL_ 280 DI_gear 4 "DI_GEAR_D" 0 "DI_GEAR_INVALID" 3 "DI_GEAR_N" 1 "DI_GEAR_P" 2 "DI_GEAR_R" 7 "DI_GEAR_SNA";
VAL_ 280 DI_immobilizerState 2 "DI_IMM_STATE_AUTHENTICATING" 3 "DI_IMM_STATE_DISARMED" 6 "DI_IMM_STATE_FAULT" 4 "DI_IMM_STATE_IDLE" 0 "DI_IMM_STATE_INIT_SNA" 1 "DI_IMM_STATE_REQUEST" 5 "DI_IMM_STATE_RESET";
VAL_ 280 DI_keepDrivePowerStateRequest 1 "KEEP_ALIVE" 0 "NO_REQUEST";
VAL_ 280 DI_systemState 4 "DI_SYS_ABORT" 5 "DI_SYS_ENABLE" 3 "DI_SYS_FAULT" 1 "DI_SYS_IDLE" 2 "DI_SYS_STANDBY" 0 "DI_SYS_UNAVAILABLE";
VAL_ 280 DI_trackModeState 1 "TRACK_MODE_AVAILABLE" 2 "TRACK_MODE_ON" 0 "TRACK_MODE_UNAVAILABLE";
VAL_ 280 DI_tractionControlMode 6 "Offroad Assist" 5 "Dyno Mode" 4 "Rolls Mode" 3 "Dev2" 2 "Dev1" 1 "Slip Start" 0 "Standard";
VAL_ 850 BMS_energyBuffer 255 "SNA";
VAL_ 850 BMS_energyToChargeComplete 2047 "SNA";
VAL_ 850 BMS_expectedEnergyRemaining 2047 "SNA";
VAL_ 850 BMS_idealEnergyRemaining 2047 "SNA";
VAL_ 850 BMS_nominalEnergyRemaining 2047 "SNA";
VAL_ 850 BMS_nominalFullPackEnergy 2047 "SNA";
VAL_ 594 BMS_powerLimitsState 1 "POWER_CALCULATED_FOR_DRIVE" 0 "POWER_NOT_CALCULATED_FOR_DRIVE";
VAL_ 658 BattBeginningOfLifeEnergy292 1023 "SNA";
VAL_ 658 BMS_battTempPct 255 "SNA";
VAL_ 599 UIspeedUnits257 1 "KPH" 0 "MPH";
VAL_ 680 CMPD_state 3 "CMPD_STATE_FAULT" 4 "CMPD_STATE_IDLE" 0 "CMPD_STATE_INIT" 1 "CMPD_STATE_RUNNING" 15 "CMPD_STATE_SNA" 2 "CMPD_STATE_STANDBY";
VAL_ 680 CMPD_wasteHeatState 1 "CMPD_WASTE_HEAT_STATE_ACTIVE" 2 "CMPD_WASTE_HEAT_STATE_NOT_AVAILABLE" 0 "CMPD_WASTE_HEAT_STATE_OFF" 3 "CMPD_WASTE_HEAT_STATE_UNUSED";
VAL_ 886 DIF_inverterTQF 0 "INVERTERT_INIT" 1 "INVERTERT_IRRATIONAL" 2 "INVERTERT_RATIONAL" 3 "INVERTERT_UNKNOWN";
VAL_ 789 DIR_inverterTQF 0 "INVERTERT_INIT" 1 "INVERTERT_IRRATIONAL" 2 "INVERTERT_RATIONAL" 3 "INVERTERT_UNKNOWN";
VAL_ 950 Odometer3B6 4294967 "SNA";
VAL_ 264 DIR_axleSpeed 32768 "SNA";
VAL_ 264 DIR_slavePedalPos 255 "SNA";
VAL_ 264 DIR_torqueActual 4096 "SNA";
VAL_ 264 DIR_torqueCommand 4096 "SNA";
VAL_ 552 EPBResmCaliperRequest228 3 "disengaging" 2 "engaging" 1 "idle";
VAL_ 552 EPBResmOperationTrigger228 22 "SuperPark" 6 "Released" 1 "ParkEngaged";
VAL_ 552 EPBRunitStatus228 10 "Disengaging" 8 "Engaging" 3 "ParkEngaged" 1 "DriveReleased";
VAL_ 648 EPBLesmCaliperRequest288 3 "disengaging" 2 "engaging" 1 "idle";
VAL_ 648 EPBLesmOperationTrigger288 22 "SuperPark" 6 "Released" 1 "ParkEngaged";
VAL_ 648 EPBLunitStatus288 10 "Disengaging" 8 "Engaging" 3 "ParkEngaged" 1 "DriveReleased";
VAL_ 2047 GTW_CabinBlowerCtrlType 0 "LV8907" 1 "TMS320F28027F";
VAL_ 2047 GTW_activeHighBeam 1 "ACTIVE" 0 "NOT_ACTIVE";
VAL_ 2047 GTW_airSuspension 0 "NONE" 2 "TESLA_ADAPTIVE" 1 "TESLA_STANDARD";
VAL_ 2047 GTW_airbagCutoffSwitch 0 "CUTOFF_SWITCH_DISABLED" 1 "CUTOFF_SWITCH_ENABLED";
VAL_ 2047 GTW_audioType 0 "BASE" 2 "BASE_WITH_PREMIUM200" 1 "PREMIUM";
VAL_ 2047 GTW_autopilot 4 "BASIC" 2 "ENHANCED" 1 "HIGHWAY" 0 "NONE" 3 "SELF_DRIVING";
VAL_ 2047 GTW_autopilotCameraType 0 "RCCB_CAMERAS";
VAL_ 2047 GTW_auxParkLamps 2 "EU" 0 "NA_BASE" 1 "NA_PREMIUM" 3 "NONE";
VAL_ 2047 GTW_bPillarNFCParam 0 "MODEL_3" 1 "MODEL_Y";
VAL_ 2047 GTW_brakeHWType 1 "BREMBO_LARGE_P42_BREMBO_44MOC" 3 "BREMBO_LARGE_P42_BREMBO_LARGE_44MOC" 2 "BREMBO_LARGE_P42_MANDO_43MOC" 0 "BREMBO_P42_MANDO_43MOC";
VAL_ 2047 GTW_brakeLineSwitchType 0 "DI_VC_SHARED" 1 "VC_ONLY";
VAL_ 2047 GTW_cabinPTCHeaterType 0 "BORGWARNER" 1 "NONE";
VAL_ 2047 GTW_chassisType 2 "MODEL_3_CHASSIS" 0 "MODEL_S_CHASSIS" 1 "MODEL_X_CHASSIS" 3 "MODEL_Y_CHASSIS";
VAL_ 2047 GTW_compressorType 1 "DENSO_41CC" 0 "HANON_33CC";
VAL_ 2047 GTW_connectivityPackage 0 "BASE" 1 "PREMIUM";
VAL_ 2047 GTW_coolantPumpType 0 "DUAL" 1 "SINGLE_PUMP_BATT";
VAL_ 2047 GTW_dasHw 3 "PARKER_PASCAL_2_5" 4 "TESLA_AP3";
VAL_ 2047 GTW_deliveryStatus 1 "DELIVERED" 0 "NOT_DELIVERED";
VAL_ 2047 GTW_drivetrainType 1 "AWD" 0 "RWD";
VAL_ 2047 GTW_eBuckConfig 1 "DEV_BUCK" 0 "NONE";
VAL_ 2047 GTW_eCallEnabled 0 "DISABLED" 1 "ENABLED_OHC_SOS" 2 "ENABLED_UI_SOS";
VAL_ 2047 GTW_efficiencyPackage 0 "DEFAULT" 2 "M3_LR_2020" 3 "M3_LR_PERFORMANCE_2020" 1 "M3_SR_PLUS_2020";
VAL_ 2047 GTW_epasType 0 "MANDO_VGR69_GEN3";
VAL_ 2047 GTW_espValveType 0 "UNKNOWN" 1 "VALVE_TYPE_1" 2 "VALVE_TYPE_2";
VAL_ 2047 GTW_exteriorColor 5 "DEEP_BLUE" 3 "MIDNIGHT_SILVER" 6 "PEARL_WHITE" 0 "RED_MULTICOAT" 2 "SILVER_METALLIC" 1 "SOLID_BLACK";
VAL_ 2047 GTW_frontFogLamps 1 "INSTALLED" 0 "NOT_INSTALLED";
VAL_ 2047 GTW_frontSeatHeaters 1 "KONGSBERG_LOW_POWER" 0 "NONE";
VAL_ 2047 GTW_frontSeatReclinerHardware 3 "LEFT_RIGHT_SEAT_REDUCED_RANGE" 2 "LEFT_SEAT_REDUCED_RANGE" 1 "RIGHT_SEAT_REDUCED_RANGE" 0 "STANDARD_RANGE";
VAL_ 2047 GTW_frontSeatType 0 "BASE_TESLA" 3 "PREMIUM_L_TESLA_R_YANFENG" 2 "PREMIUM_L_YANFENG_R_TESLA" 1 "PREMIUM_TESLA" 4 "PREMIUM_YANFENG";
VAL_ 2047 GTW_headlamps 0 "BASE" 1 "PREMIUM";
VAL_ 2047 GTW_headlightLevelerType 1 "GEN1" 0 "NONE";
VAL_ 2047 GTW_heatedWipers 0 "FALSE" 1 "TRUE";
VAL_ 2047 GTW_homelinkType 1 "HOMELINK_V_OPT_2" 0 "NONE";
VAL_ 2047 GTW_hvacPanelVaneType 1 "CONVERGENT_V1" 0 "PARALLEL_V1";
VAL_ 2047 GTW_hvacQuietSnorkelType 0 "DEFAULT" 1 "QUIET_V1";
VAL_ 2047 GTW_ibstWakeType 0 "NONE" 1 "WAKE_PIN_20";
VAL_ 2047 GTW_immersiveAudio 1 "BASE" 0 "DISABLED" 2 "PREMIUM";
VAL_ 2047 GTW_interiorLighting 0 "BASE" 1 "PREMIUM" 2 "PREMIUM_NO_POCKET_LIGHT";
VAL_ 2047 GTW_intrusionSensorType 0 "NOT_INSTALLED" 1 "VODAFONE";
VAL_ 2047 GTW_loggingVersion 0 "MESSAGE_BASED" 1 "SIGNAL_BASED";
VAL_ 2047 GTW_lumbarECUType 1 "ALFMEIER" 0 "NONE";
VAL_ 2047 GTW_m3FrontOverheadConsoleType 1 "BITRON" 0 "VALEO";
VAL_ 2047 GTW_mapRegion 4 "AU" 3 "CN" 1 "EU" 9 "HK" 5 "JP" 7 "KR" 8 "ME" 10 "MO" 2 "NONE" 6 "TW" 0 "US";
VAL_ 2047 GTW_memoryMirrors 0 "NOT_INSTALLED" 1 "SMR";
VAL_ 2047 GTW_numberHVILNodes 0 "HVIL_NODES_0" 1 "HVIL_NODES_1" 2 "HVIL_NODES_2" 3 "HVIL_NODES_3" 4 "HVIL_NODES_4" 5 "HVIL_NODES_5";
VAL_ 2047 GTW_packEnergy 3 "PACK_100_KWH" 0 "PACK_50_KWH" 2 "PACK_62_KWH" 1 "PACK_74_KWH" 4 "PACK_75_KWH";
VAL_ 2047 GTW_packMassDeviation 0 "NO_DEVIATION" 1 "PACK_DEVIATION_1";
VAL_ 2047 GTW_passengerAirbagType 2 "EUROW" 0 "FULL_SUPPRESSION" 1 "SAFETY_VENT";
VAL_ 2047 GTW_passengerOccupancySensorType 0 "OCS" 1 "RESISTIVE_PAD";
VAL_ 2047 GTW_pedestrianWarningSound 0 "NONE" 1 "SPEAKER";
VAL_ 2047 GTW_performancePackage 0 "BASE" 3 "BASE_PLUS" 4 "BASE_PLUS_AWD" 2 "LUDICROUS" 1 "PERFORMANCE";
VAL_ 2047 GTW_plcSupportType 2 "NATIVE_CHARGE_PORT" 0 "NONE" 1 "ONBOARD_ADAPTER";
VAL_ 2047 GTW_powerSteeringColumn 0 "NOT_INSTALLED" 1 "TK";
VAL_ 2047 GTW_radarHeaterType 1 "BECKER_THIN_3M" 0 "NONE";
VAL_ 2047 GTW_rearDriveUnitType 0 "LARGE_REAR" 1 "SMALL_REAR";
VAL_ 2047 GTW_rearFogLamps 1 "INSTALLED" 0 "NOT_INSTALLED";
VAL_ 2047 GTW_rearGlassType 0 "NX" 1 "TSA5_NOPET";
VAL_ 2047 GTW_rearLightType 1 "EU_CN" 0 "NA";
VAL_ 2047 GTW_rearSeatHeaters 1 "KONGSBERG_LOW_POWER" 0 "NONE";
VAL_ 2047 GTW_refrigerantType 0 "Default" 2 "R1234YF" 1 "R134A";
VAL_ 2047 GTW_restraintsHardwareType 22 "EUROW_ECALL_M3" 33 "EUROW_ECALL_MY" 23 "EUROW_NO_ECALL_M3" 34 "EUROW_NO_ECALL_MY" 21 "NA_M3" 32 "NA_MY" 31 "NA_MY_OLD";
VAL_ 2047 GTW_rightHandDrive 0 "LEFT" 1 "RIGHT";
VAL_ 2047 GTW_roofGlassType 0 "TSA3_PET" 1 "TSA5_NOPET";
VAL_ 2047 GTW_roofType 1 "FIXED_GLASS" 0 "METAL" 2 "PANORAMIC";
VAL_ 2047 GTW_softRange 1 "RANGE_220_MILES" 2 "RANGE_93_MILES" 0 "STANDARD";
VAL_ 2047 GTW_spoilerType 0 "NOT_INSTALLED" 1 "PASSIVE";
VAL_ 2047 GTW_steeringColumnUJointType 0 "B_SAMPLE_PHASING" 1 "C_SAMPLE_PHASING";
VAL_ 2047 GTW_superchargingAccess 1 "ALLOWED" 0 "NOT_ALLOWED" 2 "PAY_AS_YOU_GO";
VAL_ 2047 GTW_tireType 4 "CONTI_ALL_SEASON_19" 17 "GOODYEAR_ALL_SEASON_20" 3 "HANKOOK_SUMMER_19" 1 "MICHELIN_ALL_SEASON_18" 19 "MICHELIN_ALL_SEASON_21" 2 "MICHELIN_SUMMER_18" 5 "MICHELIN_SUMMER_20" 18 "PIRELLI_SUMMER_21" 0 "UNKNOWN";
VAL_ 2047 GTW_towPackage 0 "NONE" 1 "TESLA_REV1";
VAL_ 2047 GTW_tpmsType 0 "CONTI_2" 1 "TESLA_BLE";
VAL_ 2047 GTW_trackModePackage 0 "NONE" 1 "PERFORMANCE";
VAL_ 2047 GTW_twelveVBatteryType 0 "ATLASBX_B24_FLOODED" 1 "CLARIOS_B24_FLOODED";
VAL_ 2047 GTW_vdcType 0 "BOSCH_VDC" 1 "TESLA_VDC";
VAL_ 2047 GTW_wheelType 4 "GEMINI_19_SQUARE" 5 "GEMINI_19_STAGGERED" 0 "PINWHEEL_18" 18 "PINWHEEL_18_CAP_KIT" 1 "STILETTO_19" 2 "STILETTO_20" 14 "STILETTO_20_DARK_SQUARE" 3 "STILETTO_20_DARK_STAGGERED" 19 "ZEROG_20_GUNPOWDER" 17 "APOLLO_19_SILVER" 20 "APOLLO_19_SILVER_CAP_KIT" 15 "INDUCTION_20_BLACK" 16 "UBERTURBINE_21_BLACK";
VAL_ 2047 GTW_windshieldType 1 "EASTMAN_ACOUSTIC" 0 "SEKISUI_ACOUSTIC";
VAL_ 2047 GTW_xcpESP 0 "FALSE" 1 "TRUE";
VAL_ 2047 GTW_xcpIbst 0 "FALSE" 1 "TRUE";
VAL_ 549 ID225VCRIGHT_tunerLVState 0 "LV_OFF" 1 "LV_ON" 2 "LV_GOING_DOWN" 3 "LV_FAULT";
VAL_ 549 ID225VCRIGHT_hvcLVState 0 "LV_OFF" 1 "LV_ON" 2 "LV_GOING_DOWN" 3 "LV_FAULT";
VAL_ 549 ID225VCRIGHT_ptcLVState 0 "LV_OFF" 1 "LV_ON" 2 "LV_GOING_DOWN" 3 "LV_FAULT";
VAL_ 549 ID225VCRIGHT_ocsLVState 0 "LV_OFF" 1 "LV_ON" 2 "LV_GOING_DOWN" 3 "LV_FAULT";
VAL_ 549 ID225VCRIGHT_eFuseLockoutStatus 0 "EFUSE_LOCKOUT_STATUS_IDLE" 1 "EFUSE_LOCKOUT_STATUS_PENDING" 2 "EFUSE_LOCKOUT_STATUS_ACTIVE";
VAL_ 549 ID225VCRIGHT_rcmLVState 0 "LV_OFF" 1 "LV_ON" 2 "LV_GOING_DOWN" 3 "LV_FAULT";
VAL_ 549 ID225VCRIGHT_rearOilPumpLVState 0 "LV_OFF" 1 "LV_ON" 2 "LV_GOING_DOWN" 3 "LV_FAULT";
VAL_ 549 ID225VCRIGHT_lumbarLVState 0 "LV_OFF" 1 "LV_ON" 2 "LV_GOING_DOWN" 3 "LV_FAULT";
VAL_ 549 ID225VCRIGHT_amplifierLVState 0 "LV_OFF" 1 "LV_ON" 2 "LV_GOING_DOWN" 3 "LV_FAULT";
VAL_ 931 ID3A3VCRIGHT_gloveboxSelfTest 0 "GLOVEBOX_EFUSE_TESTSTATE_INIT" 1 "GLOVEBOX_EFUSE_TESTSTATE_RUN" 2 "GLOVEBOX_EFUSE_TESTSTATE_COMPLETE" 3 "GLOVEBOX_EFUSE_TESTSTATE_FAIL";
VAL_ 803 ID323VCRIGHT_CPULoad1000msTask 255 "SNA";
VAL_ 803 ID323VCRIGHT_CPULoad100msTask 255 "SNA";
VAL_ 803 ID323VCRIGHT_CPULoad1msTask 255 "SNA";
VAL_ 803 ID323VCRIGHT_CPULoadTotal 255 "SNA";
VAL_ 627 ID273UI_domeLightSwitch 0 "DOME_LIGHT_SWITCH_OFF" 1 "DOME_LIGHT_SWITCH_ON" 2 "DOME_LIGHT_SWITCH_AUTO";
VAL_ 627 ID273UI_autoHighBeamEnabled 0 "";
VAL_ 627 ID273UI_rearRightSeatHeatReq 0 "HEATER_REQUEST_OFF" 1 "HEATER_REQUEST_LEVEL1" 2 "HEATER_REQUEST_LEVEL2" 3 "HEATER_REQUEST_LEVEL3" 0 "";
VAL_ 627 ID273UI_steeringButtonMode 0 "STEERING_BUTTON_MODE_OFF" 1 "STEERING_BUTTON_MODE_STEERING_COLUMN_ADJ" 2 "STEERING_BUTTON_MODE_MIRROR_LEFT" 3 "STEERING_BUTTON_MODE_MIRROR_RIGHT" 4 "STEERING_BUTTON_MODE_HEADLIGHT_LEFT" 5 "STEERING_BUTTON_MODE_HEADLIGHT_RIGHT";
VAL_ 627 ID273UI_remoteStartRequest 0 "UI_REMOTE_START_REQUEST_IDLE" 1 "UI_REMOTE_START_REQUEST_START" 4 "UI_REMOTE_START_REQUEST_SNA";
VAL_ 627 ID273UI_wiperMode 0 "WIPER_MODE_SNA" 1 "WIPER_MODE_SERVICE" 2 "WIPER_MODE_NORMAL" 3 "WIPER_MODE_PARK";
VAL_ 627 ID273UI_lockRequest 0 "UI_LOCK_REQUEST_IDLE" 1 "UI_LOCK_REQUEST_LOCK" 2 "UI_LOCK_REQUEST_UNLOCK" 3 "UI_LOCK_REQUEST_REMOTE_UNLOCK" 4 "UI_LOCK_REQUEST_REMOTE_LOCK" 7 "UI_LOCK_REQUEST_SNA";
VAL_ 627 ID273UI_frontLeftSeatHeatReq 0 "HEATER_REQUEST_OFF" 1 "HEATER_REQUEST_LEVEL1" 2 "HEATER_REQUEST_LEVEL2" 3 "HEATER_REQUEST_LEVEL3" 0 "";
VAL_ 627 ID273UI_frontRightSeatHeatReq 0 "HEATER_REQUEST_OFF" 1 "HEATER_REQUEST_LEVEL1" 2 "HEATER_REQUEST_LEVEL2" 3 "HEATER_REQUEST_LEVEL3" 0 "";
VAL_ 627 ID273UI_remoteClosureRequest 0 "UI_REMOTE_CLOSURE_REQUEST_IDLE" 1 "UI_REMOTE_CLOSURE_REQUEST_REAR_TRUNK_MOVE" 2 "UI_REMOTE_CLOSURE_REQUEST_FRONT_TRUNK_MOVE" 3 "UI_REMOTE_CLOSURE_REQUEST_SNA";
VAL_ 627 ID273UI_mirrorFoldRequest 0 "MIRROR_FOLD_REQUEST_IDLE" 1 "MIRROR_FOLD_REQUEST_RETRACT" 2 "MIRROR_FOLD_REQUEST_PRESENT" 3 "MIRROR_FOLD_REQUEST_SNA";
VAL_ 627 ID273UI_wiperRequest 0 "WIPER_REQUEST_SNA" 1 "WIPER_REQUEST_OFF" 2 "WIPER_REQUEST_AUTO" 3 "WIPER_REQUEST_SLOW_INTERMITTENT" 4 "WIPER_REQUEST_FAST_INTERMITTENT" 5 "WIPER_REQUEST_SLOW_CONTINUOUS" 6 "WIPER_REQUEST_FAST_CONTINUOUS";
VAL_ 627 ID273UI_displayBrightnessLevel 255 "SNA";
VAL_ 627 ID273UI_steeringBacklightEnabled 0 "STEERING_BACKLIGHT_DISABLED" 1 "STEERING_BACKLIGHT_ENABLED";
VAL_ 627 ID273UI_rearCenterSeatHeatReq 0 "HEATER_REQUEST_OFF" 1 "HEATER_REQUEST_LEVEL1" 2 "HEATER_REQUEST_LEVEL2" 3 "HEATER_REQUEST_LEVEL3" 0 "";
VAL_ 627 ID273UI_rearLeftSeatHeatReq 0 "HEATER_REQUEST_OFF" 1 "HEATER_REQUEST_LEVEL1" 2 "HEATER_REQUEST_LEVEL2" 3 "HEATER_REQUEST_LEVEL3" 0 "";
VAL_ 627 ID273UI_driveStateRequest 0 "DRIVE_STATE_REQ_IDLE" 1 "DRIVE_STATE_REQ_START";
VAL_ 930 ID3A2VCLEFT_vehiclePowerStateDBG 0 "VEHICLE_POWER_STATE_OFF" 1 "VEHICLE_POWER_STATE_CONDITIONING" 2 "VEHICLE_POWER_STATE_ACCESSORY" 3 "VEHICLE_POWER_STATE_DRIVE";
